VERSION ""

NS_ :

BS_:

BU_: HIB SaGE CBC DASM DIAGNOST EBCM ECM EPSB ESC ESL HALF HCP IC OCM ORC PTS RF_HUB SCCM

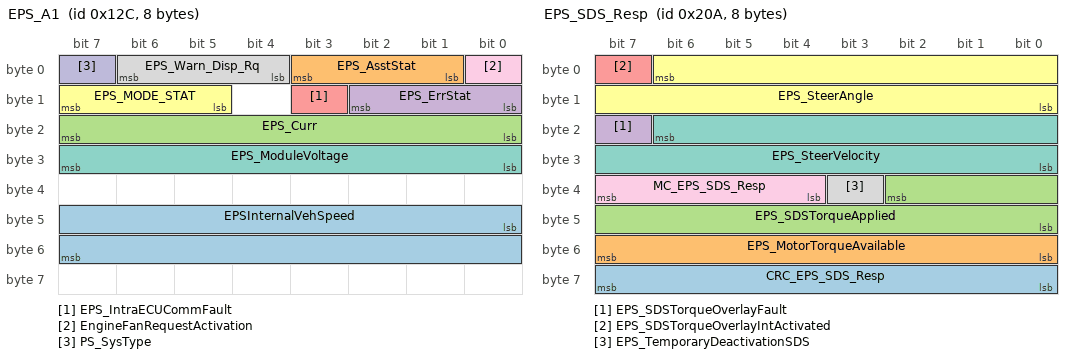
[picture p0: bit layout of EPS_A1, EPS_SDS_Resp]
BO_ 300 EPS_A1: 8 EPSB
 SG_ EPSInternalVehSpeed : 40|16@1+ (0.0078125,0) [0|511.984375] "km/h" Vector__XXX
 SG_ EPS_AsstStat : 1|3@1+ (1,0) [0|0] ""  ESC
 SG_ EPS_Curr : 16|8@1+ (1,-50) [-50|204] "Amp" Vector__XXX
 SG_ EPS_ErrStat : 8|3@1+ (1,0) [0|0] "" Vector__XXX
 SG_ EPS_IntraECUCommFault : 11|1@1+ (1,0) [0|0] "" Vector__XXX
 SG_ EPS_MODE_STAT : 13|3@1+ (1,0) [0|0] ""  CBC,HALF,ORC
 SG_ EPS_ModuleVoltage : 24|8@1+ (0.1,0) [0|25.4] "Volts" Vector__XXX
 SG_ EPS_Warn_Disp_Rq : 4|3@1+ (1,0) [0|0] ""  CBC,IC,ORC
 SG_ EngineFanRequestActivation : 0|1@1+ (1,0) [0|0] ""  ECM
 SG_ PS_SysType : 7|1@1+ (1,0) [0|0] ""  CBC,ESC

BO_ 522 EPS_SDS_Resp: 8 EPSB
 SG_ CRC_EPS_SDS_Resp : 56|8@1+ (1,0) [0|255] "" Vector__XXX
 SG_ EPS_MotorTorqueAvailable : 48|8@1+ (0.0196078,0) [0|4.9803812] "Nm" Vector__XXX
 SG_ EPS_SDSTorqueApplied : 34|11@0+ (0.00488281,-5) [-5|4.99022926] "Nm" Vector__XXX
 SG_ EPS_SDSTorqueOverlayFault : 23|1@1+ (1,0) [0|0] "" Vector__XXX
 SG_ EPS_SDSTorqueOverlayIntActivated : 7|1@1+ (1,0) [0|0] "" Vector__XXX
 SG_ EPS_SteerAngle : 6|15@0+ (0.1,-1638.3) [-1638.3|1638.3] "deg" Vector__XXX
 SG_ EPS_SteerVelocity : 22|15@0+ (0.1,-1638.3) [-1638.3|1638.3] "deg/s" Vector__XXX
 SG_ EPS_TemporaryDeactivationSDS : 35|1@1+ (1,0) [0|0] "" Vector__XXX
 SG_ MC_EPS_SDS_Resp : 36|4@1+ (1,0) [0|15] "" Vector__XXX

BO_ 320 ESP_A1: 8 ESC
 SG_ ABS_BrkEvt : 14|1@1+ (1,0) [0|0] ""  DASM,HALF,ORC,PTS
 SG_ BrkIntrvntn_Actv_AS : 6|1@1+ (1,0) [0|0] ""  DASM
 SG_ BrkIntrvntn_Actv_ESP : 5|1@1+ (1,0) [0|0] ""  HALF,ORC,PTS
 SG_ BrkIntrvntn_Enbl : 7|1@1+ (1,0) [0|0] ""  ECM,ORC
 SG_ BrkPdl_Flt : 4|1@1+ (1,0) [0|0] ""  DASM,ECM,HALF
 SG_ BrkPdl_Stat : 2|2@1+ (1,0) [0|0] ""  CBC,DASM,ECM,HALF,HCP,ORC,RF_HUB
 SG_ Brk_Stat : 0|2@1+ (1,0) [0|0] ""  CBC,DASM,ECM,HALF,PTS
 SG_ Brk_Thermdl : 25|1@1+ (1,0) [0|0] ""  DASM
 SG_ CRC_Brk_Stat : 56|8@1+ (1,0) [0|0] ""  DASM,ECM,HALF,HCP,IC,ORC,PTS
 SG_ DTR_CC_Enabled : 23|1@1+ (1,0) [0|0] ""  ECM
 SG_ DTR_CC_Engaged : 15|1@1+ (1,0) [0|0] ""  CBC,ECM,HCP
 SG_ ESP_Sys_Stat : 10|2@1+ (1,0) [0|0] ""  DASM,ECM,HALF,PTS
 SG_ EmgBrk_Actv : 8|1@1+ (1,0) [0|0] ""  ORC
 SG_ FullBrk_Actv : 9|1@1+ (1,0) [0|0] ""  ORC
 SG_ MC_Brk_Stat : 52|4@1+ (1,0) [0|15] ""  DASM,ECM,HALF,HCP,IC,ORC,PTS
 SG_ REF_VEH_SPEED : 33|10@0+ (0.5,0) [0|511] "km/h"  HCP,ORC
 SG_ RollTestMd_Actv : 30|2@1+ (1,0) [0|0] ""  DASM
 SG_ SPCR_AS_Off_Rq : 38|2@1+ (1,0) [0|0] ""  DASM,ECM

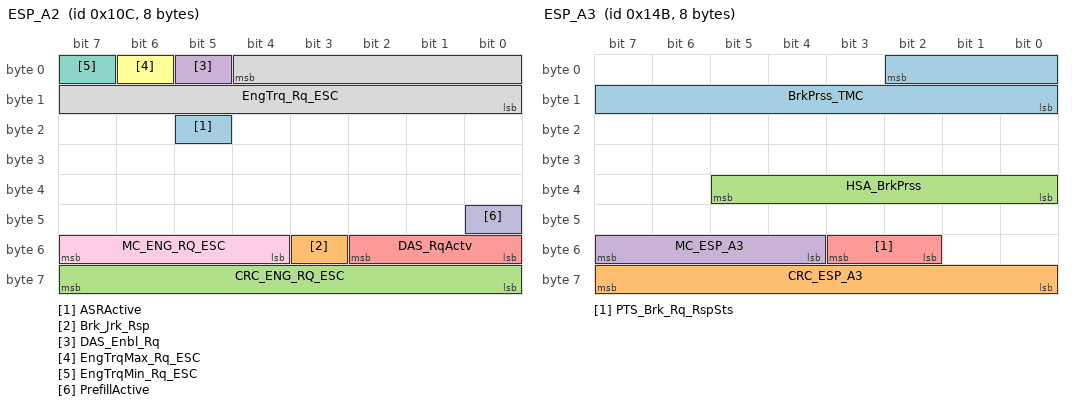
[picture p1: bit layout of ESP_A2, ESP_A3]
BO_ 268 ESP_A2: 8 HIB
 SG_ ASRActive : 21|1@1+ (1,0) [0|0] ""  DASM,ORC
 SG_ Brk_Jrk_Rsp : 51|1@1+ (1,0) [0|0] ""  DASM,ORC
 SG_ CRC_ENG_RQ_ESC : 56|8@1+ (1,0) [0|0] ""  DASM,ECM
 SG_ DAS_Enbl_Rq : 5|1@1+ (1,0) [0|0] ""  DASM,ECM
 SG_ DAS_RqActv : 48|3@1+ (1,0) [0|0] ""  DASM,HALF,ORC
 SG_ EngTrqMax_Rq_ESC : 6|1@1+ (1,0) [0|0] "" Vector__XXX
 SG_ EngTrqMin_Rq_ESC : 7|1@1+ (1,0) [0|0] "" Vector__XXX
 SG_ EngTrq_Rq_ESC : 4|13@0+ (0.25,-500) [-500|1547.5] "Nm" Vector__XXX
 SG_ MC_ENG_RQ_ESC : 52|4@1+ (1,0) [0|15] ""  DASM,ECM
 SG_ PrefillActive : 40|1@1+ (1,0) [0|0] ""  DASM

BO_ 331 ESP_A3: 8 ESC
 SG_ BrkPrss_TMC : 2|11@0+ (0.1,0) [0|200] "bar"  ECM,HALF,HCP,ORC
 SG_ CRC_ESP_A3 : 56|8@1+ (1,0) [0|0] ""  ECM,HCP,ORC,PTS
 SG_ HSA_BrkPrss : 32|6@1+ (1,0) [0|50] "bar"  ECM,ORC
 SG_ MC_ESP_A3 : 52|4@1+ (1,0) [0|15] ""  ECM,HCP,ORC,PTS
 SG_ PTS_Brk_Rq_RspSts : 50|2@1+ (1,0) [0|0] ""  IC,PTS

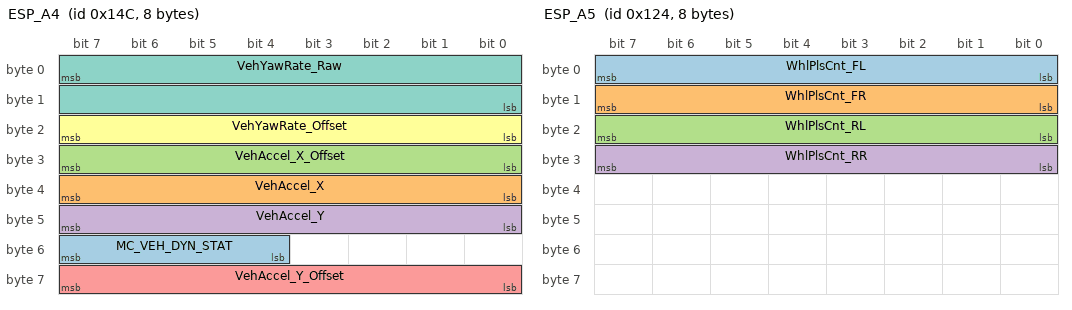
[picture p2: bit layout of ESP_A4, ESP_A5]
BO_ 332 ESP_A4: 8 ESC
 SG_ MC_VEH_DYN_STAT : 52|4@1+ (1,0) [0|15] ""  DASM,ECM,HALF,ORC,PTS
 SG_ VehAccel_X : 32|8@1+ (0.08,-10.24) [-10.24|10.08] "m/s²"  EBCM,CBC,DASM,ECM,HALF,HCP,PTS
 SG_ VehAccel_X_Offset : 24|8@1+ (0.02,-2.56) [-2.56|2.52] "m/s²"  EBCM,DASM,ECM,HALF,HCP,PTS
 SG_ VehAccel_Y : 40|8@1+ (0.08,-10.24) [-10.24|10.08] "m/s²"  DASM,ECM,EPSB,HALF,HCP
 SG_ VehAccel_Y_Offset : 56|8@1+ (0.02,-2.56) [-2.56|2.52] "m/s²"  DASM,ECM,HALF,HCP
 SG_ VehYawRate_Offset : 16|8@1+ (0.08,-10.24) [-6.96|6.96] ""  DASM,HALF,ORC
 SG_ VehYawRate_Raw : 7|16@0+ (0.01,-327.68) [-327.68|327.66] "°/s"  CBC,DASM,HALF,PTS

BO_ 292 ESP_A5: 8 ESC
 SG_ WhlPlsCnt_FL : 0|8@1+ (1,0) [0|254] "Impulse"  CBC,DASM,PTS,RF_HUB
 SG_ WhlPlsCnt_FR : 8|8@1+ (1,0) [0|254] "Impulse"  CBC,DASM,PTS,RF_HUB
 SG_ WhlPlsCnt_RL : 16|8@1+ (1,0) [0|254] "Impulse"  CBC,DASM,EPSB,PTS,RF_HUB
 SG_ WhlPlsCnt_RR : 24|8@1+ (1,0) [0|254] "Impulse"  CBC,DASM,EPSB,PTS,RF_HUB

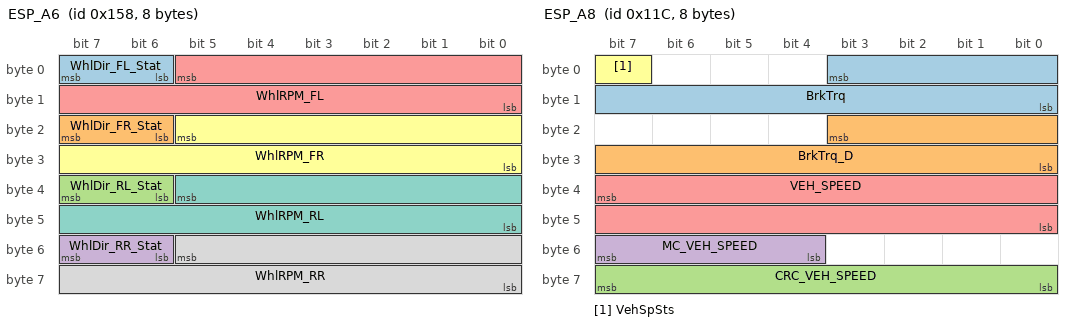
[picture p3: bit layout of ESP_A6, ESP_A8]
BO_ 344 ESP_A6: 8 ESC
 SG_ WhlDir_FL_Stat : 6|2@1+ (1,0) [0|0] ""  DASM,HCP
 SG_ WhlDir_FR_Stat : 22|2@1+ (1,0) [0|0] ""  DASM,HCP
 SG_ WhlDir_RL_Stat : 38|2@1+ (1,0) [0|0] ""  DASM,EPSB,HCP,ORC,PTS
 SG_ WhlDir_RR_Stat : 54|2@1+ (1,0) [0|0] ""  DASM,EPSB,HCP,ORC,PTS
 SG_ WhlRPM_FL : 5|14@0+ (0.5,0) [0|8191] "rpm"  DASM,HCP,ORC,PTS
 SG_ WhlRPM_FR : 21|14@0+ (0.5,0) [0|8191] "rpm"  DASM,HCP,ORC,PTS
 SG_ WhlRPM_RL : 37|14@0+ (0.5,0) [0|8191] "rpm"  DASM,HCP,ORC,PTS
 SG_ WhlRPM_RR : 53|14@0+ (0.5,0) [0|8191] "rpm"  DASM,HCP,ORC,PTS

BO_ 284 ESP_A8: 8 ESC
 SG_ BrkTrq : 3|12@0+ (3,0) [0|12282] "Nm"  DASM,ORC
 SG_ BrkTrq_D : 19|12@0+ (3,0) [0|12282] "Nm"  DASM
 SG_ CRC_VEH_SPEED : 56|8@1+ (1,0) [0|0] ""  DASM,EBCM,ECM,EPSB,ESL,HALF,HCP,IC,ORC,PTS
 SG_ MC_VEH_SPEED : 52|4@1+ (1,0) [0|15] ""  DASM,EBCM,ECM,EPSB,ESL,HALF,HCP,IC,ORC,PTS
 SG_ VEH_SPEED : 39|16@0+ (0.0078125,0) [0|511.984375] "km/h"  CBC,DASM,EBCM,ECM,EPSB,ESL,HALF,HCP,IC,ORC,PTS,RF_HUB
 SG_ VehSpSts : 7|1@1+ (1,0) [0|0] ""  DASM

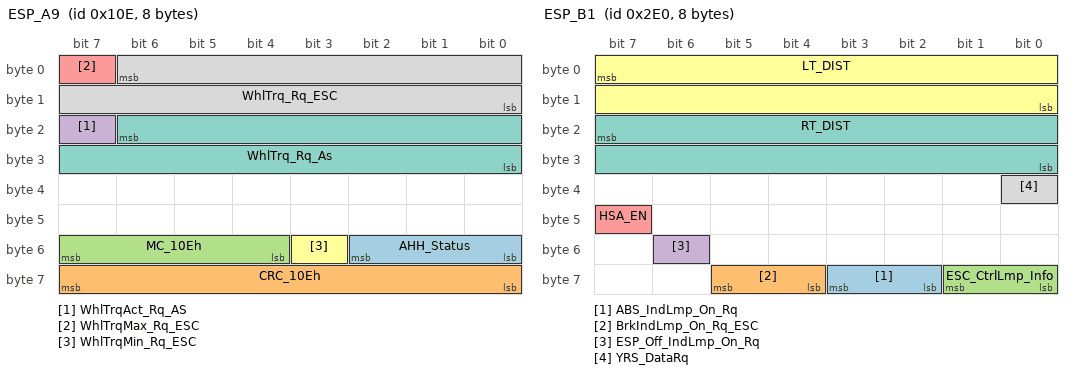
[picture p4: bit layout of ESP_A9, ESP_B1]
BO_ 270 ESP_A9: 8 ESC
 SG_ AHH_Status : 48|3@1+ (1,0) [0|0] ""  HCP
 SG_ CRC_10Eh : 56|8@1+ (1,0) [0|255] ""  DASM,ECM
 SG_ MC_10Eh : 52|4@1+ (1,0) [0|15] ""  DASM,ECM
 SG_ WhlTrqAct_Rq_AS : 23|1@1+ (1,0) [0|0] ""  ECM
 SG_ WhlTrqMax_Rq_ESC : 7|1@1+ (1,0) [0|0] ""  DASM,ECM
 SG_ WhlTrqMin_Rq_ESC : 51|1@1+ (1,0) [0|0] ""  ECM
 SG_ WhlTrq_Rq_As : 22|15@0+ (1,-7767) [-7767|24999] "Nm"  ECM,ORC
 SG_ WhlTrq_Rq_ESC : 6|15@0+ (1,-7767) [-7767|24999] "Nm"  DASM,ECM

BO_ 736 ESP_B1: 8 ESC
 SG_ ABS_IndLmp_On_Rq : 58|2@1+ (1,0) [0|0] ""  IC
 SG_ BrkIndLmp_On_Rq_ESC : 60|2@1+ (1,0) [0|0] ""  IC,ORC
 SG_ ESC_CtrlLmp_Info : 56|2@1+ (1,0) [0|0] ""  IC,ORC
 SG_ ESP_Off_IndLmp_On_Rq : 54|1@1+ (1,0) [0|0] ""  CBC,IC,ORC
 SG_ HSA_EN : 47|1@1+ (1,0) [0|0] ""  CBC
 SG_ LT_DIST : 7|16@0+ (4,0) [0|262136] "cm"  CBC,ECM,IC,PTS
 SG_ RT_DIST : 23|16@0+ (4,0) [0|262136] "cm"  CBC,ECM,IC,PTS
 SG_ YRS_DataRq : 32|1@1+ (1,0) [0|0] ""  ORC

BO_ 840 ESP_C1: 8 ESC
 SG_ FailSafeError : 7|16@0+ (1,0) [0|65534] ""  DASM

BO_ 710 EcuCfg17: 8 CBC
 SG_ EC_ECUCfg17_Stat : 0|2@1+ (1,0) [0|0] ""  PTS,RF_HUB
 SG_ EC_PTS : 56|8@1+ (1,0) [0|0] ""  PTS,RF_HUB

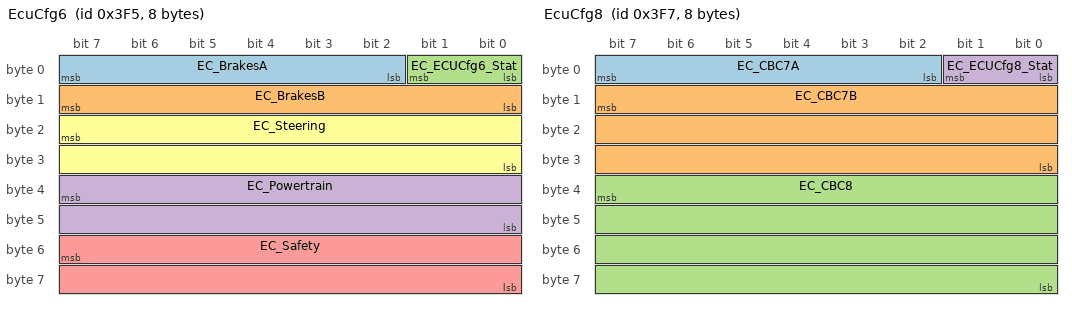
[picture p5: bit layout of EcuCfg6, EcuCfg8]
BO_ 1013 EcuCfg6: 8 CBC
 SG_ EC_BrakesA : 2|6@1+ (1,0) [0|0] ""  ESC,RF_HUB
 SG_ EC_BrakesB : 8|8@1+ (1,0) [0|0] ""  ESC,RF_HUB
 SG_ EC_ECUCfg6_Stat : 0|2@1+ (1,0) [0|0] ""  ECM,EPSB,ESC,ORC,RF_HUB
 SG_ EC_Powertrain : 39|16@0+ (1,0) [0|0] ""  RF_HUB
 SG_ EC_Safety : 55|16@0+ (1,0) [0|0] ""  ORC,RF_HUB
 SG_ EC_Steering : 23|16@0+ (1,0) [0|0] ""  EPSB,RF_HUB

BO_ 1015 EcuCfg8: 8 CBC
 SG_ EC_CBC7A : 2|6@1+ (1,0) [0|0] ""  RF_HUB
 SG_ EC_CBC7B : 15|24@0+ (1,0) [0|0] ""  RF_HUB
 SG_ EC_CBC8 : 39|32@0+ (1,0) [0|0] ""  RF_HUB
 SG_ EC_ECUCfg8_Stat : 0|2@1+ (1,0) [0|0] ""  RF_HUB

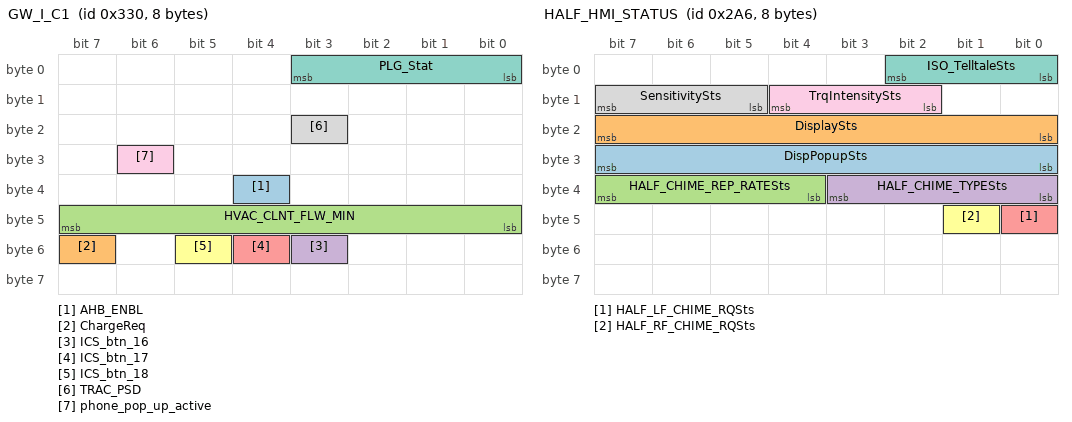
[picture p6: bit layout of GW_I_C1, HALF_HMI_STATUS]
BO_ 816 GW_I_C1: 8 CBC
 SG_ AHB_ENBL : 36|1@1+ (1,0) [0|0] "" Vector__XXX
 SG_ ChargeReq : 55|1@1+ (1,0) [0|0] ""  HCP,IC
 SG_ HVAC_CLNT_FLW_MIN : 40|8@1+ (0.521555,0) [0.521555|131.953415] "LpM" Vector__XXX
 SG_ ICS_btn_16 : 51|1@1+ (1,0) [0|0] ""  PTS
 SG_ ICS_btn_17 : 52|1@1+ (1,0) [0|0] ""  PTS
 SG_ ICS_btn_18 : 53|1@1+ (1,0) [0|0] ""  HALF
 SG_ PLG_Stat : 0|4@1+ (1,0) [0|0] ""  IC
 SG_ TRAC_PSD : 19|1@1+ (1,0) [0|0] ""  ESC,IC
 SG_ phone_pop_up_active : 30|1@1+ (1,0) [0|0] ""  IC

BO_ 678 HALF_HMI_STATUS: 8 HALF
 SG_ DispPopupSts : 24|8@1+ (1,0) [0|0] ""  IC,ORC
 SG_ DisplaySts : 16|8@1+ (1,0) [0|0] ""  IC,ORC
 SG_ HALF_CHIME_REP_RATESts : 36|4@1+ (1,0) [0|15] ""  CBC
 SG_ HALF_CHIME_TYPESts : 32|4@1+ (1,0) [0|0] ""  CBC
 SG_ HALF_LF_CHIME_RQSts : 40|1@1+ (1,0) [0|0] ""  CBC
 SG_ HALF_RF_CHIME_RQSts : 41|1@1+ (1,0) [0|0] ""  CBC
 SG_ ISO_TelltaleSts : 0|3@1+ (1,0) [0|0] ""  IC,ORC
 SG_ SensitivitySts : 13|3@1+ (1,0) [0|0] ""  IC
 SG_ TrqIntensitySts : 10|3@1+ (1,0) [0|0] ""  IC

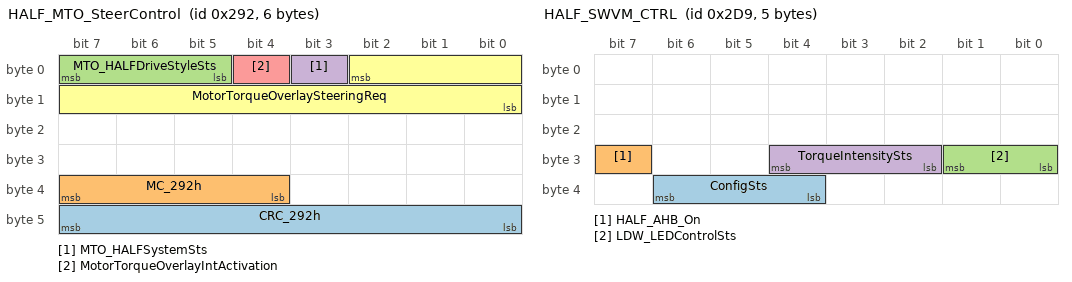
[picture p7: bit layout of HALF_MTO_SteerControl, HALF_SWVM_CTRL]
BO_ 658 HALF_MTO_SteerControl: 6 HALF
 SG_ CRC_292h : 40|8@1+ (1,0) [0|0] ""  EPSB
 SG_ MC_292h : 36|4@1+ (1,0) [0|15] ""  EPSB
 SG_ MTO_HALFDriveStyleSts : 5|3@1+ (1,0) [0|0] ""  EPSB
 SG_ MTO_HALFSystemSts : 3|1@1+ (1,0) [0|0] ""  EPSB
 SG_ MotorTorqueOverlayIntActivation : 4|1@1+ (1,0) [0|0] ""  EPSB
 SG_ MotorTorqueOverlaySteeringReq : 2|11@0+ (0.001953125,-2) [-2|1.998047] "Nm"  EPSB

BO_ 729 HALF_SWVM_CTRL: 5 HALF
 SG_ ConfigSts : 36|3@1+ (1,0) [0|0] ""  CBC
 SG_ HALF_AHB_On : 31|1@1+ (1,0) [0|0] ""  CBC
 SG_ LDW_LEDControlSts : 24|2@1+ (1,0) [0|0] ""  CBC
 SG_ TorqueIntensitySts : 26|3@1+ (1,0) [0|0] ""  CBC

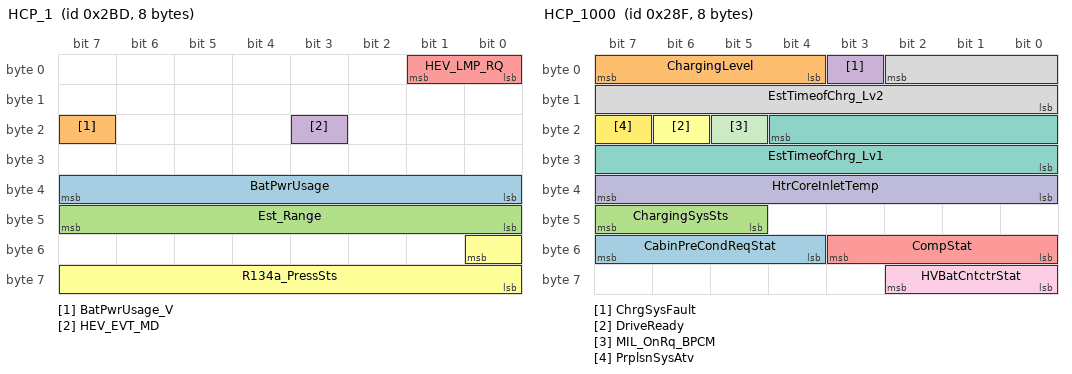
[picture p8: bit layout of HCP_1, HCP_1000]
BO_ 701 HCP_1: 8 HCP
 SG_ BatPwrUsage : 32|8@1+ (1,-125) [-125|130] "kW"  IC
 SG_ BatPwrUsage_V : 23|1@1+ (1,0) [0|0] ""  IC
 SG_ Est_Range : 40|8@1+ (1,0) [0|254] "km"  IC
 SG_ HEV_EVT_MD : 19|1@1+ (1,0) [0|0] ""  CBC,DASM,IC
 SG_ HEV_LMP_RQ : 0|2@1+ (1,0) [0|0] ""  IC,ORC
 SG_ R134a_PressSts : 48|9@0+ (0.1,0) [0|40] "bar"  CBC

BO_ 655 HCP_1000: 8 HCP
 SG_ CabinPreCondReqStat : 52|4@1+ (1,0) [0|0] "" Vector__XXX
 SG_ ChargingLevel : 4|4@1+ (1,0) [0|0] ""  CBC,IC
 SG_ ChargingSysSts : 45|3@1+ (1,0) [0|0] ""  IC
 SG_ ChrgSysFault : 3|1@1+ (1,0) [0|0] ""  IC
 SG_ CompStat : 48|4@1+ (1,0) [0|0] ""  CBC
 SG_ DriveReady : 22|1@1+ (1,0) [0|0] ""  CBC,DASM,IC
 SG_ EstTimeofChrg_Lv1 : 20|13@0+ (1,0) [0|8190] "min"  IC
 SG_ EstTimeofChrg_Lv2 : 2|11@0+ (1,0) [0|2046] "min"  IC
 SG_ HVBatCntctrStat : 56|3@1+ (1,0) [0|0] ""  IC
 SG_ HtrCoreInletTemp : 32|8@1+ (1,-40) [-40|214] "°C"  CBC,ECM
 SG_ MIL_OnRq_BPCM : 21|1@1+ (1,0) [0|0] ""  IC
 SG_ PrplsnSysAtv : 23|1@1+ (1,0) [0|0] ""  CBC,ECM,EPSB,ESC,HCP,IC,PTS,RF_HUB

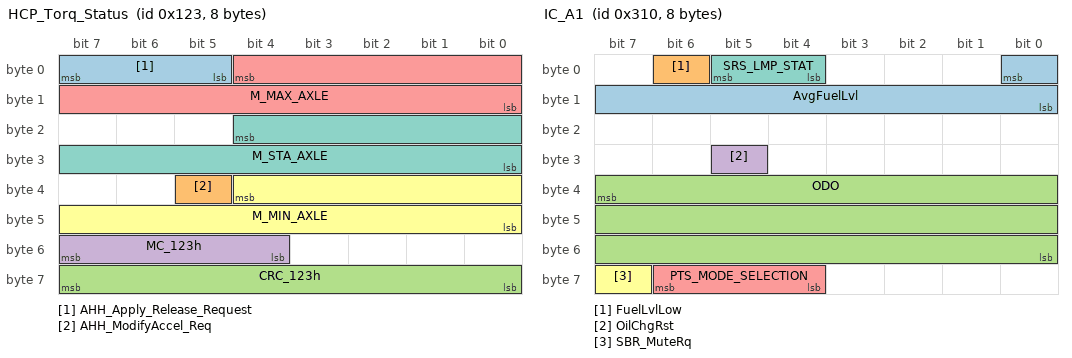
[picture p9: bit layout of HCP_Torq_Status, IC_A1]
BO_ 291 HCP_Torq_Status: 8 HCP
 SG_ AHH_Apply_Release_Request : 5|3@1+ (1,0) [0|0] ""  ESC
 SG_ AHH_ModifyAccel_Req : 37|1@1+ (1,0) [0|0] ""  ECM
 SG_ CRC_123h : 56|8@1+ (1,0) [0|255] ""  DASM,ESC
 SG_ MC_123h : 52|4@1+ (1,0) [0|15] ""  DASM,ESC
 SG_ M_MAX_AXLE : 4|13@0+ (4,-7767) [-7767|24993] ""  DASM,ESC
 SG_ M_MIN_AXLE : 36|13@0+ (4,-7767) [-7767|24993] ""  DASM,ESC
 SG_ M_STA_AXLE : 20|13@0+ (4,-7767) [-7767|24993] ""  DASM,ECM,ESC,ORC

BO_ 784 IC_A1: 8 IC
 SG_ AvgFuelLvl : 0|9@0+ (0.5,0) [0|255] "liters"  CBC
 SG_ FuelLvlLow : 6|1@1+ (1,0) [0|0] ""  CBC,ECM
 SG_ ODO : 39|24@0+ (0.1,0) [0|1677721.4] "km"  CBC,DASM,EBCM,ECM,EPSB,ESC,ESL,HALF,HCP,OCM,ORC,PTS,RF_HUB,SCCM
 SG_ OilChgRst : 29|1@1+ (1,0) [0|0] ""  ECM
 SG_ PTS_MODE_SELECTION : 60|3@1+ (1,0) [0|0] ""  PTS
 SG_ SBR_MuteRq : 63|1@1+ (1,0) [0|0] ""  CBC
 SG_ SRS_LMP_STAT : 4|2@1+ (1,0) [0|0] ""  ORC

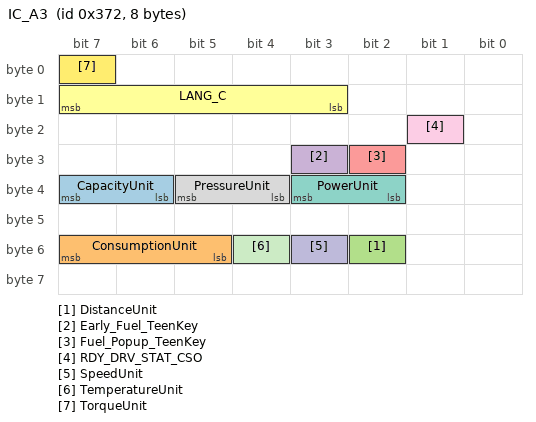
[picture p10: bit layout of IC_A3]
BO_ 882 IC_A3: 8 IC
 SG_ CapacityUnit : 38|2@1+ (1,0) [0|0] ""  CBC
 SG_ ConsumptionUnit : 53|3@1+ (1,0) [0|0] ""  CBC
 SG_ DistanceUnit : 50|1@1+ (1,0) [0|0] ""  CBC
 SG_ Early_Fuel_TeenKey : 27|1@1+ (1,0) [0|0] ""  CBC
 SG_ Fuel_Popup_TeenKey : 26|1@1+ (1,0) [0|0] ""  CBC
 SG_ LANG_C : 11|5@1+ (1,0) [0|0] ""  CBC
 SG_ PowerUnit : 34|2@1+ (1,0) [0|0] ""  CBC
 SG_ PressureUnit : 36|2@1+ (1,0) [0|0] ""  CBC
 SG_ RDY_DRV_STAT_CSO : 17|1@1+ (1,0) [0|0] ""  CBC
 SG_ SpeedUnit : 51|1@1+ (1,0) [0|0] ""  CBC,DASM,ECM
 SG_ TemperatureUnit : 52|1@1+ (1,0) [0|0] ""  CBC
 SG_ TorqueUnit : 7|1@1+ (1,0) [0|0] ""  CBC

BO_ 995 NET_CFG_INT: 8 CBC
 SG_ NET_CFG_STAT_INT : 0|2@1+ (1,0) [0|0] ""  IC,RF_HUB
 SG_ NetCfg_AMP_I : 24|1@1+ (1,0) [0|0] ""  RF_HUB
 SG_ NetCfg_ANC_I : 39|1@1+ (1,0) [0|0] ""  RF_HUB
 SG_ NetCfg_BSM : 3|1@1+ (1,0) [0|0] ""  DASM,IC,RF_HUB
 SG_ NetCfg_CBC_IN : 4|1@1+ (1,0) [0|0] ""  RF_HUB
 SG_ NetCfg_CLOCK : 21|1@1+ (1,0) [0|0] ""  RF_HUB
 SG_ NetCfg_CRSM : 30|1@1+ (1,0) [0|0] ""  RF_HUB
 SG_ NetCfg_CSWM : 5|1@1+ (1,0) [0|0] ""  RF_HUB
 SG_ NetCfg_CVPM : 32|1@1+ (1,0) [0|0] ""  RF_HUB
 SG_ NetCfg_DCM_DR : 6|1@1+ (1,0) [0|0] ""  RF_HUB
 SG_ NetCfg_DCM_PASS : 7|1@1+ (1,0) [0|0] ""  RF_HUB
 SG_ NetCfg_DCM_RL : 8|1@1+ (1,0) [0|0] ""  RF_HUB
 SG_ NetCfg_DCM_RR : 9|1@1+ (1,0) [0|0] ""  RF_HUB
 SG_ NetCfg_DCSD : 37|1@1+ (1,0) [0|0] ""  RF_HUB
 SG_ NetCfg_DTV : 19|1@1+ (1,0) [0|0] ""  RF_HUB
 SG_ NetCfg_DVD_CDM : 25|1@1+ (1,0) [0|0] ""  RF_HUB
 SG_ NetCfg_FSM : 16|1@1+ (1,0) [0|0] ""  RF_HUB
 SG_ NetCfg_HFM_CTM : 26|1@1+ (1,0) [0|0] ""  RF_HUB
 SG_ NetCfg_HVAC : 10|1@1+ (1,0) [0|0] ""  RF_HUB
 SG_ NetCfg_HVAC_R : 31|1@1+ (1,0) [0|0] ""  RF_HUB
 SG_ NetCfg_ICS_I : 27|1@1+ (1,0) [0|0] ""  RF_HUB
 SG_ NetCfg_ICS_R : 34|1@1+ (1,0) [0|0] ""  RF_HUB
 SG_ NetCfg_ITM : 23|1@1+ (1,0) [0|0] ""  RF_HUB
 SG_ NetCfg_MSM : 11|1@1+ (1,0) [0|0] ""  RF_HUB
 SG_ NetCfg_MSM_PASS : 35|1@1+ (1,0) [0|0] ""  RF_HUB
 SG_ NetCfg_PLG : 12|1@1+ (1,0) [0|0] ""  RF_HUB
 SG_ NetCfg_PSD_LT : 14|1@1+ (1,0) [0|0] ""  RF_HUB
 SG_ NetCfg_PSD_RT : 15|1@1+ (1,0) [0|0] ""  RF_HUB
 SG_ NetCfg_PTCM : 17|1@1+ (1,0) [0|0] ""  RF_HUB
 SG_ NetCfg_RBC : 18|1@1+ (1,0) [0|0] ""  RF_HUB
 SG_ NetCfg_RBSS : 2|1@1+ (1,0) [0|0] ""  RF_HUB
 SG_ NetCfg_TBM : 38|1@1+ (1,0) [0|0] ""  RF_HUB
 SG_ NetCfg_TGW : 20|1@1+ (1,0) [0|0] ""  HALF,RF_HUB
 SG_ NetCfg_TMM : 33|1@1+ (1,0) [0|0] ""  RF_HUB
 SG_ NetCfg_TTM : 47|1@1+ (1,0) [0|0] ""  RF_HUB
 SG_ NetCfg_VES2_I : 28|1@1+ (1,0) [0|0] ""  RF_HUB
 SG_ NetCfg_VES3_I : 29|1@1+ (1,0) [0|0] ""  RF_HUB
 SG_ NetCfg_VRM : 36|1@1+ (1,0) [0|0] ""  RF_HUB
 SG_ NetCfg_VSIM : 22|1@1+ (1,0) [0|0] ""  RF_HUB
 SG_ NetCfg_VTM : 13|1@1+ (1,0) [0|0] ""  RF_HUB

CM_ SG_ 300 EPSInternalVehSpeed "Vehicle Speed value EPS is using internally to calculate boost level and SDS torque limits";
CM_ SG_ 300 EPS_AsstStat "Electric Power Steering Assistance Status";
CM_ SG_ 300 EPS_Curr "Electric power steering current";
CM_ SG_ 300 EPS_ErrStat "Individual ECU Fault Status";
CM_ SG_ 300 EPS_IntraECUCommFault "EPS Internal ECU-ECU Fault Status, OK = [0], Fault = [1];";
CM_ SG_ 300 EPS_MODE_STAT "EPS mode personalization status";
CM_ SG_ 300 EPS_ModuleVoltage "Electric power steering voltage";
CM_ SG_ 300 EPS_Warn_Disp_Rq "Electric power steering warning display request";
CM_ SG_ 300 EngineFanRequestActivation "Engine fan activation request for cooling; True = [1]";
CM_ SG_ 300 PS_SysType "Power steering system type; EHPS = [0]: EPS = [1]";
CM_ SG_ 522 CRC_EPS_SDS_Resp "CRC-checksum byte 1 to 7 according to SAE J1850";
CM_ SG_ 522 EPS_MotorTorqueAvailable "EPS Motor Torque Available for SDS under current conditions";
CM_ SG_ 522 EPS_SDSTorqueApplied "EPS Motor Torque Applied for SDS";
CM_ SG_ 522 EPS_SDSTorqueOverlayFault "Fault of the SDS torque overlay interface, False = [0], True = [1];";
CM_ SG_ 522 EPS_SDSTorqueOverlayIntActivated "Activation Status of the SDS torque overlay interface, False = [0], True = [1];";
CM_ SG_ 522 EPS_SteerAngle "Steer Angle based on EPS Motor Position sensor - relative angle from key on";
CM_ SG_ 522 EPS_SteerVelocity "Steer Velocity based on EPS Motor Position sensor - relative angle from key on";
CM_ SG_ 522 EPS_TemporaryDeactivationSDS "Temporary deactivation of the EPS SDS torque overlay function, False = [0], True = [1];";
CM_ SG_ 522 MC_EPS_SDS_Resp "Message counter";
CM_ SG_ 320 ABS_BrkEvt "Any ABS brake event";
CM_ SG_ 320 BrkIntrvntn_Actv_AS "Brake intervention by assistance system active";
CM_ SG_ 320 BrkIntrvntn_Actv_ESP "Brake intervention by ESP active";
CM_ SG_ 320 BrkIntrvntn_Enbl "Brake intervention enabled";
CM_ SG_ 320 BrkPdl_Flt "Brake Pedal Fault is active, 1=Faulted";
CM_ SG_ 320 BrkPdl_Stat "Brake pedal state";
CM_ SG_ 320 Brk_Stat "Brake state";
CM_ SG_ 320 Brk_Thermdl "Brake thermal over target";
CM_ SG_ 320 CRC_Brk_Stat "CRC-checksum byte 1 to 7 according to SAE J1850";
CM_ SG_ 320 DTR_CC_Enabled "ACC is enabled; True = [1]";
CM_ SG_ 320 DTR_CC_Engaged "ACC is engaged; True = [1]";
CM_ SG_ 320 ESP_Sys_Stat "ESP system state";
CM_ SG_ 320 EmgBrk_Actv "Emergency braking";
CM_ SG_ 320 FullBrk_Actv "Maximum (hard) braking (ALS controls all wheels)";
CM_ SG_ 320 MC_Brk_Stat "Message counter";
CM_ SG_ 320 REF_VEH_SPEED "Reference vehicle actual speed";
CM_ SG_ 320 RollTestMd_Actv "Roller test bench mode active";
CM_ SG_ 320 SPCR_AS_Off_Rq "Assistance system off request";
CM_ SG_ 268 ASRActive "Traction control is active";
CM_ SG_ 268 Brk_Jrk_Rsp "Brake jerk response; True = [1]";
CM_ SG_ 268 CRC_ENG_RQ_ESC "CRC-checksum byte 1 to 7 according to SAE J1850";
CM_ SG_ 268 DAS_Enbl_Rq "Enable DAS request; True = [1]";
CM_ SG_ 268 DAS_RqActv "DAS request active";
CM_ SG_ 268 EngTrqMax_Rq_ESC "Engine torque request maximum";
CM_ SG_ 268 EngTrqMin_Rq_ESC "Engine torque request minimum";
CM_ SG_ 268 EngTrq_Rq_ESC "Engine torque request";
CM_ SG_ 268 MC_ENG_RQ_ESC "Message counter";
CM_ SG_ 268 PrefillActive "Brake prefill is active - True = [1]";
CM_ SG_ 331 BrkPrss_TMC "Master cylinder pressure";
CM_ SG_ 331 CRC_ESP_A3 "CRC-checksum byte 1 to 7 according to SAE J1850";
CM_ SG_ 331 HSA_BrkPrss "Hill start assist brake pressure";
CM_ SG_ 331 MC_ESP_A3 "Message counter";
CM_ SG_ 331 PTS_Brk_Rq_RspSts "Brake request response status by ESC for park stop & release";
CM_ SG_ 332 MC_VEH_DYN_STAT "Message counter";
CM_ SG_ 332 VehAccel_X "Vehicle longitudinal acceleration (+ means forward)";
CM_ SG_ 332 VehAccel_X_Offset "Offset of vehicle longitudinal acceleration (+ means forward)";
CM_ SG_ 332 VehAccel_Y "Vehicle lateral acceleration (+ means left, specific to center of gravity, offset-corrected )";
CM_ SG_ 332 VehAccel_Y_Offset "Offset of vehicle lateral acceleration (+ means left)";
CM_ SG_ 332 VehYawRate_Offset "Offset of vehicle yaw rate unfiltered/unadjusted (+ means left)";
CM_ SG_ 332 VehYawRate_Raw "Vehicle yaw rate unfiltered/unadjusted (+ means left)";
CM_ SG_ 292 WhlPlsCnt_FL "Wheel pulse counter front left (96 per rotation)";
CM_ SG_ 292 WhlPlsCnt_FR "Wheel pulse counter front right (96 per rotation)";
CM_ SG_ 292 WhlPlsCnt_RL "Wheel pulse counter rear left (96 per rotation)";
CM_ SG_ 292 WhlPlsCnt_RR "Wheel pulse counter rear right (96 per rotation)";
CM_ SG_ 344 WhlDir_FL_Stat "Direction of rotation of front left wheel";
CM_ SG_ 344 WhlDir_FR_Stat "Direction of rotation of front right wheel";
CM_ SG_ 344 WhlDir_RL_Stat "Direction of rotation of rear left wheel";
CM_ SG_ 344 WhlDir_RR_Stat "Direction of rotation of rear right wheel";
CM_ SG_ 344 WhlRPM_FL "Wheel rpm front left";
CM_ SG_ 344 WhlRPM_FR "Wheel rpm front right";
CM_ SG_ 344 WhlRPM_RL "Wheel rpm rear left";
CM_ SG_ 344 WhlRPM_RR "Wheel rpm rear right";
CM_ SG_ 284 BrkTrq "Actual brake torque";
CM_ SG_ 284 BrkTrq_D "Brake torque requested by driver";
CM_ SG_ 284 CRC_VEH_SPEED "CRC-checksum byte 1 to 7 according to SAE J1850";
CM_ SG_ 284 MC_VEH_SPEED "Message counter";
CM_ SG_ 284 VEH_SPEED "Vehicle speed";
CM_ SG_ 284 VehSpSts "Vehicle is stopped status signal";
CM_ SG_ 270 AHH_Status "AHH status";
CM_ SG_ 270 CRC_10Eh "CRC-checksum byte 1 to 7 according to SAE J1850";
CM_ SG_ 270 MC_10Eh "Message counter";
CM_ SG_ 270 WhlTrqAct_Rq_AS "Wheel torque request active; True = [1]";
CM_ SG_ 270 WhlTrqMax_Rq_ESC "Wheel torque request maximum";
CM_ SG_ 270 WhlTrqMin_Rq_ESC "Wheel torque request minimum";
CM_ SG_ 270 WhlTrq_Rq_As "Wheel torque request";
CM_ SG_ 270 WhlTrq_Rq_ESC "Wheel torque request";
CM_ SG_ 736 ABS_IndLmp_On_Rq "ABS indication lamp on request";
CM_ SG_ 736 BrkIndLmp_On_Rq_ESC "Brake indication lamp (red) on request";
CM_ SG_ 736 ESC_CtrlLmp_Info "ESC control lamp information";
CM_ SG_ 736 ESP_Off_IndLmp_On_Rq "ESP-OFF indication lamp on request";
CM_ SG_ 736 HSA_EN "Hill Start Assist enabled (1=enabled)";
CM_ SG_ 736 LT_DIST "Distance Traveled by Left Wheel";
CM_ SG_ 736 RT_DIST "Distance Traveled by Right Wheel";
CM_ SG_ 736 YRS_DataRq "Request from ESC for YRS information";
CM_ SG_ 840 FailSafeError "Fail safe error";
CM_ SG_ 710 EC_ECUCfg17_Stat "ECU Configuration messages status 17";
CM_ SG_ 710 EC_PTS "Park assist ecu configuration";
CM_ SG_ 1013 EC_BrakesA "Brake system ecu configurationA";
CM_ SG_ 1013 EC_BrakesB "Brake system ecu configurationB";
CM_ SG_ 1013 EC_ECUCfg6_Stat "ECU Configuration messages status 6";
CM_ SG_ 1013 EC_Powertrain "Powertrain ecu configuration";
CM_ SG_ 1013 EC_Safety "Safety ecu configuration";
CM_ SG_ 1013 EC_Steering "Steering ecu configuration";
CM_ SG_ 1015 EC_CBC7A "CBC ecu configuration 7A";
CM_ SG_ 1015 EC_CBC7B "CBC ecu configuration 7B";
CM_ SG_ 1015 EC_CBC8 "CBC ecu configuration 8";
CM_ SG_ 1015 EC_ECUCfg8_Stat "ECU Configuration messages status 8";
CM_ SG_ 816 AHB_ENBL "Auto highbeam enable";
CM_ SG_ 816 ChargeReq "Request for scheduled charge; Charge now = [1]";
CM_ SG_ 816 HVAC_CLNT_FLW_MIN "HVAC coolant flow minimum request";
CM_ SG_ 816 ICS_btn_16 "PPA pressed";
CM_ SG_ 816 ICS_btn_17 "PTS Off pressed";
CM_ SG_ 816 ICS_btn_18 "LDW Off pressed";
CM_ SG_ 816 PLG_Stat "Power liftgate status";
CM_ SG_ 816 TRAC_PSD "Traction on/off button pressed; [0] = Not Pressed, [1] = Pressed";
CM_ SG_ 816 phone_pop_up_active "Phone pop up is active; True = [1]";
CM_ SG_ 678 DispPopupSts "LDW message status in cluster";
CM_ SG_ 678 DisplaySts "LDW display status in cluster";
CM_ SG_ 678 HALF_CHIME_REP_RATESts "LDW chime repetition rate; Continuous = [0]";
CM_ SG_ 678 HALF_CHIME_TYPESts "LDW chime type";
CM_ SG_ 678 HALF_LF_CHIME_RQSts "LDW chime request for left side; true = [1]";
CM_ SG_ 678 HALF_RF_CHIME_RQSts "LDW chime request for right side; true = [1]";
CM_ SG_ 678 ISO_TelltaleSts "LDW telltale status in cluster";
CM_ SG_ 678 SensitivitySts "LDW sensitivity level for display in cluster";
CM_ SG_ 678 TrqIntensitySts "LDW torque intesity level for display in cluster";
CM_ SG_ 658 CRC_292h "CRC-checksum byte 1 to 5 according to SAE J1850";
CM_ SG_ 658 MC_292h "Message counter";
CM_ SG_ 658 MTO_HALFDriveStyleSts "HaLF drive style status acknowledgement";
CM_ SG_ 658 MTO_HALFSystemSts "HaLF system status; Faulted = [1]";
CM_ SG_ 658 MotorTorqueOverlayIntActivation "Torques overlay interface activation; Active = [1]";
CM_ SG_ 658 MotorTorqueOverlaySteeringReq "HaLF torque overlay steering request";
CM_ SG_ 729 ConfigSts "LDW sensitivity level";
CM_ SG_ 729 HALF_AHB_On "Auto high beam on request from the HALF ECU";
CM_ SG_ 729 LDW_LEDControlSts "LDW switch LED status";
CM_ SG_ 729 TorqueIntensitySts "LDW Torque Intesity Level";
CM_ SG_ 701 BatPwrUsage ".";
CM_ SG_ 701 BatPwrUsage_V ".";
CM_ SG_ 701 Est_Range "Estimated electric range sent to HMI";
CM_ SG_ 701 HEV_EVT_MD "The system is in EVT mode; Hybrid mode = [0], EV Mode = [1]";
CM_ SG_ 701 HEV_LMP_RQ "HEV service lamp request";
CM_ SG_ 701 R134a_PressSts "Refrigerant pressure (R134a or R1234YF)";
CM_ SG_ 655 CabinPreCondReqStat "Cabin Preconditioning Request Status";
CM_ SG_ 655 ChargingLevel "Charging level and type.";
CM_ SG_ 655 ChargingSysSts "Charging System status";
CM_ SG_ 655 ChrgSysFault "Charging System Fault status";
CM_ SG_ 655 CompStat "comppressor state";
CM_ SG_ 655 DriveReady "Ready to Drive, [1] = Vehicle is allowed to shift out of park or neutral";
CM_ SG_ 655 EstTimeofChrg_Lv1 "Estimated Time to charge on Level 1";
CM_ SG_ 655 EstTimeofChrg_Lv2 "Estimated Time to charge on Level 2";
CM_ SG_ 655 HVBatCntctrStat "HV Battery pack contactor state";
CM_ SG_ 655 HtrCoreInletTemp "Heater Core Inlet Temp";
CM_ SG_ 655 MIL_OnRq_BPCM "MIL Lamp request from BPCM.";
CM_ SG_ 655 PrplsnSysAtv "Propulsion system active, [1] = active";
CM_ SG_ 291 AHH_Apply_Release_Request "AHH apply/release request";
CM_ SG_ 291 AHH_ModifyAccel_Req "AHH modify accel request; True = [1]";
CM_ SG_ 291 CRC_123h "CRC-checksum byte 1 to 7 according to SAE J1850";
CM_ SG_ 291 MC_123h "Message counter";
CM_ SG_ 291 M_MAX_AXLE "Maximum axle torque";
CM_ SG_ 291 M_MIN_AXLE "Minimum axle torque";
CM_ SG_ 291 M_STA_AXLE "Static axle torque";
CM_ SG_ 784 AvgFuelLvl "Average filtered fuel level in liters";
CM_ SG_ 784 FuelLvlLow "Fuel level low";
CM_ SG_ 784 ODO "Odometer";
CM_ SG_ 784 OilChgRst "Oil change reminder reset request";
CM_ SG_ 784 PTS_MODE_SELECTION "Park assist maneuver selection for PTS";
CM_ SG_ 784 SBR_MuteRq "Seatbelt reminder audio mute request; Mute = [1]";
CM_ SG_ 784 SRS_LMP_STAT "Airbag indicator lamp status";
CM_ SG_ 882 CapacityUnit "Fuel capacity units";
CM_ SG_ 882 ConsumptionUnit "Fuel consumption units";
CM_ SG_ 882 DistanceUnit "Distance (odometer) units; Miles = [1]";
CM_ SG_ 882 Early_Fuel_TeenKey "Teen Key Early fuel warning response, Active = [1]";
CM_ SG_ 882 Fuel_Popup_TeenKey "Teen Key Fuel Popup setting response, Active = [1]";
CM_ SG_ 882 LANG_C "Language preference (5 bit)";
CM_ SG_ 882 PowerUnit "Power units";
CM_ SG_ 882 PressureUnit "Pressure units";
CM_ SG_ 882 RDY_DRV_STAT_CSO "Ready to drive popup status enable/disable; Disabled = [1]";
CM_ SG_ 882 SpeedUnit "Speed (speedometer) units; Miles = [1]";
CM_ SG_ 882 TemperatureUnit "Temperature units; Farenheit = [1]";
CM_ SG_ 882 TorqueUnit "Torque units; Foot Pounds (ft-lb) = [1]";
CM_ SG_ 995 NET_CFG_STAT_INT "Network configuration status";
CM_ SG_ 995 NetCfg_AMP_I "CAN I Amplifier Module (1=present)";
CM_ SG_ 995 NetCfg_ANC_I "Active Noise Cancellation interior (1=present)";
CM_ SG_ 995 NetCfg_BSM "Blind-Spot Module (1=present)";
CM_ SG_ 995 NetCfg_CBC_IN "Common Body Controller Int Bus (1=present)";
CM_ SG_ 995 NetCfg_CLOCK "CAN I Clock Module (1=present)";
CM_ SG_ 995 NetCfg_CRSM "CAN I Comfort Rear Seat Module (1=present)";
CM_ SG_ 995 NetCfg_CSWM "Comfot Seats and Wheel Module (1=present)";
CM_ SG_ 995 NetCfg_CVPM "CAN I Central Vision Processing Module (1=present)";
CM_ SG_ 995 NetCfg_DCM_DR "Door Control Module Driver (1=present)";
CM_ SG_ 995 NetCfg_DCM_PASS "Door Control Module Passenger (1=present)";
CM_ SG_ 995 NetCfg_DCM_RL "Door Control Module Rear Left (1=present)";
CM_ SG_ 995 NetCfg_DCM_RR "Door Control Module Rear Right (1=present)";
CM_ SG_ 995 NetCfg_DCSD "Disassociated Center Stack Display Module (1=present)";
CM_ SG_ 995 NetCfg_DTV "Digital TV Module (1=present)";
CM_ SG_ 995 NetCfg_DVD_CDM "CAN I in-dash disc player module (1=present)";
CM_ SG_ 995 NetCfg_FSM "Folding Seat Module (1=present)";
CM_ SG_ 995 NetCfg_HFM_CTM "Convergence Telematics Module (1=present)";
CM_ SG_ 995 NetCfg_HVAC "Heating Ventilation Air Conditioning (1=present)";
CM_ SG_ 995 NetCfg_HVAC_R "CAN I Rear Heating Ventilation Air Conditioning (1=present)";
CM_ SG_ 995 NetCfg_ICS_I "CAN I Integrated Center Stack Module (1=present)";
CM_ SG_ 995 NetCfg_ICS_R "CAN I Integrated rear Center Stack Module (1=present)";
CM_ SG_ 995 NetCfg_ITM "Intrusion module (1=present)";
CM_ SG_ 995 NetCfg_MSM "Memory Seat Module (1=present)";
CM_ SG_ 995 NetCfg_MSM_PASS "CAN I Memory Seat Module Passenger (1=present)";
CM_ SG_ 995 NetCfg_PLG "Power Liftgate Module (1=present)";
CM_ SG_ 995 NetCfg_PSD_LT "Power Sliding Door Left Module (1=present)";
CM_ SG_ 995 NetCfg_PSD_RT "Power Sliding Door Right Module (1=present)";
CM_ SG_ 995 NetCfg_PTCM "Power Top Control Module (1=present)";
CM_ SG_ 995 NetCfg_RBC "Rear Body Controller Module (1=present)";
CM_ SG_ 995 NetCfg_RBSS "Right Blind-Spot Module (1=present)";
CM_ SG_ 995 NetCfg_TBM "Telematics Box Module (1=present)";
CM_ SG_ 995 NetCfg_TGW "Telematics gateway (1=present)";
CM_ SG_ 995 NetCfg_TMM "CAN I Track Mapping Module (1=present)";
CM_ SG_ 995 NetCfg_TTM "0= Not Present;  1= Present";
CM_ SG_ 995 NetCfg_VES2_I "CAN I Video Ent. System screen 2 Module (1=present)";
CM_ SG_ 995 NetCfg_VES3_I "CAN I Video Ent. System screen 1 Module (1=present)";
CM_ SG_ 995 NetCfg_VRM "Video Routing Module (1=present)";
CM_ SG_ 995 NetCfg_VSIM "Vehicle System Interface Module (1=present)";
CM_ SG_ 995 NetCfg_VTM "Vehicle theft / tax module (1=present)";
BA_DEF_ BO_  "App-Botschaft" ENUM  "nein","ja";
BA_DEF_ BO_  "CanMsgMinLen" INT 0 8;
BA_DEF_ BO_  "DiagRequest" ENUM  "nein","ja";
BA_DEF_ BO_  "DiagResponse" ENUM  "nein","ja";
BA_DEF_ BO_  "DiagState" ENUM  "nein","ja";
BA_DEF_ BO_  "GenMsgCycleTime" INT 0 65535;
BA_DEF_ BO_  "GenMsgCycleTimeActive" INT 0 65535;
BA_DEF_ BO_  "GenMsgDelayTime" INT 0 65535;
BA_DEF_ BO_  "GenMsgNrOfRepetitions" INT 0 65535;
BA_DEF_ BO_  "GenMsgSendType" ENUM  "cyclicX","spontanX","cyclicIfActiveX","spontanWithDelay","cyclicAndSpontanX","cyclicAndSpontanWithDelay","spontanWithRepitition","cyclicIfActiveAndSpontanWD","cyclicIfActiveFast","cyclicWithRepeatOnDemand","none";
BA_DEF_ BO_  "GenMsgStartDelayTime" INT 0 65535;
BA_DEF_ BO_  "GenMsgStartValue" STRING ;
BA_DEF_ BO_  "NWM-Botschaft" ENUM  "nein","ja";
BA_DEF_ BO_  "TpTxIndex" INT 0 99;
BA_DEF_ SG_  "FlexKomComment" STRING ;
BA_DEF_ SG_  "FlexKomIsMotorola" ENUM  "nein","ja";
BA_DEF_ SG_  "FlexKomSID" INT 0 2147483647;
BA_DEF_ SG_  "FlexKomSigLaenge" INT 0 64;
BA_DEF_ SG_  "FlexKomSigName" STRING ;
BA_DEF_ SG_  "FlexKomSigStartPos" INT 0 63;
BA_DEF_ SG_  "FlexKomSigStartValue" STRING ;
BA_DEF_ SG_  "GenSigCycleTime" INT 0 65535;
BA_DEF_ SG_  "GenSigCycleTimeActive" INT 0 65535;
BA_DEF_ SG_  "GenSigSendType" ENUM  "cyclicX","spontanX","cyclicIfActiveX","spontanWithDelay","cyclicAndSpontanX","cyclicAndSpontanWithDelay","spontanWithRepitition","cyclicIfActiveAndSpontanWD","cyclicIfActiveFast","cyclicWithRepeatOnDemand","none";
BA_DEF_ SG_  "GenSigSNA" STRING ;
BA_DEF_ SG_  "GenSigStartValue" HEX 0 2147483648;
BA_DEF_ SG_  "GenSigTimeout_CBC" INT 0 65535;
BA_DEF_ SG_  "GenSigTimeout_EPS" INT 0 65535;
BA_DEF_ SG_  "GenSigTimeout_ESC" INT 0 65535;
BA_DEF_ SG_  "GenSigTimeout_ESL" INT 0 65535;
BA_DEF_ SG_  "GenSigTimeout_RHSC2" INT 0 65535;
BA_DEF_ SG_  "GenSigTimeout_ETM" INT 0 65535;
BA_DEF_ SG_  "GenSigTimeout_HaLF" INT 0 65535;
BA_DEF_ SG_  "GenSigTimeout_IC" INT 0 65535;
BA_DEF_ SG_  "GenSigTimeout_OCM" INT 0 65535;
BA_DEF_ SG_  "GenSigTimeout_ORC" INT 0 65535;
BA_DEF_ SG_  "GenSigTimeout_PTS" INT 0 65535;
BA_DEF_ SG_  "GenSigTimeout_RF_HUB" INT 0 65535;
BA_DEF_ SG_  "GenSigTimeout_SCCM" INT 0 65535;
BA_DEF_ SG_  "RID" STRING ;
BA_DEF_DEF_  "App-Botschaft" "nein";
BA_DEF_DEF_  "CanMsgMinLen" 0;
BA_DEF_DEF_  "DiagRequest" "nein";
BA_DEF_DEF_  "DiagResponse" "nein";
BA_DEF_DEF_  "DiagState" "nein";
BA_DEF_DEF_  "GenMsgCycleTime" 0;
BA_DEF_DEF_  "GenMsgCycleTimeActive" 0;
BA_DEF_DEF_  "GenMsgDelayTime" 0;
BA_DEF_DEF_  "GenMsgNrOfRepetitions" 0;
BA_DEF_DEF_  "GenMsgSendType" "cyclicX";
BA_DEF_DEF_  "GenMsgStartDelayTime" 0;
BA_DEF_DEF_  "GenMsgStartValue" "";
BA_DEF_DEF_  "NWM-Botschaft" "nein";
BA_DEF_DEF_  "TpTxIndex" 0;
BA_DEF_DEF_  "FlexKomComment" "";
BA_DEF_DEF_  "FlexKomIsMotorola" "nein";
BA_DEF_DEF_  "FlexKomSID" 0;
BA_DEF_DEF_  "FlexKomSigLaenge" 0;
BA_DEF_DEF_  "FlexKomSigName" "";
BA_DEF_DEF_  "FlexKomSigStartPos" 0;
BA_DEF_DEF_  "FlexKomSigStartValue" "";
BA_DEF_DEF_  "GenSigCycleTime" 0;
BA_DEF_DEF_  "GenSigCycleTimeActive" 0;
BA_DEF_DEF_  "GenSigSendType" "cyclicX";
BA_DEF_DEF_  "GenSigSNA" "";
BA_DEF_DEF_  "GenSigStartValue" 0;
BA_DEF_DEF_  "GenSigTimeout_CBC" 0;
BA_DEF_DEF_  "GenSigTimeout_EPS" 0;
BA_DEF_DEF_  "GenSigTimeout_ESC" 0;
BA_DEF_DEF_  "GenSigTimeout_ESL" 0;
BA_DEF_DEF_  "GenSigTimeout_RHSC2" 0;
BA_DEF_DEF_  "GenSigTimeout_ETM" 0;
BA_DEF_DEF_  "GenSigTimeout_HaLF" 0;
BA_DEF_DEF_  "GenSigTimeout_IC" 0;
BA_DEF_DEF_  "GenSigTimeout_OCM" 0;
BA_DEF_DEF_  "GenSigTimeout_ORC" 0;
BA_DEF_DEF_  "GenSigTimeout_PTS" 0;
BA_DEF_DEF_  "GenSigTimeout_RF_HUB" 0;
BA_DEF_DEF_  "GenSigTimeout_SCCM" 0;
BA_DEF_DEF_  "RID" "";
BA_ "GenMsgCycleTime" BO_ 300 100;
BA_ "GenMsgDelayTime" BO_ 300 20;
BA_ "GenMsgNrOfRepetitions" BO_ 300 2;
BA_ "GenMsgStartValue" BO_ 300 "0200FFFF00000000h";
BA_ "GenMsgCycleTime" BO_ 522 10;
BA_ "GenMsgDelayTime" BO_ 522 20;
BA_ "GenMsgNrOfRepetitions" BO_ 522 2;
BA_ "GenMsgStartValue" BO_ 522 "7FFF7FFF07FFFFFFh";
BA_ "GenMsgCycleTime" BO_ 320 20;
BA_ "GenMsgDelayTime" BO_ 320 20;
BA_ "GenMsgNrOfRepetitions" BO_ 320 2;
BA_ "GenMsgStartValue" BO_ 320 "0F3400C003FF00FFh";
BA_ "GenMsgCycleTime" BO_ 268 20;
BA_ "GenMsgDelayTime" BO_ 268 20;
BA_ "GenMsgNrOfRepetitions" BO_ 268 2;
BA_ "GenMsgStartValue" BO_ 268 "00000000FF0000FFh";
BA_ "GenMsgCycleTime" BO_ 331 20;
BA_ "GenMsgDelayTime" BO_ 331 20;
BA_ "GenMsgNrOfRepetitions" BO_ 331 2;
BA_ "GenMsgStartValue" BO_ 331 "0000FFFF00FF00FFh";
BA_ "GenMsgCycleTime" BO_ 332 20;
BA_ "GenMsgDelayTime" BO_ 332 20;
BA_ "GenMsgNrOfRepetitions" BO_ 332 2;
BA_ "GenMsgStartValue" BO_ 332 "FFFFFFFFFFFF00FFh";
BA_ "GenMsgCycleTime" BO_ 292 20;
BA_ "GenMsgDelayTime" BO_ 292 20;
BA_ "GenMsgNrOfRepetitions" BO_ 292 2;
BA_ "GenMsgStartValue" BO_ 292 "0000000000FFFFFFh";
BA_ "GenMsgCycleTime" BO_ 344 20;
BA_ "GenMsgDelayTime" BO_ 344 20;
BA_ "GenMsgNrOfRepetitions" BO_ 344 2;
BA_ "GenMsgStartValue" BO_ 344 "FFFFFFFFFFFFFFFFh";
BA_ "GenMsgCycleTime" BO_ 284 20;
BA_ "GenMsgDelayTime" BO_ 284 20;
BA_ "GenMsgNrOfRepetitions" BO_ 284 2;
BA_ "GenMsgStartValue" BO_ 284 "0FFF0FFFFFFF00FFh";
BA_ "GenMsgCycleTime" BO_ 270 20;
BA_ "GenMsgDelayTime" BO_ 270 20;
BA_ "GenMsgNrOfRepetitions" BO_ 270 2;
BA_ "GenMsgStartValue" BO_ 270 "00000000000000FFh";
BA_ "GenMsgCycleTime" BO_ 736 50;
BA_ "GenMsgDelayTime" BO_ 736 20;
BA_ "GenMsgNrOfRepetitions" BO_ 736 2;
BA_ "GenMsgStartValue" BO_ 736 "FFFFFFFF0000003Fh";
BA_ "GenMsgDelayTime" BO_ 840 20;
BA_ "GenMsgNrOfRepetitions" BO_ 840 2;
BA_ "GenMsgSendType" BO_ 840 1;
BA_ "GenMsgStartValue" BO_ 840 "0000000000000000h";
BA_ "GenMsgCycleTime" BO_ 710 2000;
BA_ "GenMsgDelayTime" BO_ 710 20;
BA_ "GenMsgNrOfRepetitions" BO_ 710 2;
BA_ "GenMsgSendType" BO_ 710 5;
BA_ "GenMsgStartValue" BO_ 710 "0300000000000000h";
BA_ "GenMsgCycleTime" BO_ 1013 2000;
BA_ "GenMsgDelayTime" BO_ 1013 20;
BA_ "GenMsgNrOfRepetitions" BO_ 1013 2;
BA_ "GenMsgSendType" BO_ 1013 5;
BA_ "GenMsgStartDelayTime" BO_ 1013 60;
BA_ "GenMsgStartValue" BO_ 1013 "0300000000000000h";
BA_ "GenMsgCycleTime" BO_ 1015 2000;
BA_ "GenMsgDelayTime" BO_ 1015 20;
BA_ "GenMsgNrOfRepetitions" BO_ 1015 2;
BA_ "GenMsgStartDelayTime" BO_ 1015 80;
BA_ "GenMsgStartValue" BO_ 1015 "0300000000000000h";
BA_ "GenMsgCycleTime" BO_ 816 1000;
BA_ "GenMsgDelayTime" BO_ 816 20;
BA_ "GenMsgNrOfRepetitions" BO_ 816 2;
BA_ "GenMsgSendType" BO_ 816 5;
BA_ "GenMsgStartDelayTime" BO_ 816 80;
BA_ "GenMsgStartValue" BO_ 816 "3000071EC0FF8000h";
BA_ "GenMsgCycleTime" BO_ 678 250;
BA_ "GenMsgDelayTime" BO_ 678 20;
BA_ "GenMsgNrOfRepetitions" BO_ 678 2;
BA_ "GenMsgStartValue" BO_ 678 "0000000000000000h";
BA_ "GenMsgCycleTime" BO_ 658 10;
BA_ "GenMsgDelayTime" BO_ 658 20;
BA_ "GenMsgNrOfRepetitions" BO_ 658 2;
BA_ "GenMsgStartValue" BO_ 658 "0000000000FFh";
BA_ "GenMsgCycleTime" BO_ 729 100;
BA_ "GenMsgDelayTime" BO_ 729 20;
BA_ "GenMsgNrOfRepetitions" BO_ 729 2;
BA_ "GenMsgSendType" BO_ 729 5;
BA_ "GenMsgStartValue" BO_ 729 "0000000020h";
BA_ "GenMsgCycleTime" BO_ 701 100;
BA_ "GenMsgDelayTime" BO_ 701 20;
BA_ "GenMsgNrOfRepetitions" BO_ 701 2;
BA_ "GenMsgStartValue" BO_ 701 "7BFF0B0000FF01FFh";
BA_ "GenMsgCycleTime" BO_ 655 1000;
BA_ "GenMsgDelayTime" BO_ 655 20;
BA_ "GenMsgNrOfRepetitions" BO_ 655 2;
BA_ "GenMsgSendType" BO_ 655 5;
BA_ "GenMsgStartValue" BO_ 655 "0000000000000000h";
BA_ "GenMsgCycleTime" BO_ 291 10;
BA_ "GenMsgDelayTime" BO_ 291 20;
BA_ "GenMsgNrOfRepetitions" BO_ 291 2;
BA_ "GenMsgStartValue" BO_ 291 "00000000000000FFh";
BA_ "GenMsgCycleTime" BO_ 784 1000;
BA_ "GenMsgDelayTime" BO_ 784 20;
BA_ "GenMsgNrOfRepetitions" BO_ 784 2;
BA_ "GenMsgSendType" BO_ 784 5;
BA_ "GenMsgStartValue" BO_ 784 "01FF0000FFFFFF07h";
BA_ "GenMsgCycleTime" BO_ 882 1000;
BA_ "GenMsgDelayTime" BO_ 882 20;
BA_ "GenMsgNrOfRepetitions" BO_ 882 2;
BA_ "GenMsgSendType" BO_ 882 5;
BA_ "GenMsgStartValue" BO_ 882 "00F8FCF001FE01FEh";
BA_ "GenMsgCycleTime" BO_ 995 2000;
BA_ "GenMsgDelayTime" BO_ 995 20;
BA_ "GenMsgNrOfRepetitions" BO_ 995 2;
BA_ "GenMsgSendType" BO_ 995 5;
BA_ "GenMsgStartDelayTime" BO_ 995 20;
BA_ "GenMsgStartValue" BO_ 995 "0300000000000000h";
BA_ "FlexKomComment" SG_ 300 EPSInternalVehSpeed "EPS_A1_PKT";
BA_ "FlexKomIsMotorola" SG_ 300 EPSInternalVehSpeed 1;
BA_ "FlexKomSID" SG_ 300 EPSInternalVehSpeed 846;
BA_ "FlexKomSigLaenge" SG_ 300 EPSInternalVehSpeed 64;
BA_ "FlexKomSigName" SG_ 300 EPSInternalVehSpeed "EPS_A1_PKT";
BA_ "FlexKomSigStartPos" SG_ 300 EPSInternalVehSpeed 7;
BA_ "FlexKomSigStartValue" SG_ 300 EPSInternalVehSpeed "0200FFFF00000000h";
BA_ "GenSigCycleTime" SG_ 300 EPSInternalVehSpeed 100;
BA_ "GenSigSNA" SG_ 300 EPSInternalVehSpeed "FFFFh";
BA_ "GenSigStartValue" SG_ 300 EPSInternalVehSpeed 65535;
BA_ "FlexKomComment" SG_ 300 EPS_AsstStat "EPS_A1_PKT";
BA_ "FlexKomIsMotorola" SG_ 300 EPS_AsstStat 1;
BA_ "FlexKomSID" SG_ 300 EPS_AsstStat 846;
BA_ "FlexKomSigLaenge" SG_ 300 EPS_AsstStat 64;
BA_ "FlexKomSigName" SG_ 300 EPS_AsstStat "EPS_A1_PKT";
BA_ "FlexKomSigStartPos" SG_ 300 EPS_AsstStat 7;
BA_ "FlexKomSigStartValue" SG_ 300 EPS_AsstStat "0200FFFF00000000h";
BA_ "GenSigCycleTime" SG_ 300 EPS_AsstStat 100;
BA_ "GenSigSNA" SG_ 300 EPS_AsstStat "7h";
BA_ "GenSigStartValue" SG_ 300 EPS_AsstStat 1;
BA_ "GenSigTimeout_IC" SG_ 300 EPS_AsstStat 1050;
BA_ "GenSigTimeout_ORC" SG_ 300 EPS_AsstStat 350;
BA_ "FlexKomComment" SG_ 300 EPS_Curr "EPS_A1_PKT";
BA_ "FlexKomIsMotorola" SG_ 300 EPS_Curr 1;
BA_ "FlexKomSID" SG_ 300 EPS_Curr 846;
BA_ "FlexKomSigLaenge" SG_ 300 EPS_Curr 64;
BA_ "FlexKomSigName" SG_ 300 EPS_Curr "EPS_A1_PKT";
BA_ "FlexKomSigStartPos" SG_ 300 EPS_Curr 7;
BA_ "FlexKomSigStartValue" SG_ 300 EPS_Curr "0200FFFF00000000h";
BA_ "GenSigCycleTime" SG_ 300 EPS_Curr 100;
BA_ "GenSigSNA" SG_ 300 EPS_Curr "FFh";
BA_ "GenSigStartValue" SG_ 300 EPS_Curr 255;
BA_ "FlexKomComment" SG_ 300 EPS_ErrStat "EPS_A1_PKT";
BA_ "FlexKomIsMotorola" SG_ 300 EPS_ErrStat 1;
BA_ "FlexKomSID" SG_ 300 EPS_ErrStat 846;
BA_ "FlexKomSigLaenge" SG_ 300 EPS_ErrStat 64;
BA_ "FlexKomSigName" SG_ 300 EPS_ErrStat "EPS_A1_PKT";
BA_ "FlexKomSigStartPos" SG_ 300 EPS_ErrStat 7;
BA_ "FlexKomSigStartValue" SG_ 300 EPS_ErrStat "0200FFFF00000000h";
BA_ "GenSigCycleTime" SG_ 300 EPS_ErrStat 100;
BA_ "GenSigSNA" SG_ 300 EPS_ErrStat "7h";
BA_ "FlexKomComment" SG_ 300 EPS_IntraECUCommFault "EPS_A1_PKT";
BA_ "FlexKomIsMotorola" SG_ 300 EPS_IntraECUCommFault 1;
BA_ "FlexKomSID" SG_ 300 EPS_IntraECUCommFault 846;
BA_ "FlexKomSigLaenge" SG_ 300 EPS_IntraECUCommFault 64;
BA_ "FlexKomSigName" SG_ 300 EPS_IntraECUCommFault "EPS_A1_PKT";
BA_ "FlexKomSigStartPos" SG_ 300 EPS_IntraECUCommFault 7;
BA_ "FlexKomSigStartValue" SG_ 300 EPS_IntraECUCommFault "0200FFFF00000000h";
BA_ "GenSigCycleTime" SG_ 300 EPS_IntraECUCommFault 100;
BA_ "GenSigSNA" SG_ 300 EPS_IntraECUCommFault "0h";
BA_ "FlexKomComment" SG_ 300 EPS_MODE_STAT "EPS_A1_PKT";
BA_ "FlexKomIsMotorola" SG_ 300 EPS_MODE_STAT 1;
BA_ "FlexKomSID" SG_ 300 EPS_MODE_STAT 846;
BA_ "FlexKomSigLaenge" SG_ 300 EPS_MODE_STAT 64;
BA_ "FlexKomSigName" SG_ 300 EPS_MODE_STAT "EPS_A1_PKT";
BA_ "FlexKomSigStartPos" SG_ 300 EPS_MODE_STAT 7;
BA_ "FlexKomSigStartValue" SG_ 300 EPS_MODE_STAT "0200FFFF00000000h";
BA_ "GenSigCycleTime" SG_ 300 EPS_MODE_STAT 100;
BA_ "GenSigSNA" SG_ 300 EPS_MODE_STAT "7h";
BA_ "GenSigTimeout_CBC" SG_ 300 EPS_MODE_STAT 1050;
BA_ "RID" SG_ 300 EPS_MODE_STAT "2005";
BA_ "FlexKomComment" SG_ 300 EPS_ModuleVoltage "EPS_A1_PKT";
BA_ "FlexKomIsMotorola" SG_ 300 EPS_ModuleVoltage 1;
BA_ "FlexKomSID" SG_ 300 EPS_ModuleVoltage 846;
BA_ "FlexKomSigLaenge" SG_ 300 EPS_ModuleVoltage 64;
BA_ "FlexKomSigName" SG_ 300 EPS_ModuleVoltage "EPS_A1_PKT";
BA_ "FlexKomSigStartPos" SG_ 300 EPS_ModuleVoltage 7;
BA_ "FlexKomSigStartValue" SG_ 300 EPS_ModuleVoltage "0200FFFF00000000h";
BA_ "GenSigCycleTime" SG_ 300 EPS_ModuleVoltage 100;
BA_ "GenSigSNA" SG_ 300 EPS_ModuleVoltage "FFh";
BA_ "GenSigStartValue" SG_ 300 EPS_ModuleVoltage 255;
BA_ "FlexKomComment" SG_ 300 EPS_Warn_Disp_Rq "EPS_A1_PKT";
BA_ "FlexKomIsMotorola" SG_ 300 EPS_Warn_Disp_Rq 1;
BA_ "FlexKomSID" SG_ 300 EPS_Warn_Disp_Rq 846;
BA_ "FlexKomSigLaenge" SG_ 300 EPS_Warn_Disp_Rq 64;
BA_ "FlexKomSigName" SG_ 300 EPS_Warn_Disp_Rq "EPS_A1_PKT";
BA_ "FlexKomSigStartPos" SG_ 300 EPS_Warn_Disp_Rq 7;
BA_ "FlexKomSigStartValue" SG_ 300 EPS_Warn_Disp_Rq "0200FFFF00000000h";
BA_ "GenSigCycleTime" SG_ 300 EPS_Warn_Disp_Rq 100;
BA_ "GenSigSNA" SG_ 300 EPS_Warn_Disp_Rq "7h";
BA_ "GenSigTimeout_CBC" SG_ 300 EPS_Warn_Disp_Rq 1050;
BA_ "GenSigTimeout_IC" SG_ 300 EPS_Warn_Disp_Rq 1050;
BA_ "GenSigTimeout_ORC" SG_ 300 EPS_Warn_Disp_Rq 350;
BA_ "RID" SG_ 300 EPS_Warn_Disp_Rq "1995";
BA_ "FlexKomComment" SG_ 300 EngineFanRequestActivation "EPS_A1_PKT";
BA_ "FlexKomIsMotorola" SG_ 300 EngineFanRequestActivation 1;
BA_ "FlexKomSID" SG_ 300 EngineFanRequestActivation 846;
BA_ "FlexKomSigLaenge" SG_ 300 EngineFanRequestActivation 64;
BA_ "FlexKomSigName" SG_ 300 EngineFanRequestActivation "EPS_A1_PKT";
BA_ "FlexKomSigStartPos" SG_ 300 EngineFanRequestActivation 7;
BA_ "FlexKomSigStartValue" SG_ 300 EngineFanRequestActivation "0200FFFF00000000h";
BA_ "GenSigCycleTime" SG_ 300 EngineFanRequestActivation 100;
BA_ "GenSigSNA" SG_ 300 EngineFanRequestActivation "0h";
BA_ "FlexKomComment" SG_ 300 PS_SysType "EPS_A1_PKT";
BA_ "FlexKomIsMotorola" SG_ 300 PS_SysType 1;
BA_ "FlexKomSID" SG_ 300 PS_SysType 846;
BA_ "FlexKomSigLaenge" SG_ 300 PS_SysType 64;
BA_ "FlexKomSigName" SG_ 300 PS_SysType "EPS_A1_PKT";
BA_ "FlexKomSigStartPos" SG_ 300 PS_SysType 7;
BA_ "FlexKomSigStartValue" SG_ 300 PS_SysType "0200FFFF00000000h";
BA_ "GenSigCycleTime" SG_ 300 PS_SysType 100;
BA_ "GenSigSNA" SG_ 300 PS_SysType "0h";
BA_ "GenSigTimeout_IC" SG_ 300 PS_SysType 1050;
BA_ "RID" SG_ 300 PS_SysType "1993";
BA_ "FlexKomComment" SG_ 522 CRC_EPS_SDS_Resp "EPS_SDS_Resp_Pkt";
BA_ "FlexKomIsMotorola" SG_ 522 CRC_EPS_SDS_Resp 1;
BA_ "FlexKomSID" SG_ 522 CRC_EPS_SDS_Resp 9202;
BA_ "FlexKomSigLaenge" SG_ 522 CRC_EPS_SDS_Resp 64;
BA_ "FlexKomSigName" SG_ 522 CRC_EPS_SDS_Resp "EPS_SDS_Resp_Pkt";
BA_ "FlexKomSigStartPos" SG_ 522 CRC_EPS_SDS_Resp 7;
BA_ "FlexKomSigStartValue" SG_ 522 CRC_EPS_SDS_Resp "7FFF7FFF07FFFFFFh";
BA_ "GenSigCycleTime" SG_ 522 CRC_EPS_SDS_Resp 10;
BA_ "GenSigSNA" SG_ 522 CRC_EPS_SDS_Resp "FFh";
BA_ "GenSigStartValue" SG_ 522 CRC_EPS_SDS_Resp 255;
BA_ "FlexKomComment" SG_ 522 EPS_MotorTorqueAvailable "EPS_SDS_Resp_Pkt";
BA_ "FlexKomIsMotorola" SG_ 522 EPS_MotorTorqueAvailable 1;
BA_ "FlexKomSID" SG_ 522 EPS_MotorTorqueAvailable 9202;
BA_ "FlexKomSigLaenge" SG_ 522 EPS_MotorTorqueAvailable 64;
BA_ "FlexKomSigName" SG_ 522 EPS_MotorTorqueAvailable "EPS_SDS_Resp_Pkt";
BA_ "FlexKomSigStartPos" SG_ 522 EPS_MotorTorqueAvailable 7;
BA_ "FlexKomSigStartValue" SG_ 522 EPS_MotorTorqueAvailable "7FFF7FFF07FFFFFFh";
BA_ "GenSigCycleTime" SG_ 522 EPS_MotorTorqueAvailable 10;
BA_ "GenSigSNA" SG_ 522 EPS_MotorTorqueAvailable "FFh";
BA_ "GenSigStartValue" SG_ 522 EPS_MotorTorqueAvailable 255;
BA_ "FlexKomComment" SG_ 522 EPS_SDSTorqueApplied "EPS_SDS_Resp_Pkt";
BA_ "FlexKomIsMotorola" SG_ 522 EPS_SDSTorqueApplied 1;
BA_ "FlexKomSID" SG_ 522 EPS_SDSTorqueApplied 9202;
BA_ "FlexKomSigLaenge" SG_ 522 EPS_SDSTorqueApplied 64;
BA_ "FlexKomSigName" SG_ 522 EPS_SDSTorqueApplied "EPS_SDS_Resp_Pkt";
BA_ "FlexKomSigStartPos" SG_ 522 EPS_SDSTorqueApplied 7;
BA_ "FlexKomSigStartValue" SG_ 522 EPS_SDSTorqueApplied "7FFF7FFF07FFFFFFh";
BA_ "GenSigCycleTime" SG_ 522 EPS_SDSTorqueApplied 10;
BA_ "GenSigSNA" SG_ 522 EPS_SDSTorqueApplied "7FFh";
BA_ "GenSigStartValue" SG_ 522 EPS_SDSTorqueApplied 2047;
BA_ "FlexKomComment" SG_ 522 EPS_SDSTorqueOverlayFault "EPS_SDS_Resp_Pkt";
BA_ "FlexKomIsMotorola" SG_ 522 EPS_SDSTorqueOverlayFault 1;
BA_ "FlexKomSID" SG_ 522 EPS_SDSTorqueOverlayFault 9202;
BA_ "FlexKomSigLaenge" SG_ 522 EPS_SDSTorqueOverlayFault 64;
BA_ "FlexKomSigName" SG_ 522 EPS_SDSTorqueOverlayFault "EPS_SDS_Resp_Pkt";
BA_ "FlexKomSigStartPos" SG_ 522 EPS_SDSTorqueOverlayFault 7;
BA_ "FlexKomSigStartValue" SG_ 522 EPS_SDSTorqueOverlayFault "7FFF7FFF07FFFFFFh";
BA_ "GenSigCycleTime" SG_ 522 EPS_SDSTorqueOverlayFault 10;
BA_ "GenSigSNA" SG_ 522 EPS_SDSTorqueOverlayFault "0h";
BA_ "FlexKomComment" SG_ 522 EPS_SDSTorqueOverlayIntActivated "EPS_SDS_Resp_Pkt";
BA_ "FlexKomIsMotorola" SG_ 522 EPS_SDSTorqueOverlayIntActivated 1;
BA_ "FlexKomSID" SG_ 522 EPS_SDSTorqueOverlayIntActivated 9202;
BA_ "FlexKomSigLaenge" SG_ 522 EPS_SDSTorqueOverlayIntActivated 64;
BA_ "FlexKomSigName" SG_ 522 EPS_SDSTorqueOverlayIntActivated "EPS_SDS_Resp_Pkt";
BA_ "FlexKomSigStartPos" SG_ 522 EPS_SDSTorqueOverlayIntActivated 7;
BA_ "FlexKomSigStartValue" SG_ 522 EPS_SDSTorqueOverlayIntActivated "7FFF7FFF07FFFFFFh";
BA_ "GenSigCycleTime" SG_ 522 EPS_SDSTorqueOverlayIntActivated 10;
BA_ "GenSigSNA" SG_ 522 EPS_SDSTorqueOverlayIntActivated "0h";
BA_ "FlexKomComment" SG_ 522 EPS_SteerAngle "EPS_SDS_Resp_Pkt";
BA_ "FlexKomIsMotorola" SG_ 522 EPS_SteerAngle 1;
BA_ "FlexKomSID" SG_ 522 EPS_SteerAngle 9202;
BA_ "FlexKomSigLaenge" SG_ 522 EPS_SteerAngle 64;
BA_ "FlexKomSigName" SG_ 522 EPS_SteerAngle "EPS_SDS_Resp_Pkt";
BA_ "FlexKomSigStartPos" SG_ 522 EPS_SteerAngle 7;
BA_ "FlexKomSigStartValue" SG_ 522 EPS_SteerAngle "7FFF7FFF07FFFFFFh";
BA_ "GenSigCycleTime" SG_ 522 EPS_SteerAngle 10;
BA_ "GenSigSNA" SG_ 522 EPS_SteerAngle "7FFFh";
BA_ "GenSigStartValue" SG_ 522 EPS_SteerAngle 32767;
BA_ "FlexKomComment" SG_ 522 EPS_SteerVelocity "EPS_SDS_Resp_Pkt";
BA_ "FlexKomIsMotorola" SG_ 522 EPS_SteerVelocity 1;
BA_ "FlexKomSID" SG_ 522 EPS_SteerVelocity 9202;
BA_ "FlexKomSigLaenge" SG_ 522 EPS_SteerVelocity 64;
BA_ "FlexKomSigName" SG_ 522 EPS_SteerVelocity "EPS_SDS_Resp_Pkt";
BA_ "FlexKomSigStartPos" SG_ 522 EPS_SteerVelocity 7;
BA_ "FlexKomSigStartValue" SG_ 522 EPS_SteerVelocity "7FFF7FFF07FFFFFFh";
BA_ "GenSigCycleTime" SG_ 522 EPS_SteerVelocity 10;
BA_ "GenSigSNA" SG_ 522 EPS_SteerVelocity "7FFFh";
BA_ "GenSigStartValue" SG_ 522 EPS_SteerVelocity 32767;
BA_ "FlexKomComment" SG_ 522 EPS_TemporaryDeactivationSDS "EPS_SDS_Resp_Pkt";
BA_ "FlexKomIsMotorola" SG_ 522 EPS_TemporaryDeactivationSDS 1;
BA_ "FlexKomSID" SG_ 522 EPS_TemporaryDeactivationSDS 9202;
BA_ "FlexKomSigLaenge" SG_ 522 EPS_TemporaryDeactivationSDS 64;
BA_ "FlexKomSigName" SG_ 522 EPS_TemporaryDeactivationSDS "EPS_SDS_Resp_Pkt";
BA_ "FlexKomSigStartPos" SG_ 522 EPS_TemporaryDeactivationSDS 7;
BA_ "FlexKomSigStartValue" SG_ 522 EPS_TemporaryDeactivationSDS "7FFF7FFF07FFFFFFh";
BA_ "GenSigCycleTime" SG_ 522 EPS_TemporaryDeactivationSDS 10;
BA_ "GenSigSNA" SG_ 522 EPS_TemporaryDeactivationSDS "0h";
BA_ "FlexKomComment" SG_ 522 MC_EPS_SDS_Resp "EPS_SDS_Resp_Pkt";
BA_ "FlexKomIsMotorola" SG_ 522 MC_EPS_SDS_Resp 1;
BA_ "FlexKomSID" SG_ 522 MC_EPS_SDS_Resp 9202;
BA_ "FlexKomSigLaenge" SG_ 522 MC_EPS_SDS_Resp 64;
BA_ "FlexKomSigName" SG_ 522 MC_EPS_SDS_Resp "EPS_SDS_Resp_Pkt";
BA_ "FlexKomSigStartPos" SG_ 522 MC_EPS_SDS_Resp 7;
BA_ "FlexKomSigStartValue" SG_ 522 MC_EPS_SDS_Resp "7FFF7FFF07FFFFFFh";
BA_ "GenSigCycleTime" SG_ 522 MC_EPS_SDS_Resp 10;
BA_ "GenSigSNA" SG_ 522 MC_EPS_SDS_Resp "0h";
BA_ "FlexKomComment" SG_ 320 ABS_BrkEvt "ESP Brake Status Information";
BA_ "FlexKomIsMotorola" SG_ 320 ABS_BrkEvt 1;
BA_ "FlexKomSigLaenge" SG_ 320 ABS_BrkEvt 64;
BA_ "FlexKomSigName" SG_ 320 ABS_BrkEvt "ESP_BRK_STAT";
BA_ "FlexKomSigStartPos" SG_ 320 ABS_BrkEvt 7;
BA_ "FlexKomSigStartValue" SG_ 320 ABS_BrkEvt "0F3400C003FF00FFh";
BA_ "GenSigCycleTime" SG_ 320 ABS_BrkEvt 20;
BA_ "GenSigSNA" SG_ 320 ABS_BrkEvt "0h";
BA_ "GenSigTimeout_ETM" SG_ 320 ABS_BrkEvt 210;
BA_ "GenSigTimeout_ORC" SG_ 320 ABS_BrkEvt 70;
BA_ "RID" SG_ 320 ABS_BrkEvt "5034";
BA_ "FlexKomComment" SG_ 320 BrkIntrvntn_Actv_AS "ESP Brake Status Information";
BA_ "FlexKomIsMotorola" SG_ 320 BrkIntrvntn_Actv_AS 1;
BA_ "FlexKomSigLaenge" SG_ 320 BrkIntrvntn_Actv_AS 64;
BA_ "FlexKomSigName" SG_ 320 BrkIntrvntn_Actv_AS "ESP_BRK_STAT";
BA_ "FlexKomSigStartPos" SG_ 320 BrkIntrvntn_Actv_AS 7;
BA_ "FlexKomSigStartValue" SG_ 320 BrkIntrvntn_Actv_AS "0F3400C003FF00FFh";
BA_ "GenSigCycleTime" SG_ 320 BrkIntrvntn_Actv_AS 20;
BA_ "GenSigSNA" SG_ 320 BrkIntrvntn_Actv_AS "0h";
BA_ "GenSigTimeout_ORC" SG_ 320 BrkIntrvntn_Actv_AS 70;
BA_ "FlexKomComment" SG_ 320 BrkIntrvntn_Actv_ESP "ESP Brake Status Information";
BA_ "FlexKomIsMotorola" SG_ 320 BrkIntrvntn_Actv_ESP 1;
BA_ "FlexKomSigLaenge" SG_ 320 BrkIntrvntn_Actv_ESP 64;
BA_ "FlexKomSigName" SG_ 320 BrkIntrvntn_Actv_ESP "ESP_BRK_STAT";
BA_ "FlexKomSigStartPos" SG_ 320 BrkIntrvntn_Actv_ESP 7;
BA_ "FlexKomSigStartValue" SG_ 320 BrkIntrvntn_Actv_ESP "0F3400C003FF00FFh";
BA_ "GenSigCycleTime" SG_ 320 BrkIntrvntn_Actv_ESP 20;
BA_ "GenSigSNA" SG_ 320 BrkIntrvntn_Actv_ESP "0h";
BA_ "GenSigTimeout_RHSC2" SG_ 320 BrkIntrvntn_Actv_ESP 210;
BA_ "GenSigTimeout_ORC" SG_ 320 BrkIntrvntn_Actv_ESP 70;
BA_ "FlexKomComment" SG_ 320 BrkIntrvntn_Enbl "ESP Brake Status Information";
BA_ "FlexKomIsMotorola" SG_ 320 BrkIntrvntn_Enbl 1;
BA_ "FlexKomSigLaenge" SG_ 320 BrkIntrvntn_Enbl 64;
BA_ "FlexKomSigName" SG_ 320 BrkIntrvntn_Enbl "ESP_BRK_STAT";
BA_ "FlexKomSigStartPos" SG_ 320 BrkIntrvntn_Enbl 7;
BA_ "FlexKomSigStartValue" SG_ 320 BrkIntrvntn_Enbl "0F3400C003FF00FFh";
BA_ "GenSigCycleTime" SG_ 320 BrkIntrvntn_Enbl 20;
BA_ "GenSigSNA" SG_ 320 BrkIntrvntn_Enbl "0h";
BA_ "GenSigTimeout_ORC" SG_ 320 BrkIntrvntn_Enbl 70;
BA_ "FlexKomComment" SG_ 320 BrkPdl_Flt "ESP Brake Status Information";
BA_ "FlexKomIsMotorola" SG_ 320 BrkPdl_Flt 1;
BA_ "FlexKomSigLaenge" SG_ 320 BrkPdl_Flt 64;
BA_ "FlexKomSigName" SG_ 320 BrkPdl_Flt "ESP_BRK_STAT";
BA_ "FlexKomSigStartPos" SG_ 320 BrkPdl_Flt 7;
BA_ "FlexKomSigStartValue" SG_ 320 BrkPdl_Flt "0F3400C003FF00FFh";
BA_ "GenSigCycleTime" SG_ 320 BrkPdl_Flt 20;
BA_ "GenSigSNA" SG_ 320 BrkPdl_Flt "0h";
BA_ "RID" SG_ 320 BrkPdl_Flt "5033";
BA_ "FlexKomComment" SG_ 320 BrkPdl_Stat "ESP Brake Status Information";
BA_ "FlexKomIsMotorola" SG_ 320 BrkPdl_Stat 1;
BA_ "FlexKomSigLaenge" SG_ 320 BrkPdl_Stat 64;
BA_ "FlexKomSigName" SG_ 320 BrkPdl_Stat "ESP_BRK_STAT";
BA_ "FlexKomSigStartPos" SG_ 320 BrkPdl_Stat 7;
BA_ "FlexKomSigStartValue" SG_ 320 BrkPdl_Stat "0F3400C003FF00FFh";
BA_ "GenSigCycleTime" SG_ 320 BrkPdl_Stat 20;
BA_ "GenSigSNA" SG_ 320 BrkPdl_Stat "3h";
BA_ "GenSigStartValue" SG_ 320 BrkPdl_Stat 3;
BA_ "GenSigTimeout_CBC" SG_ 320 BrkPdl_Stat 510;
BA_ "GenSigTimeout_RHSC2" SG_ 320 BrkPdl_Stat 210;
BA_ "GenSigTimeout_ETM" SG_ 320 BrkPdl_Stat 210;
BA_ "GenSigTimeout_IC" SG_ 320 BrkPdl_Stat 210;
BA_ "GenSigTimeout_ORC" SG_ 320 BrkPdl_Stat 70;
BA_ "RID" SG_ 320 BrkPdl_Stat "1135";
BA_ "FlexKomComment" SG_ 320 Brk_Stat "ESP Brake Status Information";
BA_ "FlexKomIsMotorola" SG_ 320 Brk_Stat 1;
BA_ "FlexKomSigLaenge" SG_ 320 Brk_Stat 64;
BA_ "FlexKomSigName" SG_ 320 Brk_Stat "ESP_BRK_STAT";
BA_ "FlexKomSigStartPos" SG_ 320 Brk_Stat 7;
BA_ "FlexKomSigStartValue" SG_ 320 Brk_Stat "0F3400C003FF00FFh";
BA_ "GenSigCycleTime" SG_ 320 Brk_Stat 20;
BA_ "GenSigSNA" SG_ 320 Brk_Stat "3h";
BA_ "GenSigStartValue" SG_ 320 Brk_Stat 3;
BA_ "GenSigTimeout_CBC" SG_ 320 Brk_Stat 210;
BA_ "GenSigTimeout_ORC" SG_ 320 Brk_Stat 70;
BA_ "RID" SG_ 320 Brk_Stat "1226";
BA_ "FlexKomComment" SG_ 320 Brk_Thermdl "ESP Brake Status Information";
BA_ "FlexKomIsMotorola" SG_ 320 Brk_Thermdl 1;
BA_ "FlexKomSigLaenge" SG_ 320 Brk_Thermdl 64;
BA_ "FlexKomSigName" SG_ 320 Brk_Thermdl "ESP_BRK_STAT";
BA_ "FlexKomSigStartPos" SG_ 320 Brk_Thermdl 7;
BA_ "FlexKomSigStartValue" SG_ 320 Brk_Thermdl "0F3400C003FF00FFh";
BA_ "GenSigCycleTime" SG_ 320 Brk_Thermdl 20;
BA_ "GenSigSNA" SG_ 320 Brk_Thermdl "0h";
BA_ "FlexKomComment" SG_ 320 CRC_Brk_Stat "ESP Brake Status Information";
BA_ "FlexKomIsMotorola" SG_ 320 CRC_Brk_Stat 1;
BA_ "FlexKomSigLaenge" SG_ 320 CRC_Brk_Stat 64;
BA_ "FlexKomSigName" SG_ 320 CRC_Brk_Stat "ESP_BRK_STAT";
BA_ "FlexKomSigStartPos" SG_ 320 CRC_Brk_Stat 7;
BA_ "FlexKomSigStartValue" SG_ 320 CRC_Brk_Stat "0F3400C003FF00FFh";
BA_ "GenSigCycleTime" SG_ 320 CRC_Brk_Stat 20;
BA_ "GenSigSNA" SG_ 320 CRC_Brk_Stat "FFh";
BA_ "GenSigStartValue" SG_ 320 CRC_Brk_Stat 255;
BA_ "GenSigTimeout_IC" SG_ 320 CRC_Brk_Stat 210;
BA_ "GenSigTimeout_ORC" SG_ 320 CRC_Brk_Stat 70;
BA_ "FlexKomComment" SG_ 320 DTR_CC_Enabled "ESP Brake Status Information";
BA_ "FlexKomIsMotorola" SG_ 320 DTR_CC_Enabled 1;
BA_ "FlexKomSigLaenge" SG_ 320 DTR_CC_Enabled 64;
BA_ "FlexKomSigName" SG_ 320 DTR_CC_Enabled "ESP_BRK_STAT";
BA_ "FlexKomSigStartPos" SG_ 320 DTR_CC_Enabled 7;
BA_ "FlexKomSigStartValue" SG_ 320 DTR_CC_Enabled "0F3400C003FF00FFh";
BA_ "GenSigCycleTime" SG_ 320 DTR_CC_Enabled 20;
BA_ "GenSigSNA" SG_ 320 DTR_CC_Enabled "0h";
BA_ "FlexKomComment" SG_ 320 DTR_CC_Engaged "ESP Brake Status Information";
BA_ "FlexKomIsMotorola" SG_ 320 DTR_CC_Engaged 1;
BA_ "FlexKomSigLaenge" SG_ 320 DTR_CC_Engaged 64;
BA_ "FlexKomSigName" SG_ 320 DTR_CC_Engaged "ESP_BRK_STAT";
BA_ "FlexKomSigStartPos" SG_ 320 DTR_CC_Engaged 7;
BA_ "FlexKomSigStartValue" SG_ 320 DTR_CC_Engaged "0F3400C003FF00FFh";
BA_ "GenSigCycleTime" SG_ 320 DTR_CC_Engaged 20;
BA_ "GenSigSNA" SG_ 320 DTR_CC_Engaged "0h";
BA_ "GenSigTimeout_ORC" SG_ 320 DTR_CC_Engaged 70;
BA_ "FlexKomComment" SG_ 320 ESP_Sys_Stat "ESP Brake Status Information";
BA_ "FlexKomIsMotorola" SG_ 320 ESP_Sys_Stat 1;
BA_ "FlexKomSigLaenge" SG_ 320 ESP_Sys_Stat 64;
BA_ "FlexKomSigName" SG_ 320 ESP_Sys_Stat "ESP_BRK_STAT";
BA_ "FlexKomSigStartPos" SG_ 320 ESP_Sys_Stat 7;
BA_ "FlexKomSigStartValue" SG_ 320 ESP_Sys_Stat "0F3400C003FF00FFh";
BA_ "GenSigCycleTime" SG_ 320 ESP_Sys_Stat 20;
BA_ "GenSigSNA" SG_ 320 ESP_Sys_Stat "1h";
BA_ "GenSigStartValue" SG_ 320 ESP_Sys_Stat 1;
BA_ "GenSigTimeout_IC" SG_ 320 ESP_Sys_Stat 210;
BA_ "GenSigTimeout_ORC" SG_ 320 ESP_Sys_Stat 70;
BA_ "FlexKomComment" SG_ 320 EmgBrk_Actv "ESP Brake Status Information";
BA_ "FlexKomIsMotorola" SG_ 320 EmgBrk_Actv 1;
BA_ "FlexKomSigLaenge" SG_ 320 EmgBrk_Actv 64;
BA_ "FlexKomSigName" SG_ 320 EmgBrk_Actv "ESP_BRK_STAT";
BA_ "FlexKomSigStartPos" SG_ 320 EmgBrk_Actv 7;
BA_ "FlexKomSigStartValue" SG_ 320 EmgBrk_Actv "0F3400C003FF00FFh";
BA_ "GenSigCycleTime" SG_ 320 EmgBrk_Actv 20;
BA_ "GenSigSNA" SG_ 320 EmgBrk_Actv "0h";
BA_ "GenSigTimeout_ORC" SG_ 320 EmgBrk_Actv 70;
BA_ "FlexKomComment" SG_ 320 FullBrk_Actv "ESP Brake Status Information";
BA_ "FlexKomIsMotorola" SG_ 320 FullBrk_Actv 1;
BA_ "FlexKomSigLaenge" SG_ 320 FullBrk_Actv 64;
BA_ "FlexKomSigName" SG_ 320 FullBrk_Actv "ESP_BRK_STAT";
BA_ "FlexKomSigStartPos" SG_ 320 FullBrk_Actv 7;
BA_ "FlexKomSigStartValue" SG_ 320 FullBrk_Actv "0F3400C003FF00FFh";
BA_ "GenSigCycleTime" SG_ 320 FullBrk_Actv 20;
BA_ "GenSigSNA" SG_ 320 FullBrk_Actv "0h";
BA_ "GenSigTimeout_CBC" SG_ 320 FullBrk_Actv 210;
BA_ "GenSigTimeout_IC" SG_ 320 FullBrk_Actv 210;
BA_ "GenSigTimeout_ORC" SG_ 320 FullBrk_Actv 70;
BA_ "FlexKomComment" SG_ 320 MC_Brk_Stat "ESP Brake Status Information";
BA_ "FlexKomIsMotorola" SG_ 320 MC_Brk_Stat 1;
BA_ "FlexKomSigLaenge" SG_ 320 MC_Brk_Stat 64;
BA_ "FlexKomSigName" SG_ 320 MC_Brk_Stat "ESP_BRK_STAT";
BA_ "FlexKomSigStartPos" SG_ 320 MC_Brk_Stat 7;
BA_ "FlexKomSigStartValue" SG_ 320 MC_Brk_Stat "0F3400C003FF00FFh";
BA_ "GenSigCycleTime" SG_ 320 MC_Brk_Stat 20;
BA_ "GenSigSNA" SG_ 320 MC_Brk_Stat "0h";
BA_ "GenSigTimeout_IC" SG_ 320 MC_Brk_Stat 210;
BA_ "GenSigTimeout_ORC" SG_ 320 MC_Brk_Stat 70;
BA_ "FlexKomComment" SG_ 320 REF_VEH_SPEED "ESP Brake Status Information";
BA_ "FlexKomIsMotorola" SG_ 320 REF_VEH_SPEED 1;
BA_ "FlexKomSigLaenge" SG_ 320 REF_VEH_SPEED 64;
BA_ "FlexKomSigName" SG_ 320 REF_VEH_SPEED "ESP_BRK_STAT";
BA_ "FlexKomSigStartPos" SG_ 320 REF_VEH_SPEED 7;
BA_ "FlexKomSigStartValue" SG_ 320 REF_VEH_SPEED "0F3400C003FF00FFh";
BA_ "GenSigCycleTime" SG_ 320 REF_VEH_SPEED 20;
BA_ "GenSigSNA" SG_ 320 REF_VEH_SPEED "3FFh";
BA_ "GenSigStartValue" SG_ 320 REF_VEH_SPEED 1023;
BA_ "GenSigTimeout_IC" SG_ 320 REF_VEH_SPEED 210;
BA_ "GenSigTimeout_ORC" SG_ 320 REF_VEH_SPEED 70;
BA_ "FlexKomComment" SG_ 320 RollTestMd_Actv "ESP Brake Status Information";
BA_ "FlexKomIsMotorola" SG_ 320 RollTestMd_Actv 1;
BA_ "FlexKomSigLaenge" SG_ 320 RollTestMd_Actv 64;
BA_ "FlexKomSigName" SG_ 320 RollTestMd_Actv "ESP_BRK_STAT";
BA_ "FlexKomSigStartPos" SG_ 320 RollTestMd_Actv 7;
BA_ "FlexKomSigStartValue" SG_ 320 RollTestMd_Actv "0F3400C003FF00FFh";
BA_ "GenSigCycleTime" SG_ 320 RollTestMd_Actv 20;
BA_ "GenSigSNA" SG_ 320 RollTestMd_Actv "3h";
BA_ "GenSigStartValue" SG_ 320 RollTestMd_Actv 3;
BA_ "FlexKomComment" SG_ 320 SPCR_AS_Off_Rq "ESP Brake Status Information";
BA_ "FlexKomIsMotorola" SG_ 320 SPCR_AS_Off_Rq 1;
BA_ "FlexKomSigLaenge" SG_ 320 SPCR_AS_Off_Rq 64;
BA_ "FlexKomSigName" SG_ 320 SPCR_AS_Off_Rq "ESP_BRK_STAT";
BA_ "FlexKomSigStartPos" SG_ 320 SPCR_AS_Off_Rq 7;
BA_ "FlexKomSigStartValue" SG_ 320 SPCR_AS_Off_Rq "0F3400C003FF00FFh";
BA_ "GenSigCycleTime" SG_ 320 SPCR_AS_Off_Rq 20;
BA_ "GenSigSNA" SG_ 320 SPCR_AS_Off_Rq "0h";
BA_ "FlexKomComment" SG_ 268 ASRActive "Engine torque request from ESC";
BA_ "FlexKomIsMotorola" SG_ 268 ASRActive 1;
BA_ "FlexKomSID" SG_ 268 ASRActive 1;
BA_ "FlexKomSigLaenge" SG_ 268 ASRActive 64;
BA_ "FlexKomSigName" SG_ 268 ASRActive "Eng_Trq_Rq";
BA_ "FlexKomSigStartPos" SG_ 268 ASRActive 7;
BA_ "FlexKomSigStartValue" SG_ 268 ASRActive "00000000FF0000FFh";
BA_ "GenSigCycleTime" SG_ 268 ASRActive 20;
BA_ "GenSigSNA" SG_ 268 ASRActive "0h";
BA_ "RID" SG_ 268 ASRActive "5029";
BA_ "FlexKomComment" SG_ 268 Brk_Jrk_Rsp "Engine torque request from ESC";
BA_ "FlexKomIsMotorola" SG_ 268 Brk_Jrk_Rsp 1;
BA_ "FlexKomSID" SG_ 268 Brk_Jrk_Rsp 1;
BA_ "FlexKomSigLaenge" SG_ 268 Brk_Jrk_Rsp 64;
BA_ "FlexKomSigName" SG_ 268 Brk_Jrk_Rsp "Eng_Trq_Rq";
BA_ "FlexKomSigStartPos" SG_ 268 Brk_Jrk_Rsp 7;
BA_ "FlexKomSigStartValue" SG_ 268 Brk_Jrk_Rsp "00000000FF0000FFh";
BA_ "GenSigCycleTime" SG_ 268 Brk_Jrk_Rsp 20;
BA_ "GenSigSNA" SG_ 268 Brk_Jrk_Rsp "0h";
BA_ "GenSigTimeout_ORC" SG_ 268 Brk_Jrk_Rsp 70;
BA_ "FlexKomComment" SG_ 268 CRC_ENG_RQ_ESC "Engine torque request from ESC";
BA_ "FlexKomIsMotorola" SG_ 268 CRC_ENG_RQ_ESC 1;
BA_ "FlexKomSID" SG_ 268 CRC_ENG_RQ_ESC 1;
BA_ "FlexKomSigLaenge" SG_ 268 CRC_ENG_RQ_ESC 64;
BA_ "FlexKomSigName" SG_ 268 CRC_ENG_RQ_ESC "Eng_Trq_Rq";
BA_ "FlexKomSigStartPos" SG_ 268 CRC_ENG_RQ_ESC 7;
BA_ "FlexKomSigStartValue" SG_ 268 CRC_ENG_RQ_ESC "00000000FF0000FFh";
BA_ "GenSigCycleTime" SG_ 268 CRC_ENG_RQ_ESC 20;
BA_ "GenSigSNA" SG_ 268 CRC_ENG_RQ_ESC "FFh";
BA_ "GenSigStartValue" SG_ 268 CRC_ENG_RQ_ESC 255;
BA_ "FlexKomComment" SG_ 268 DAS_Enbl_Rq "Engine torque request from ESC";
BA_ "FlexKomIsMotorola" SG_ 268 DAS_Enbl_Rq 1;
BA_ "FlexKomSID" SG_ 268 DAS_Enbl_Rq 1;
BA_ "FlexKomSigLaenge" SG_ 268 DAS_Enbl_Rq 64;
BA_ "FlexKomSigName" SG_ 268 DAS_Enbl_Rq "Eng_Trq_Rq";
BA_ "FlexKomSigStartPos" SG_ 268 DAS_Enbl_Rq 7;
BA_ "FlexKomSigStartValue" SG_ 268 DAS_Enbl_Rq "00000000FF0000FFh";
BA_ "GenSigCycleTime" SG_ 268 DAS_Enbl_Rq 20;
BA_ "GenSigSNA" SG_ 268 DAS_Enbl_Rq "0h";
BA_ "GenSigTimeout_ORC" SG_ 268 DAS_Enbl_Rq 70;
BA_ "FlexKomComment" SG_ 268 DAS_RqActv "Engine torque request from ESC";
BA_ "FlexKomIsMotorola" SG_ 268 DAS_RqActv 1;
BA_ "FlexKomSID" SG_ 268 DAS_RqActv 1;
BA_ "FlexKomSigLaenge" SG_ 268 DAS_RqActv 64;
BA_ "FlexKomSigName" SG_ 268 DAS_RqActv "Eng_Trq_Rq";
BA_ "FlexKomSigStartPos" SG_ 268 DAS_RqActv 7;
BA_ "FlexKomSigStartValue" SG_ 268 DAS_RqActv "00000000FF0000FFh";
BA_ "GenSigCycleTime" SG_ 268 DAS_RqActv 20;
BA_ "GenSigSNA" SG_ 268 DAS_RqActv "7h";
BA_ "GenSigTimeout_ORC" SG_ 268 DAS_RqActv 70;
BA_ "FlexKomComment" SG_ 268 EngTrqMax_Rq_ESC "Engine torque request from ESC";
BA_ "FlexKomIsMotorola" SG_ 268 EngTrqMax_Rq_ESC 1;
BA_ "FlexKomSID" SG_ 268 EngTrqMax_Rq_ESC 1;
BA_ "FlexKomSigLaenge" SG_ 268 EngTrqMax_Rq_ESC 64;
BA_ "FlexKomSigName" SG_ 268 EngTrqMax_Rq_ESC "Eng_Trq_Rq";
BA_ "FlexKomSigStartPos" SG_ 268 EngTrqMax_Rq_ESC 7;
BA_ "FlexKomSigStartValue" SG_ 268 EngTrqMax_Rq_ESC "00000000FF0000FFh";
BA_ "GenSigCycleTime" SG_ 268 EngTrqMax_Rq_ESC 20;
BA_ "GenSigSNA" SG_ 268 EngTrqMax_Rq_ESC "0h";
BA_ "FlexKomComment" SG_ 268 EngTrqMin_Rq_ESC "Engine torque request from ESC";
BA_ "FlexKomIsMotorola" SG_ 268 EngTrqMin_Rq_ESC 1;
BA_ "FlexKomSID" SG_ 268 EngTrqMin_Rq_ESC 1;
BA_ "FlexKomSigLaenge" SG_ 268 EngTrqMin_Rq_ESC 64;
BA_ "FlexKomSigName" SG_ 268 EngTrqMin_Rq_ESC "Eng_Trq_Rq";
BA_ "FlexKomSigStartPos" SG_ 268 EngTrqMin_Rq_ESC 7;
BA_ "FlexKomSigStartValue" SG_ 268 EngTrqMin_Rq_ESC "00000000FF0000FFh";
BA_ "GenSigCycleTime" SG_ 268 EngTrqMin_Rq_ESC 20;
BA_ "GenSigSNA" SG_ 268 EngTrqMin_Rq_ESC "0h";
BA_ "FlexKomComment" SG_ 268 EngTrq_Rq_ESC "Engine torque request from ESC";
BA_ "FlexKomIsMotorola" SG_ 268 EngTrq_Rq_ESC 1;
BA_ "FlexKomSID" SG_ 268 EngTrq_Rq_ESC 1;
BA_ "FlexKomSigLaenge" SG_ 268 EngTrq_Rq_ESC 64;
BA_ "FlexKomSigName" SG_ 268 EngTrq_Rq_ESC "Eng_Trq_Rq";
BA_ "FlexKomSigStartPos" SG_ 268 EngTrq_Rq_ESC 7;
BA_ "FlexKomSigStartValue" SG_ 268 EngTrq_Rq_ESC "00000000FF0000FFh";
BA_ "GenSigCycleTime" SG_ 268 EngTrq_Rq_ESC 20;
BA_ "GenSigSNA" SG_ 268 EngTrq_Rq_ESC "1FFFh";
BA_ "GenSigTimeout_ETM" SG_ 268 EngTrq_Rq_ESC 210;
BA_ "FlexKomComment" SG_ 268 MC_ENG_RQ_ESC "Engine torque request from ESC";
BA_ "FlexKomIsMotorola" SG_ 268 MC_ENG_RQ_ESC 1;
BA_ "FlexKomSID" SG_ 268 MC_ENG_RQ_ESC 1;
BA_ "FlexKomSigLaenge" SG_ 268 MC_ENG_RQ_ESC 64;
BA_ "FlexKomSigName" SG_ 268 MC_ENG_RQ_ESC "Eng_Trq_Rq";
BA_ "FlexKomSigStartPos" SG_ 268 MC_ENG_RQ_ESC 7;
BA_ "FlexKomSigStartValue" SG_ 268 MC_ENG_RQ_ESC "00000000FF0000FFh";
BA_ "GenSigCycleTime" SG_ 268 MC_ENG_RQ_ESC 20;
BA_ "GenSigSNA" SG_ 268 MC_ENG_RQ_ESC "0h";
BA_ "FlexKomComment" SG_ 268 PrefillActive "Engine torque request from ESC";
BA_ "FlexKomIsMotorola" SG_ 268 PrefillActive 1;
BA_ "FlexKomSID" SG_ 268 PrefillActive 1;
BA_ "FlexKomSigLaenge" SG_ 268 PrefillActive 64;
BA_ "FlexKomSigName" SG_ 268 PrefillActive "Eng_Trq_Rq";
BA_ "FlexKomSigStartPos" SG_ 268 PrefillActive 7;
BA_ "FlexKomSigStartValue" SG_ 268 PrefillActive "00000000FF0000FFh";
BA_ "GenSigCycleTime" SG_ 268 PrefillActive 20;
BA_ "GenSigSNA" SG_ 268 PrefillActive "0h";
BA_ "FlexKomComment" SG_ 331 BrkPrss_TMC "ESC data";
BA_ "FlexKomIsMotorola" SG_ 331 BrkPrss_TMC 1;
BA_ "FlexKomSID" SG_ 331 BrkPrss_TMC 1416;
BA_ "FlexKomSigLaenge" SG_ 331 BrkPrss_TMC 64;
BA_ "FlexKomSigName" SG_ 331 BrkPrss_TMC "ESC_data";
BA_ "FlexKomSigStartPos" SG_ 331 BrkPrss_TMC 7;
BA_ "FlexKomSigStartValue" SG_ 331 BrkPrss_TMC "0000FFFF00FF00FFh";
BA_ "GenSigCycleTime" SG_ 331 BrkPrss_TMC 20;
BA_ "GenSigSNA" SG_ 331 BrkPrss_TMC "7FFh";
BA_ "GenSigTimeout_ETM" SG_ 331 BrkPrss_TMC 210;
BA_ "GenSigTimeout_IC" SG_ 331 BrkPrss_TMC 210;
BA_ "GenSigTimeout_ORC" SG_ 331 BrkPrss_TMC 70;
BA_ "FlexKomComment" SG_ 331 CRC_ESP_A3 "ESC data";
BA_ "FlexKomIsMotorola" SG_ 331 CRC_ESP_A3 1;
BA_ "FlexKomSID" SG_ 331 CRC_ESP_A3 1416;
BA_ "FlexKomSigLaenge" SG_ 331 CRC_ESP_A3 64;
BA_ "FlexKomSigName" SG_ 331 CRC_ESP_A3 "ESC_data";
BA_ "FlexKomSigStartPos" SG_ 331 CRC_ESP_A3 7;
BA_ "FlexKomSigStartValue" SG_ 331 CRC_ESP_A3 "0000FFFF00FF00FFh";
BA_ "GenSigCycleTime" SG_ 331 CRC_ESP_A3 20;
BA_ "GenSigSNA" SG_ 331 CRC_ESP_A3 "FFh";
BA_ "GenSigStartValue" SG_ 331 CRC_ESP_A3 255;
BA_ "GenSigTimeout_ORC" SG_ 331 CRC_ESP_A3 70;
BA_ "FlexKomComment" SG_ 331 HSA_BrkPrss "ESC data";
BA_ "FlexKomIsMotorola" SG_ 331 HSA_BrkPrss 1;
BA_ "FlexKomSID" SG_ 331 HSA_BrkPrss 1416;
BA_ "FlexKomSigLaenge" SG_ 331 HSA_BrkPrss 64;
BA_ "FlexKomSigName" SG_ 331 HSA_BrkPrss "ESC_data";
BA_ "FlexKomSigStartPos" SG_ 331 HSA_BrkPrss 7;
BA_ "FlexKomSigStartValue" SG_ 331 HSA_BrkPrss "0000FFFF00FF00FFh";
BA_ "GenSigCycleTime" SG_ 331 HSA_BrkPrss 20;
BA_ "GenSigSNA" SG_ 331 HSA_BrkPrss "3Fh";
BA_ "GenSigTimeout_ETM" SG_ 331 HSA_BrkPrss 210;
BA_ "GenSigTimeout_ORC" SG_ 331 HSA_BrkPrss 70;
BA_ "FlexKomComment" SG_ 331 MC_ESP_A3 "ESC data";
BA_ "FlexKomIsMotorola" SG_ 331 MC_ESP_A3 1;
BA_ "FlexKomSID" SG_ 331 MC_ESP_A3 1416;
BA_ "FlexKomSigLaenge" SG_ 331 MC_ESP_A3 64;
BA_ "FlexKomSigName" SG_ 331 MC_ESP_A3 "ESC_data";
BA_ "FlexKomSigStartPos" SG_ 331 MC_ESP_A3 7;
BA_ "FlexKomSigStartValue" SG_ 331 MC_ESP_A3 "0000FFFF00FF00FFh";
BA_ "GenSigCycleTime" SG_ 331 MC_ESP_A3 20;
BA_ "GenSigSNA" SG_ 331 MC_ESP_A3 "0h";
BA_ "GenSigTimeout_ORC" SG_ 331 MC_ESP_A3 70;
BA_ "FlexKomComment" SG_ 331 PTS_Brk_Rq_RspSts "ESC data";
BA_ "FlexKomIsMotorola" SG_ 331 PTS_Brk_Rq_RspSts 1;
BA_ "FlexKomSID" SG_ 331 PTS_Brk_Rq_RspSts 1416;
BA_ "FlexKomSigLaenge" SG_ 331 PTS_Brk_Rq_RspSts 64;
BA_ "FlexKomSigName" SG_ 331 PTS_Brk_Rq_RspSts "ESC_data";
BA_ "FlexKomSigStartPos" SG_ 331 PTS_Brk_Rq_RspSts 7;
BA_ "FlexKomSigStartValue" SG_ 331 PTS_Brk_Rq_RspSts "0000FFFF00FF00FFh";
BA_ "GenSigCycleTime" SG_ 331 PTS_Brk_Rq_RspSts 20;
BA_ "GenSigSNA" SG_ 331 PTS_Brk_Rq_RspSts "3h";
BA_ "GenSigTimeout_IC" SG_ 331 PTS_Brk_Rq_RspSts 210;
BA_ "GenSigTimeout_PTS" SG_ 331 PTS_Brk_Rq_RspSts 210;
BA_ "FlexKomComment" SG_ 332 MC_VEH_DYN_STAT "Message counter";
BA_ "FlexKomIsMotorola" SG_ 332 MC_VEH_DYN_STAT 1;
BA_ "FlexKomSID" SG_ 332 MC_VEH_DYN_STAT 1267;
BA_ "FlexKomSigLaenge" SG_ 332 MC_VEH_DYN_STAT 4;
BA_ "FlexKomSigName" SG_ 332 MC_VEH_DYN_STAT "MC_VEH_DYN_STAT";
BA_ "FlexKomSigStartPos" SG_ 332 MC_VEH_DYN_STAT 55;
BA_ "FlexKomSigStartValue" SG_ 332 MC_VEH_DYN_STAT "00h";
BA_ "GenSigCycleTime" SG_ 332 MC_VEH_DYN_STAT 20;
BA_ "GenSigSNA" SG_ 332 MC_VEH_DYN_STAT "0h";
BA_ "GenSigTimeout_ETM" SG_ 332 MC_VEH_DYN_STAT 210;
BA_ "GenSigTimeout_ORC" SG_ 332 MC_VEH_DYN_STAT 70;
BA_ "FlexKomComment" SG_ 332 VehAccel_X "Vehicle longitudinal acceleration (+ means forward";
BA_ "FlexKomIsMotorola" SG_ 332 VehAccel_X 1;
BA_ "FlexKomSID" SG_ 332 VehAccel_X 1265;
BA_ "FlexKomSigLaenge" SG_ 332 VehAccel_X 8;
BA_ "FlexKomSigName" SG_ 332 VehAccel_X "VehAccel_X";
BA_ "FlexKomSigStartPos" SG_ 332 VehAccel_X 39;
BA_ "FlexKomSigStartValue" SG_ 332 VehAccel_X "FFh";
BA_ "GenSigCycleTime" SG_ 332 VehAccel_X 20;
BA_ "GenSigSNA" SG_ 332 VehAccel_X "FFh";
BA_ "GenSigStartValue" SG_ 332 VehAccel_X 255;
BA_ "GenSigTimeout_CBC" SG_ 332 VehAccel_X 210;
BA_ "GenSigTimeout_IC" SG_ 332 VehAccel_X 210;
BA_ "GenSigTimeout_ORC" SG_ 332 VehAccel_X 70;
BA_ "RID" SG_ 332 VehAccel_X "1277";
BA_ "FlexKomComment" SG_ 332 VehAccel_X_Offset "Offset of vehicle longitudinal acceleration (+ mea";
BA_ "FlexKomIsMotorola" SG_ 332 VehAccel_X_Offset 1;
BA_ "FlexKomSID" SG_ 332 VehAccel_X_Offset 1264;
BA_ "FlexKomSigLaenge" SG_ 332 VehAccel_X_Offset 8;
BA_ "FlexKomSigName" SG_ 332 VehAccel_X_Offset "VehAccel_X_Offset";
BA_ "FlexKomSigStartPos" SG_ 332 VehAccel_X_Offset 31;
BA_ "FlexKomSigStartValue" SG_ 332 VehAccel_X_Offset "FFh";
BA_ "GenSigCycleTime" SG_ 332 VehAccel_X_Offset 20;
BA_ "GenSigSNA" SG_ 332 VehAccel_X_Offset "FFh";
BA_ "GenSigStartValue" SG_ 332 VehAccel_X_Offset 255;
BA_ "GenSigTimeout_ETM" SG_ 332 VehAccel_X_Offset 210;
BA_ "GenSigTimeout_IC" SG_ 332 VehAccel_X_Offset 210;
BA_ "GenSigTimeout_ORC" SG_ 332 VehAccel_X_Offset 70;
BA_ "FlexKomComment" SG_ 332 VehAccel_Y "Vehicle lateral acceleration (+ means left, specif";
BA_ "FlexKomIsMotorola" SG_ 332 VehAccel_Y 1;
BA_ "FlexKomSID" SG_ 332 VehAccel_Y 1266;
BA_ "FlexKomSigLaenge" SG_ 332 VehAccel_Y 8;
BA_ "FlexKomSigName" SG_ 332 VehAccel_Y "VehAccel_Y";
BA_ "FlexKomSigStartPos" SG_ 332 VehAccel_Y 47;
BA_ "FlexKomSigStartValue" SG_ 332 VehAccel_Y "FFh";
BA_ "GenSigCycleTime" SG_ 332 VehAccel_Y 20;
BA_ "GenSigSNA" SG_ 332 VehAccel_Y "FFh";
BA_ "GenSigStartValue" SG_ 332 VehAccel_Y 255;
BA_ "GenSigTimeout_CBC" SG_ 332 VehAccel_Y 210;
BA_ "GenSigTimeout_IC" SG_ 332 VehAccel_Y 210;
BA_ "GenSigTimeout_ORC" SG_ 332 VehAccel_Y 70;
BA_ "RID" SG_ 332 VehAccel_Y "1137";
BA_ "FlexKomComment" SG_ 332 VehAccel_Y_Offset "Offset of vehicle lateral acceleration (+ means le";
BA_ "FlexKomIsMotorola" SG_ 332 VehAccel_Y_Offset 1;
BA_ "FlexKomSID" SG_ 332 VehAccel_Y_Offset 1268;
BA_ "FlexKomSigLaenge" SG_ 332 VehAccel_Y_Offset 8;
BA_ "FlexKomSigName" SG_ 332 VehAccel_Y_Offset "VehAccel_Y_Offset";
BA_ "FlexKomSigStartPos" SG_ 332 VehAccel_Y_Offset 63;
BA_ "FlexKomSigStartValue" SG_ 332 VehAccel_Y_Offset "FFh";
BA_ "GenSigCycleTime" SG_ 332 VehAccel_Y_Offset 20;
BA_ "GenSigSNA" SG_ 332 VehAccel_Y_Offset "FFh";
BA_ "GenSigStartValue" SG_ 332 VehAccel_Y_Offset 255;
BA_ "GenSigTimeout_ETM" SG_ 332 VehAccel_Y_Offset 210;
BA_ "GenSigTimeout_IC" SG_ 332 VehAccel_Y_Offset 210;
BA_ "GenSigTimeout_ORC" SG_ 332 VehAccel_Y_Offset 70;
BA_ "FlexKomComment" SG_ 332 VehYawRate_Offset "Offset of vehicle yaw rate unfiltered/unadjusted (";
BA_ "FlexKomIsMotorola" SG_ 332 VehYawRate_Offset 1;
BA_ "FlexKomSID" SG_ 332 VehYawRate_Offset 1263;
BA_ "FlexKomSigLaenge" SG_ 332 VehYawRate_Offset 8;
BA_ "FlexKomSigName" SG_ 332 VehYawRate_Offset "VehYawRate_Offset";
BA_ "FlexKomSigStartPos" SG_ 332 VehYawRate_Offset 23;
BA_ "FlexKomSigStartValue" SG_ 332 VehYawRate_Offset "FFh";
BA_ "GenSigCycleTime" SG_ 332 VehYawRate_Offset 20;
BA_ "GenSigSNA" SG_ 332 VehYawRate_Offset "FFh";
BA_ "GenSigStartValue" SG_ 332 VehYawRate_Offset 255;
BA_ "GenSigTimeout_CBC" SG_ 332 VehYawRate_Offset 210;
BA_ "GenSigTimeout_ETM" SG_ 332 VehYawRate_Offset 210;
BA_ "GenSigTimeout_IC" SG_ 332 VehYawRate_Offset 210;
BA_ "GenSigTimeout_ORC" SG_ 332 VehYawRate_Offset 70;
BA_ "RID" SG_ 332 VehYawRate_Offset "1299 1710 5037";
BA_ "FlexKomComment" SG_ 332 VehYawRate_Raw "Vehicle yaw rate unfiltered/unadjusted (+ means le";
BA_ "FlexKomIsMotorola" SG_ 332 VehYawRate_Raw 1;
BA_ "FlexKomSID" SG_ 332 VehYawRate_Raw 1262;
BA_ "FlexKomSigLaenge" SG_ 332 VehYawRate_Raw 16;
BA_ "FlexKomSigName" SG_ 332 VehYawRate_Raw "VehYawRate_Raw";
BA_ "FlexKomSigStartPos" SG_ 332 VehYawRate_Raw 7;
BA_ "FlexKomSigStartValue" SG_ 332 VehYawRate_Raw "FFFFh";
BA_ "GenSigCycleTime" SG_ 332 VehYawRate_Raw 20;
BA_ "GenSigSNA" SG_ 332 VehYawRate_Raw "FFFFh";
BA_ "GenSigStartValue" SG_ 332 VehYawRate_Raw 65535;
BA_ "GenSigTimeout_CBC" SG_ 332 VehYawRate_Raw 210;
BA_ "GenSigTimeout_IC" SG_ 332 VehYawRate_Raw 210;
BA_ "GenSigTimeout_ORC" SG_ 332 VehYawRate_Raw 70;
BA_ "RID" SG_ 332 VehYawRate_Raw "1058 1289 1711";
BA_ "FlexKomComment" SG_ 292 WhlPlsCnt_FL "ESP Wheel pulse counts";
BA_ "FlexKomIsMotorola" SG_ 292 WhlPlsCnt_FL 1;
BA_ "FlexKomSID" SG_ 292 WhlPlsCnt_FL 65;
BA_ "FlexKomSigLaenge" SG_ 292 WhlPlsCnt_FL 32;
BA_ "FlexKomSigName" SG_ 292 WhlPlsCnt_FL "ESP_WHL_PULS";
BA_ "FlexKomSigStartPos" SG_ 292 WhlPlsCnt_FL 7;
BA_ "FlexKomSigStartValue" SG_ 292 WhlPlsCnt_FL "00000000h";
BA_ "GenSigCycleTime" SG_ 292 WhlPlsCnt_FL 20;
BA_ "GenSigSNA" SG_ 292 WhlPlsCnt_FL "FFh";
BA_ "GenSigTimeout_CBC" SG_ 292 WhlPlsCnt_FL 210;
BA_ "GenSigTimeout_IC" SG_ 292 WhlPlsCnt_FL 210;
BA_ "RID" SG_ 292 WhlPlsCnt_FL "1251";
BA_ "FlexKomComment" SG_ 292 WhlPlsCnt_FR "ESP Wheel pulse counts";
BA_ "FlexKomIsMotorola" SG_ 292 WhlPlsCnt_FR 1;
BA_ "FlexKomSID" SG_ 292 WhlPlsCnt_FR 65;
BA_ "FlexKomSigLaenge" SG_ 292 WhlPlsCnt_FR 32;
BA_ "FlexKomSigName" SG_ 292 WhlPlsCnt_FR "ESP_WHL_PULS";
BA_ "FlexKomSigStartPos" SG_ 292 WhlPlsCnt_FR 7;
BA_ "FlexKomSigStartValue" SG_ 292 WhlPlsCnt_FR "00000000h";
BA_ "GenSigCycleTime" SG_ 292 WhlPlsCnt_FR 20;
BA_ "GenSigSNA" SG_ 292 WhlPlsCnt_FR "FFh";
BA_ "GenSigTimeout_CBC" SG_ 292 WhlPlsCnt_FR 210;
BA_ "GenSigTimeout_IC" SG_ 292 WhlPlsCnt_FR 210;
BA_ "RID" SG_ 292 WhlPlsCnt_FR "1086";
BA_ "FlexKomComment" SG_ 292 WhlPlsCnt_RL "ESP Wheel pulse counts";
BA_ "FlexKomIsMotorola" SG_ 292 WhlPlsCnt_RL 1;
BA_ "FlexKomSID" SG_ 292 WhlPlsCnt_RL 65;
BA_ "FlexKomSigLaenge" SG_ 292 WhlPlsCnt_RL 32;
BA_ "FlexKomSigName" SG_ 292 WhlPlsCnt_RL "ESP_WHL_PULS";
BA_ "FlexKomSigStartPos" SG_ 292 WhlPlsCnt_RL 7;
BA_ "FlexKomSigStartValue" SG_ 292 WhlPlsCnt_RL "00000000h";
BA_ "GenSigCycleTime" SG_ 292 WhlPlsCnt_RL 20;
BA_ "GenSigSNA" SG_ 292 WhlPlsCnt_RL "FFh";
BA_ "GenSigTimeout_CBC" SG_ 292 WhlPlsCnt_RL 210;
BA_ "GenSigTimeout_IC" SG_ 292 WhlPlsCnt_RL 210;
BA_ "RID" SG_ 292 WhlPlsCnt_RL "1049";
BA_ "FlexKomComment" SG_ 292 WhlPlsCnt_RR "ESP Wheel pulse counts";
BA_ "FlexKomIsMotorola" SG_ 292 WhlPlsCnt_RR 1;
BA_ "FlexKomSID" SG_ 292 WhlPlsCnt_RR 65;
BA_ "FlexKomSigLaenge" SG_ 292 WhlPlsCnt_RR 32;
BA_ "FlexKomSigName" SG_ 292 WhlPlsCnt_RR "ESP_WHL_PULS";
BA_ "FlexKomSigStartPos" SG_ 292 WhlPlsCnt_RR 7;
BA_ "FlexKomSigStartValue" SG_ 292 WhlPlsCnt_RR "00000000h";
BA_ "GenSigCycleTime" SG_ 292 WhlPlsCnt_RR 20;
BA_ "GenSigSNA" SG_ 292 WhlPlsCnt_RR "FFh";
BA_ "GenSigTimeout_CBC" SG_ 292 WhlPlsCnt_RR 210;
BA_ "GenSigTimeout_IC" SG_ 292 WhlPlsCnt_RR 210;
BA_ "RID" SG_ 292 WhlPlsCnt_RR "1047";
BA_ "FlexKomComment" SG_ 344 WhlDir_FL_Stat "ESP Wheel Speed";
BA_ "FlexKomIsMotorola" SG_ 344 WhlDir_FL_Stat 1;
BA_ "FlexKomSID" SG_ 344 WhlDir_FL_Stat 64;
BA_ "FlexKomSigLaenge" SG_ 344 WhlDir_FL_Stat 64;
BA_ "FlexKomSigName" SG_ 344 WhlDir_FL_Stat "WHEEL_SPEED";
BA_ "FlexKomSigStartPos" SG_ 344 WhlDir_FL_Stat 7;
BA_ "FlexKomSigStartValue" SG_ 344 WhlDir_FL_Stat "FFFFFFFFFFFFFFFFh";
BA_ "GenSigCycleTime" SG_ 344 WhlDir_FL_Stat 20;
BA_ "GenSigSNA" SG_ 344 WhlDir_FL_Stat "3h";
BA_ "GenSigStartValue" SG_ 344 WhlDir_FL_Stat 3;
BA_ "GenSigTimeout_ORC" SG_ 344 WhlDir_FL_Stat 70;
BA_ "FlexKomComment" SG_ 344 WhlDir_FR_Stat "ESP Wheel Speed";
BA_ "FlexKomIsMotorola" SG_ 344 WhlDir_FR_Stat 1;
BA_ "FlexKomSID" SG_ 344 WhlDir_FR_Stat 64;
BA_ "FlexKomSigLaenge" SG_ 344 WhlDir_FR_Stat 64;
BA_ "FlexKomSigName" SG_ 344 WhlDir_FR_Stat "WHEEL_SPEED";
BA_ "FlexKomSigStartPos" SG_ 344 WhlDir_FR_Stat 7;
BA_ "FlexKomSigStartValue" SG_ 344 WhlDir_FR_Stat "FFFFFFFFFFFFFFFFh";
BA_ "GenSigCycleTime" SG_ 344 WhlDir_FR_Stat 20;
BA_ "GenSigSNA" SG_ 344 WhlDir_FR_Stat "3h";
BA_ "GenSigStartValue" SG_ 344 WhlDir_FR_Stat 3;
BA_ "GenSigTimeout_ORC" SG_ 344 WhlDir_FR_Stat 70;
BA_ "FlexKomComment" SG_ 344 WhlDir_RL_Stat "ESP Wheel Speed";
BA_ "FlexKomIsMotorola" SG_ 344 WhlDir_RL_Stat 1;
BA_ "FlexKomSID" SG_ 344 WhlDir_RL_Stat 64;
BA_ "FlexKomSigLaenge" SG_ 344 WhlDir_RL_Stat 64;
BA_ "FlexKomSigName" SG_ 344 WhlDir_RL_Stat "WHEEL_SPEED";
BA_ "FlexKomSigStartPos" SG_ 344 WhlDir_RL_Stat 7;
BA_ "FlexKomSigStartValue" SG_ 344 WhlDir_RL_Stat "FFFFFFFFFFFFFFFFh";
BA_ "GenSigCycleTime" SG_ 344 WhlDir_RL_Stat 20;
BA_ "GenSigSNA" SG_ 344 WhlDir_RL_Stat "3h";
BA_ "GenSigStartValue" SG_ 344 WhlDir_RL_Stat 3;
BA_ "GenSigTimeout_ORC" SG_ 344 WhlDir_RL_Stat 70;
BA_ "RID" SG_ 344 WhlDir_RL_Stat "9775";
BA_ "FlexKomComment" SG_ 344 WhlDir_RR_Stat "ESP Wheel Speed";
BA_ "FlexKomIsMotorola" SG_ 344 WhlDir_RR_Stat 1;
BA_ "FlexKomSID" SG_ 344 WhlDir_RR_Stat 64;
BA_ "FlexKomSigLaenge" SG_ 344 WhlDir_RR_Stat 64;
BA_ "FlexKomSigName" SG_ 344 WhlDir_RR_Stat "WHEEL_SPEED";
BA_ "FlexKomSigStartPos" SG_ 344 WhlDir_RR_Stat 7;
BA_ "FlexKomSigStartValue" SG_ 344 WhlDir_RR_Stat "FFFFFFFFFFFFFFFFh";
BA_ "GenSigCycleTime" SG_ 344 WhlDir_RR_Stat 20;
BA_ "GenSigSNA" SG_ 344 WhlDir_RR_Stat "3h";
BA_ "GenSigStartValue" SG_ 344 WhlDir_RR_Stat 3;
BA_ "GenSigTimeout_ORC" SG_ 344 WhlDir_RR_Stat 70;
BA_ "RID" SG_ 344 WhlDir_RR_Stat "9776";
BA_ "FlexKomComment" SG_ 344 WhlRPM_FL "ESP Wheel Speed";
BA_ "FlexKomIsMotorola" SG_ 344 WhlRPM_FL 1;
BA_ "FlexKomSID" SG_ 344 WhlRPM_FL 64;
BA_ "FlexKomSigLaenge" SG_ 344 WhlRPM_FL 64;
BA_ "FlexKomSigName" SG_ 344 WhlRPM_FL "WHEEL_SPEED";
BA_ "FlexKomSigStartPos" SG_ 344 WhlRPM_FL 7;
BA_ "FlexKomSigStartValue" SG_ 344 WhlRPM_FL "FFFFFFFFFFFFFFFFh";
BA_ "GenSigCycleTime" SG_ 344 WhlRPM_FL 20;
BA_ "GenSigSNA" SG_ 344 WhlRPM_FL "3FFFh";
BA_ "GenSigStartValue" SG_ 344 WhlRPM_FL 16383;
BA_ "GenSigTimeout_ESL" SG_ 344 WhlRPM_FL 210;
BA_ "GenSigTimeout_ORC" SG_ 344 WhlRPM_FL 70;
BA_ "FlexKomComment" SG_ 344 WhlRPM_FR "ESP Wheel Speed";
BA_ "FlexKomIsMotorola" SG_ 344 WhlRPM_FR 1;
BA_ "FlexKomSID" SG_ 344 WhlRPM_FR 64;
BA_ "FlexKomSigLaenge" SG_ 344 WhlRPM_FR 64;
BA_ "FlexKomSigName" SG_ 344 WhlRPM_FR "WHEEL_SPEED";
BA_ "FlexKomSigStartPos" SG_ 344 WhlRPM_FR 7;
BA_ "FlexKomSigStartValue" SG_ 344 WhlRPM_FR "FFFFFFFFFFFFFFFFh";
BA_ "GenSigCycleTime" SG_ 344 WhlRPM_FR 20;
BA_ "GenSigSNA" SG_ 344 WhlRPM_FR "3FFFh";
BA_ "GenSigStartValue" SG_ 344 WhlRPM_FR 16383;
BA_ "GenSigTimeout_ESL" SG_ 344 WhlRPM_FR 210;
BA_ "GenSigTimeout_ORC" SG_ 344 WhlRPM_FR 70;
BA_ "FlexKomComment" SG_ 344 WhlRPM_RL "ESP Wheel Speed";
BA_ "FlexKomIsMotorola" SG_ 344 WhlRPM_RL 1;
BA_ "FlexKomSID" SG_ 344 WhlRPM_RL 64;
BA_ "FlexKomSigLaenge" SG_ 344 WhlRPM_RL 64;
BA_ "FlexKomSigName" SG_ 344 WhlRPM_RL "WHEEL_SPEED";
BA_ "FlexKomSigStartPos" SG_ 344 WhlRPM_RL 7;
BA_ "FlexKomSigStartValue" SG_ 344 WhlRPM_RL "FFFFFFFFFFFFFFFFh";
BA_ "GenSigCycleTime" SG_ 344 WhlRPM_RL 20;
BA_ "GenSigSNA" SG_ 344 WhlRPM_RL "3FFFh";
BA_ "GenSigStartValue" SG_ 344 WhlRPM_RL 16383;
BA_ "GenSigTimeout_CBC" SG_ 344 WhlRPM_RL 110;
BA_ "GenSigTimeout_ESL" SG_ 344 WhlRPM_RL 210;
BA_ "GenSigTimeout_ORC" SG_ 344 WhlRPM_RL 70;
BA_ "FlexKomComment" SG_ 344 WhlRPM_RR "ESP Wheel Speed";
BA_ "FlexKomIsMotorola" SG_ 344 WhlRPM_RR 1;
BA_ "FlexKomSID" SG_ 344 WhlRPM_RR 64;
BA_ "FlexKomSigLaenge" SG_ 344 WhlRPM_RR 64;
BA_ "FlexKomSigName" SG_ 344 WhlRPM_RR "WHEEL_SPEED";
BA_ "FlexKomSigStartPos" SG_ 344 WhlRPM_RR 7;
BA_ "FlexKomSigStartValue" SG_ 344 WhlRPM_RR "FFFFFFFFFFFFFFFFh";
BA_ "GenSigCycleTime" SG_ 344 WhlRPM_RR 20;
BA_ "GenSigSNA" SG_ 344 WhlRPM_RR "3FFFh";
BA_ "GenSigStartValue" SG_ 344 WhlRPM_RR 16383;
BA_ "GenSigTimeout_CBC" SG_ 344 WhlRPM_RR 110;
BA_ "GenSigTimeout_ESL" SG_ 344 WhlRPM_RR 210;
BA_ "GenSigTimeout_ORC" SG_ 344 WhlRPM_RR 70;
BA_ "FlexKomComment" SG_ 284 BrkTrq "Vehicle Speed Packet";
BA_ "FlexKomIsMotorola" SG_ 284 BrkTrq 1;
BA_ "FlexKomSID" SG_ 284 BrkTrq 9006;
BA_ "FlexKomSigLaenge" SG_ 284 BrkTrq 64;
BA_ "FlexKomSigName" SG_ 284 BrkTrq "VEH_SPEED_PKT";
BA_ "FlexKomSigStartPos" SG_ 284 BrkTrq 7;
BA_ "FlexKomSigStartValue" SG_ 284 BrkTrq "0FFF0FFFFFFF00FFh";
BA_ "GenSigCycleTime" SG_ 284 BrkTrq 20;
BA_ "GenSigSNA" SG_ 284 BrkTrq "FFFh";
BA_ "GenSigStartValue" SG_ 284 BrkTrq 4095;
BA_ "GenSigTimeout_CBC" SG_ 284 BrkTrq 210;
BA_ "FlexKomComment" SG_ 284 BrkTrq_D "Vehicle Speed Packet";
BA_ "FlexKomIsMotorola" SG_ 284 BrkTrq_D 1;
BA_ "FlexKomSID" SG_ 284 BrkTrq_D 9006;
BA_ "FlexKomSigLaenge" SG_ 284 BrkTrq_D 64;
BA_ "FlexKomSigName" SG_ 284 BrkTrq_D "VEH_SPEED_PKT";
BA_ "FlexKomSigStartPos" SG_ 284 BrkTrq_D 7;
BA_ "FlexKomSigStartValue" SG_ 284 BrkTrq_D "0FFF0FFFFFFF00FFh";
BA_ "GenSigCycleTime" SG_ 284 BrkTrq_D 20;
BA_ "GenSigSNA" SG_ 284 BrkTrq_D "FFFh";
BA_ "GenSigStartValue" SG_ 284 BrkTrq_D 4095;
BA_ "FlexKomComment" SG_ 284 CRC_VEH_SPEED "Vehicle Speed Packet";
BA_ "FlexKomIsMotorola" SG_ 284 CRC_VEH_SPEED 1;
BA_ "FlexKomSID" SG_ 284 CRC_VEH_SPEED 9006;
BA_ "FlexKomSigLaenge" SG_ 284 CRC_VEH_SPEED 64;
BA_ "FlexKomSigName" SG_ 284 CRC_VEH_SPEED "VEH_SPEED_PKT";
BA_ "FlexKomSigStartPos" SG_ 284 CRC_VEH_SPEED 7;
BA_ "FlexKomSigStartValue" SG_ 284 CRC_VEH_SPEED "0FFF0FFFFFFF00FFh";
BA_ "GenSigCycleTime" SG_ 284 CRC_VEH_SPEED 20;
BA_ "GenSigSNA" SG_ 284 CRC_VEH_SPEED "FFh";
BA_ "GenSigStartValue" SG_ 284 CRC_VEH_SPEED 255;
BA_ "GenSigTimeout_CBC" SG_ 284 CRC_VEH_SPEED 110;
BA_ "GenSigTimeout_EPS" SG_ 284 CRC_VEH_SPEED 210;
BA_ "GenSigTimeout_ESL" SG_ 284 CRC_VEH_SPEED 110;
BA_ "GenSigTimeout_IC" SG_ 284 CRC_VEH_SPEED 210;
BA_ "GenSigTimeout_ORC" SG_ 284 CRC_VEH_SPEED 70;
BA_ "FlexKomComment" SG_ 284 MC_VEH_SPEED "Vehicle Speed Packet";
BA_ "FlexKomIsMotorola" SG_ 284 MC_VEH_SPEED 1;
BA_ "FlexKomSID" SG_ 284 MC_VEH_SPEED 9006;
BA_ "FlexKomSigLaenge" SG_ 284 MC_VEH_SPEED 64;
BA_ "FlexKomSigName" SG_ 284 MC_VEH_SPEED "VEH_SPEED_PKT";
BA_ "FlexKomSigStartPos" SG_ 284 MC_VEH_SPEED 7;
BA_ "FlexKomSigStartValue" SG_ 284 MC_VEH_SPEED "0FFF0FFFFFFF00FFh";
BA_ "GenSigCycleTime" SG_ 284 MC_VEH_SPEED 20;
BA_ "GenSigSNA" SG_ 284 MC_VEH_SPEED "0h";
BA_ "GenSigTimeout_CBC" SG_ 284 MC_VEH_SPEED 110;
BA_ "GenSigTimeout_EPS" SG_ 284 MC_VEH_SPEED 210;
BA_ "GenSigTimeout_ESL" SG_ 284 MC_VEH_SPEED 110;
BA_ "GenSigTimeout_IC" SG_ 284 MC_VEH_SPEED 210;
BA_ "GenSigTimeout_ORC" SG_ 284 MC_VEH_SPEED 70;
BA_ "RID" SG_ 284 MC_VEH_SPEED "9748";
BA_ "FlexKomComment" SG_ 284 VEH_SPEED "Vehicle Speed Packet";
BA_ "FlexKomIsMotorola" SG_ 284 VEH_SPEED 1;
BA_ "FlexKomSID" SG_ 284 VEH_SPEED 9006;
BA_ "FlexKomSigLaenge" SG_ 284 VEH_SPEED 64;
BA_ "FlexKomSigName" SG_ 284 VEH_SPEED "VEH_SPEED_PKT";
BA_ "FlexKomSigStartPos" SG_ 284 VEH_SPEED 7;
BA_ "FlexKomSigStartValue" SG_ 284 VEH_SPEED "0FFF0FFFFFFF00FFh";
BA_ "GenSigCycleTime" SG_ 284 VEH_SPEED 20;
BA_ "GenSigSNA" SG_ 284 VEH_SPEED "FFFFh";
BA_ "GenSigStartValue" SG_ 284 VEH_SPEED 65535;
BA_ "GenSigTimeout_CBC" SG_ 284 VEH_SPEED 110;
BA_ "GenSigTimeout_EPS" SG_ 284 VEH_SPEED 210;
BA_ "GenSigTimeout_ESL" SG_ 284 VEH_SPEED 110;
BA_ "GenSigTimeout_IC" SG_ 284 VEH_SPEED 210;
BA_ "GenSigTimeout_ORC" SG_ 284 VEH_SPEED 70;
BA_ "GenSigTimeout_RF_HUB" SG_ 284 VEH_SPEED 210;
BA_ "RID" SG_ 284 VEH_SPEED "2861 2862 2863";
BA_ "FlexKomComment" SG_ 284 VehSpSts "Vehicle Speed Packet";
BA_ "FlexKomIsMotorola" SG_ 284 VehSpSts 1;
BA_ "FlexKomSID" SG_ 284 VehSpSts 9006;
BA_ "FlexKomSigLaenge" SG_ 284 VehSpSts 64;
BA_ "FlexKomSigName" SG_ 284 VehSpSts "VEH_SPEED_PKT";
BA_ "FlexKomSigStartPos" SG_ 284 VehSpSts 7;
BA_ "FlexKomSigStartValue" SG_ 284 VehSpSts "0FFF0FFFFFFF00FFh";
BA_ "GenSigCycleTime" SG_ 284 VehSpSts 20;
BA_ "GenSigSNA" SG_ 284 VehSpSts "0h";
BA_ "FlexKomComment" SG_ 270 AHH_Status "ESP_A9_Pkt";
BA_ "FlexKomIsMotorola" SG_ 270 AHH_Status 1;
BA_ "FlexKomSID" SG_ 270 AHH_Status 2519;
BA_ "FlexKomSigLaenge" SG_ 270 AHH_Status 64;
BA_ "FlexKomSigName" SG_ 270 AHH_Status "ESP_A9_Pkt";
BA_ "FlexKomSigStartPos" SG_ 270 AHH_Status 7;
BA_ "FlexKomSigStartValue" SG_ 270 AHH_Status "00000000000000FFh";
BA_ "GenSigCycleTime" SG_ 270 AHH_Status 20;
BA_ "GenSigSNA" SG_ 270 AHH_Status "7h";
BA_ "FlexKomComment" SG_ 270 CRC_10Eh "ESP_A9_Pkt";
BA_ "FlexKomIsMotorola" SG_ 270 CRC_10Eh 1;
BA_ "FlexKomSID" SG_ 270 CRC_10Eh 2519;
BA_ "FlexKomSigLaenge" SG_ 270 CRC_10Eh 64;
BA_ "FlexKomSigName" SG_ 270 CRC_10Eh "ESP_A9_Pkt";
BA_ "FlexKomSigStartPos" SG_ 270 CRC_10Eh 7;
BA_ "FlexKomSigStartValue" SG_ 270 CRC_10Eh "00000000000000FFh";
BA_ "GenSigCycleTime" SG_ 270 CRC_10Eh 20;
BA_ "GenSigSNA" SG_ 270 CRC_10Eh "FFh";
BA_ "GenSigStartValue" SG_ 270 CRC_10Eh 255;
BA_ "FlexKomComment" SG_ 270 MC_10Eh "ESP_A9_Pkt";
BA_ "FlexKomIsMotorola" SG_ 270 MC_10Eh 1;
BA_ "FlexKomSID" SG_ 270 MC_10Eh 2519;
BA_ "FlexKomSigLaenge" SG_ 270 MC_10Eh 64;
BA_ "FlexKomSigName" SG_ 270 MC_10Eh "ESP_A9_Pkt";
BA_ "FlexKomSigStartPos" SG_ 270 MC_10Eh 7;
BA_ "FlexKomSigStartValue" SG_ 270 MC_10Eh "00000000000000FFh";
BA_ "GenSigCycleTime" SG_ 270 MC_10Eh 20;
BA_ "GenSigSNA" SG_ 270 MC_10Eh "0h";
BA_ "FlexKomComment" SG_ 270 WhlTrqAct_Rq_AS "ESP_A9_Pkt";
BA_ "FlexKomIsMotorola" SG_ 270 WhlTrqAct_Rq_AS 1;
BA_ "FlexKomSID" SG_ 270 WhlTrqAct_Rq_AS 2519;
BA_ "FlexKomSigLaenge" SG_ 270 WhlTrqAct_Rq_AS 64;
BA_ "FlexKomSigName" SG_ 270 WhlTrqAct_Rq_AS "ESP_A9_Pkt";
BA_ "FlexKomSigStartPos" SG_ 270 WhlTrqAct_Rq_AS 7;
BA_ "FlexKomSigStartValue" SG_ 270 WhlTrqAct_Rq_AS "00000000000000FFh";
BA_ "GenSigCycleTime" SG_ 270 WhlTrqAct_Rq_AS 20;
BA_ "GenSigSNA" SG_ 270 WhlTrqAct_Rq_AS "0h";
BA_ "FlexKomComment" SG_ 270 WhlTrqMax_Rq_ESC "ESP_A9_Pkt";
BA_ "FlexKomIsMotorola" SG_ 270 WhlTrqMax_Rq_ESC 1;
BA_ "FlexKomSID" SG_ 270 WhlTrqMax_Rq_ESC 2519;
BA_ "FlexKomSigLaenge" SG_ 270 WhlTrqMax_Rq_ESC 64;
BA_ "FlexKomSigName" SG_ 270 WhlTrqMax_Rq_ESC "ESP_A9_Pkt";
BA_ "FlexKomSigStartPos" SG_ 270 WhlTrqMax_Rq_ESC 7;
BA_ "FlexKomSigStartValue" SG_ 270 WhlTrqMax_Rq_ESC "00000000000000FFh";
BA_ "GenSigCycleTime" SG_ 270 WhlTrqMax_Rq_ESC 20;
BA_ "GenSigSNA" SG_ 270 WhlTrqMax_Rq_ESC "0h";
BA_ "GenSigTimeout_ORC" SG_ 270 WhlTrqMax_Rq_ESC 70;
BA_ "FlexKomComment" SG_ 270 WhlTrqMin_Rq_ESC "ESP_A9_Pkt";
BA_ "FlexKomIsMotorola" SG_ 270 WhlTrqMin_Rq_ESC 1;
BA_ "FlexKomSID" SG_ 270 WhlTrqMin_Rq_ESC 2519;
BA_ "FlexKomSigLaenge" SG_ 270 WhlTrqMin_Rq_ESC 64;
BA_ "FlexKomSigName" SG_ 270 WhlTrqMin_Rq_ESC "ESP_A9_Pkt";
BA_ "FlexKomSigStartPos" SG_ 270 WhlTrqMin_Rq_ESC 7;
BA_ "FlexKomSigStartValue" SG_ 270 WhlTrqMin_Rq_ESC "00000000000000FFh";
BA_ "GenSigCycleTime" SG_ 270 WhlTrqMin_Rq_ESC 20;
BA_ "GenSigSNA" SG_ 270 WhlTrqMin_Rq_ESC "0h";
BA_ "FlexKomComment" SG_ 270 WhlTrq_Rq_As "ESP_A9_Pkt";
BA_ "FlexKomIsMotorola" SG_ 270 WhlTrq_Rq_As 1;
BA_ "FlexKomSID" SG_ 270 WhlTrq_Rq_As 2519;
BA_ "FlexKomSigLaenge" SG_ 270 WhlTrq_Rq_As 64;
BA_ "FlexKomSigName" SG_ 270 WhlTrq_Rq_As "ESP_A9_Pkt";
BA_ "FlexKomSigStartPos" SG_ 270 WhlTrq_Rq_As 7;
BA_ "FlexKomSigStartValue" SG_ 270 WhlTrq_Rq_As "00000000000000FFh";
BA_ "GenSigCycleTime" SG_ 270 WhlTrq_Rq_As 20;
BA_ "GenSigSNA" SG_ 270 WhlTrq_Rq_As "7FFFh";
BA_ "GenSigTimeout_ORC" SG_ 270 WhlTrq_Rq_As 70;
BA_ "FlexKomComment" SG_ 270 WhlTrq_Rq_ESC "ESP_A9_Pkt";
BA_ "FlexKomIsMotorola" SG_ 270 WhlTrq_Rq_ESC 1;
BA_ "FlexKomSID" SG_ 270 WhlTrq_Rq_ESC 2519;
BA_ "FlexKomSigLaenge" SG_ 270 WhlTrq_Rq_ESC 64;
BA_ "FlexKomSigName" SG_ 270 WhlTrq_Rq_ESC "ESP_A9_Pkt";
BA_ "FlexKomSigStartPos" SG_ 270 WhlTrq_Rq_ESC 7;
BA_ "FlexKomSigStartValue" SG_ 270 WhlTrq_Rq_ESC "00000000000000FFh";
BA_ "GenSigCycleTime" SG_ 270 WhlTrq_Rq_ESC 20;
BA_ "GenSigSNA" SG_ 270 WhlTrq_Rq_ESC "7FFFh";
BA_ "FlexKomComment" SG_ 736 ABS_IndLmp_On_Rq "ESP Customer Indicators";
BA_ "FlexKomIsMotorola" SG_ 736 ABS_IndLmp_On_Rq 1;
BA_ "FlexKomSID" SG_ 736 ABS_IndLmp_On_Rq 397;
BA_ "FlexKomSigLaenge" SG_ 736 ABS_IndLmp_On_Rq 16;
BA_ "FlexKomSigName" SG_ 736 ABS_IndLmp_On_Rq "ESP_HMI";
BA_ "FlexKomSigStartPos" SG_ 736 ABS_IndLmp_On_Rq 55;
BA_ "FlexKomSigStartValue" SG_ 736 ABS_IndLmp_On_Rq "003Fh";
BA_ "GenSigCycleTime" SG_ 736 ABS_IndLmp_On_Rq 50;
BA_ "GenSigSNA" SG_ 736 ABS_IndLmp_On_Rq "3h";
BA_ "GenSigStartValue" SG_ 736 ABS_IndLmp_On_Rq 3;
BA_ "GenSigTimeout_ETM" SG_ 736 ABS_IndLmp_On_Rq 525;
BA_ "GenSigTimeout_IC" SG_ 736 ABS_IndLmp_On_Rq 275;
BA_ "FlexKomComment" SG_ 736 BrkIndLmp_On_Rq_ESC "ESP Customer Indicators";
BA_ "FlexKomIsMotorola" SG_ 736 BrkIndLmp_On_Rq_ESC 1;
BA_ "FlexKomSID" SG_ 736 BrkIndLmp_On_Rq_ESC 397;
BA_ "FlexKomSigLaenge" SG_ 736 BrkIndLmp_On_Rq_ESC 16;
BA_ "FlexKomSigName" SG_ 736 BrkIndLmp_On_Rq_ESC "ESP_HMI";
BA_ "FlexKomSigStartPos" SG_ 736 BrkIndLmp_On_Rq_ESC 55;
BA_ "FlexKomSigStartValue" SG_ 736 BrkIndLmp_On_Rq_ESC "003Fh";
BA_ "GenSigCycleTime" SG_ 736 BrkIndLmp_On_Rq_ESC 50;
BA_ "GenSigSNA" SG_ 736 BrkIndLmp_On_Rq_ESC "3h";
BA_ "GenSigStartValue" SG_ 736 BrkIndLmp_On_Rq_ESC 3;
BA_ "GenSigTimeout_ETM" SG_ 736 BrkIndLmp_On_Rq_ESC 525;
BA_ "GenSigTimeout_IC" SG_ 736 BrkIndLmp_On_Rq_ESC 275;
BA_ "FlexKomComment" SG_ 736 ESC_CtrlLmp_Info "ESP Customer Indicators";
BA_ "FlexKomIsMotorola" SG_ 736 ESC_CtrlLmp_Info 1;
BA_ "FlexKomSID" SG_ 736 ESC_CtrlLmp_Info 397;
BA_ "FlexKomSigLaenge" SG_ 736 ESC_CtrlLmp_Info 16;
BA_ "FlexKomSigName" SG_ 736 ESC_CtrlLmp_Info "ESP_HMI";
BA_ "FlexKomSigStartPos" SG_ 736 ESC_CtrlLmp_Info 55;
BA_ "FlexKomSigStartValue" SG_ 736 ESC_CtrlLmp_Info "003Fh";
BA_ "GenSigCycleTime" SG_ 736 ESC_CtrlLmp_Info 50;
BA_ "GenSigSNA" SG_ 736 ESC_CtrlLmp_Info "3h";
BA_ "GenSigStartValue" SG_ 736 ESC_CtrlLmp_Info 3;
BA_ "GenSigTimeout_ETM" SG_ 736 ESC_CtrlLmp_Info 525;
BA_ "GenSigTimeout_IC" SG_ 736 ESC_CtrlLmp_Info 275;
BA_ "GenSigTimeout_ORC" SG_ 736 ESC_CtrlLmp_Info 175;
BA_ "FlexKomComment" SG_ 736 ESP_Off_IndLmp_On_Rq "ESP Customer Indicators";
BA_ "FlexKomIsMotorola" SG_ 736 ESP_Off_IndLmp_On_Rq 1;
BA_ "FlexKomSID" SG_ 736 ESP_Off_IndLmp_On_Rq 397;
BA_ "FlexKomSigLaenge" SG_ 736 ESP_Off_IndLmp_On_Rq 16;
BA_ "FlexKomSigName" SG_ 736 ESP_Off_IndLmp_On_Rq "ESP_HMI";
BA_ "FlexKomSigStartPos" SG_ 736 ESP_Off_IndLmp_On_Rq 55;
BA_ "FlexKomSigStartValue" SG_ 736 ESP_Off_IndLmp_On_Rq "003Fh";
BA_ "GenSigCycleTime" SG_ 736 ESP_Off_IndLmp_On_Rq 50;
BA_ "GenSigSNA" SG_ 736 ESP_Off_IndLmp_On_Rq "0h";
BA_ "GenSigTimeout_ETM" SG_ 736 ESP_Off_IndLmp_On_Rq 525;
BA_ "GenSigTimeout_IC" SG_ 736 ESP_Off_IndLmp_On_Rq 275;
BA_ "GenSigTimeout_ORC" SG_ 736 ESP_Off_IndLmp_On_Rq 175;
BA_ "RID" SG_ 736 ESP_Off_IndLmp_On_Rq "1988";
BA_ "FlexKomComment" SG_ 736 HSA_EN "ESP feature present and enabled";
BA_ "FlexKomIsMotorola" SG_ 736 HSA_EN 1;
BA_ "FlexKomSID" SG_ 736 HSA_EN 396;
BA_ "FlexKomSigLaenge" SG_ 736 HSA_EN 8;
BA_ "FlexKomSigName" SG_ 736 HSA_EN "EBC_Feature_Status";
BA_ "FlexKomSigStartPos" SG_ 736 HSA_EN 47;
BA_ "FlexKomSigStartValue" SG_ 736 HSA_EN "00h";
BA_ "GenSigCycleTime" SG_ 736 HSA_EN 50;
BA_ "GenSigSNA" SG_ 736 HSA_EN "0h";
BA_ "GenSigTimeout_IC" SG_ 736 HSA_EN 525;
BA_ "RID" SG_ 736 HSA_EN "1063";
BA_ "FlexKomComment" SG_ 736 LT_DIST "Distance traveled by wheels";
BA_ "FlexKomIsMotorola" SG_ 736 LT_DIST 1;
BA_ "FlexKomSID" SG_ 736 LT_DIST 395;
BA_ "FlexKomSigLaenge" SG_ 736 LT_DIST 32;
BA_ "FlexKomSigName" SG_ 736 LT_DIST "ESP_DIST";
BA_ "FlexKomSigStartPos" SG_ 736 LT_DIST 7;
BA_ "FlexKomSigStartValue" SG_ 736 LT_DIST "FFFFFFFFh";
BA_ "GenSigCycleTime" SG_ 736 LT_DIST 50;
BA_ "GenSigSNA" SG_ 736 LT_DIST "FFFFh";
BA_ "GenSigStartValue" SG_ 736 LT_DIST 65535;
BA_ "GenSigTimeout_CBC" SG_ 736 LT_DIST 525;
BA_ "GenSigTimeout_IC" SG_ 736 LT_DIST 525;
BA_ "GenSigTimeout_PTS" SG_ 736 LT_DIST 525;
BA_ "RID" SG_ 736 LT_DIST "1233";
BA_ "FlexKomComment" SG_ 736 RT_DIST "Distance traveled by wheels";
BA_ "FlexKomIsMotorola" SG_ 736 RT_DIST 1;
BA_ "FlexKomSID" SG_ 736 RT_DIST 395;
BA_ "FlexKomSigLaenge" SG_ 736 RT_DIST 32;
BA_ "FlexKomSigName" SG_ 736 RT_DIST "ESP_DIST";
BA_ "FlexKomSigStartPos" SG_ 736 RT_DIST 7;
BA_ "FlexKomSigStartValue" SG_ 736 RT_DIST "FFFFFFFFh";
BA_ "GenSigCycleTime" SG_ 736 RT_DIST 50;
BA_ "GenSigSNA" SG_ 736 RT_DIST "FFFFh";
BA_ "GenSigStartValue" SG_ 736 RT_DIST 65535;
BA_ "GenSigTimeout_CBC" SG_ 736 RT_DIST 525;
BA_ "GenSigTimeout_IC" SG_ 736 RT_DIST 525;
BA_ "GenSigTimeout_PTS" SG_ 736 RT_DIST 525;
BA_ "RID" SG_ 736 RT_DIST "1113";
BA_ "FlexKomComment" SG_ 736 YRS_DataRq "Request from ESC for YRS information";
BA_ "FlexKomIsMotorola" SG_ 736 YRS_DataRq 1;
BA_ "FlexKomSID" SG_ 736 YRS_DataRq 1589;
BA_ "FlexKomSigLaenge" SG_ 736 YRS_DataRq 1;
BA_ "FlexKomSigName" SG_ 736 YRS_DataRq "YRS_DataRq";
BA_ "FlexKomSigStartPos" SG_ 736 YRS_DataRq 32;
BA_ "FlexKomSigStartValue" SG_ 736 YRS_DataRq "00h";
BA_ "GenSigCycleTime" SG_ 736 YRS_DataRq 50;
BA_ "GenSigSNA" SG_ 736 YRS_DataRq "0h";
BA_ "GenSigTimeout_ORC" SG_ 736 YRS_DataRq 175;
BA_ "FlexKomComment" SG_ 840 FailSafeError "Fail safe error";
BA_ "FlexKomIsMotorola" SG_ 840 FailSafeError 1;
BA_ "FlexKomSID" SG_ 840 FailSafeError 13;
BA_ "FlexKomSigLaenge" SG_ 840 FailSafeError 16;
BA_ "FlexKomSigName" SG_ 840 FailSafeError "FailSafeError";
BA_ "FlexKomSigStartPos" SG_ 840 FailSafeError 7;
BA_ "FlexKomSigStartValue" SG_ 840 FailSafeError "0000h";
BA_ "GenSigSendType" SG_ 840 FailSafeError 1;
BA_ "GenSigSNA" SG_ 840 FailSafeError "FFFFh";
BA_ "FlexKomComment" SG_ 710 EC_ECUCfg17_Stat "ECU Configuration 17 packet";
BA_ "FlexKomIsMotorola" SG_ 710 EC_ECUCfg17_Stat 1;
BA_ "FlexKomSID" SG_ 710 EC_ECUCfg17_Stat 2478;
BA_ "FlexKomSigLaenge" SG_ 710 EC_ECUCfg17_Stat 64;
BA_ "FlexKomSigName" SG_ 710 EC_ECUCfg17_Stat "EcuCfg17Pkt";
BA_ "FlexKomSigStartPos" SG_ 710 EC_ECUCfg17_Stat 7;
BA_ "FlexKomSigStartValue" SG_ 710 EC_ECUCfg17_Stat "0300000000000000h";
BA_ "GenSigCycleTime" SG_ 710 EC_ECUCfg17_Stat 2000;
BA_ "GenSigSendType" SG_ 710 EC_ECUCfg17_Stat 5;
BA_ "GenSigSNA" SG_ 710 EC_ECUCfg17_Stat "3h";
BA_ "GenSigStartValue" SG_ 710 EC_ECUCfg17_Stat 3;
BA_ "GenSigTimeout_PTS" SG_ 710 EC_ECUCfg17_Stat 21000;
BA_ "FlexKomComment" SG_ 710 EC_PTS "ECU Configuration 17 packet";
BA_ "FlexKomIsMotorola" SG_ 710 EC_PTS 1;
BA_ "FlexKomSID" SG_ 710 EC_PTS 2478;
BA_ "FlexKomSigLaenge" SG_ 710 EC_PTS 64;
BA_ "FlexKomSigName" SG_ 710 EC_PTS "EcuCfg17Pkt";
BA_ "FlexKomSigStartPos" SG_ 710 EC_PTS 7;
BA_ "FlexKomSigStartValue" SG_ 710 EC_PTS "0300000000000000h";
BA_ "GenSigCycleTime" SG_ 710 EC_PTS 2000;
BA_ "GenSigSendType" SG_ 710 EC_PTS 5;
BA_ "GenSigSNA" SG_ 710 EC_PTS "0h";
BA_ "GenSigTimeout_PTS" SG_ 710 EC_PTS 21000;
BA_ "FlexKomComment" SG_ 1013 EC_BrakesA "Brake system ecu configuration";
BA_ "FlexKomIsMotorola" SG_ 1013 EC_BrakesA 1;
BA_ "FlexKomSID" SG_ 1013 EC_BrakesA 889;
BA_ "FlexKomSigLaenge" SG_ 1013 EC_BrakesA 16;
BA_ "FlexKomSigName" SG_ 1013 EC_BrakesA "EC_Brakes";
BA_ "FlexKomSigStartPos" SG_ 1013 EC_BrakesA 7;
BA_ "FlexKomSigStartValue" SG_ 1013 EC_BrakesA "0000h";
BA_ "GenSigCycleTime" SG_ 1013 EC_BrakesA 2000;
BA_ "GenSigSendType" SG_ 1013 EC_BrakesA 5;
BA_ "GenSigSNA" SG_ 1013 EC_BrakesA "0h";
BA_ "FlexKomComment" SG_ 1013 EC_BrakesB "Brake system ecu configuration";
BA_ "FlexKomIsMotorola" SG_ 1013 EC_BrakesB 1;
BA_ "FlexKomSID" SG_ 1013 EC_BrakesB 889;
BA_ "FlexKomSigLaenge" SG_ 1013 EC_BrakesB 16;
BA_ "FlexKomSigName" SG_ 1013 EC_BrakesB "EC_Brakes";
BA_ "FlexKomSigStartPos" SG_ 1013 EC_BrakesB 7;
BA_ "FlexKomSigStartValue" SG_ 1013 EC_BrakesB "0000h";
BA_ "GenSigCycleTime" SG_ 1013 EC_BrakesB 2000;
BA_ "GenSigSendType" SG_ 1013 EC_BrakesB 5;
BA_ "GenSigSNA" SG_ 1013 EC_BrakesB "0h";
BA_ "FlexKomComment" SG_ 1013 EC_ECUCfg6_Stat "ECU Configuration messages status 6";
BA_ "FlexKomIsMotorola" SG_ 1013 EC_ECUCfg6_Stat 1;
BA_ "FlexKomSID" SG_ 1013 EC_ECUCfg6_Stat 1063;
BA_ "FlexKomSigLaenge" SG_ 1013 EC_ECUCfg6_Stat 2;
BA_ "FlexKomSigName" SG_ 1013 EC_ECUCfg6_Stat "EC_ECUCfg6_Stat";
BA_ "FlexKomSigStartPos" SG_ 1013 EC_ECUCfg6_Stat 1;
BA_ "FlexKomSigStartValue" SG_ 1013 EC_ECUCfg6_Stat "03h";
BA_ "GenSigCycleTime" SG_ 1013 EC_ECUCfg6_Stat 2000;
BA_ "GenSigSendType" SG_ 1013 EC_ECUCfg6_Stat 5;
BA_ "GenSigSNA" SG_ 1013 EC_ECUCfg6_Stat "3h";
BA_ "GenSigStartValue" SG_ 1013 EC_ECUCfg6_Stat 3;
BA_ "GenSigTimeout_EPS" SG_ 1013 EC_ECUCfg6_Stat 21000;
BA_ "GenSigTimeout_ORC" SG_ 1013 EC_ECUCfg6_Stat 7000;
BA_ "RID" SG_ 1013 EC_ECUCfg6_Stat "9994";
BA_ "FlexKomComment" SG_ 1013 EC_Powertrain "Powertrain ecu configuration";
BA_ "FlexKomIsMotorola" SG_ 1013 EC_Powertrain 1;
BA_ "FlexKomSID" SG_ 1013 EC_Powertrain 890;
BA_ "FlexKomSigLaenge" SG_ 1013 EC_Powertrain 16;
BA_ "FlexKomSigName" SG_ 1013 EC_Powertrain "EC_Powertrain";
BA_ "FlexKomSigStartPos" SG_ 1013 EC_Powertrain 39;
BA_ "FlexKomSigStartValue" SG_ 1013 EC_Powertrain "0000h";
BA_ "GenSigCycleTime" SG_ 1013 EC_Powertrain 2000;
BA_ "GenSigSendType" SG_ 1013 EC_Powertrain 5;
BA_ "GenSigSNA" SG_ 1013 EC_Powertrain "0h";
BA_ "FlexKomComment" SG_ 1013 EC_Safety "Safety ecu configuration";
BA_ "FlexKomIsMotorola" SG_ 1013 EC_Safety 1;
BA_ "FlexKomSID" SG_ 1013 EC_Safety 892;
BA_ "FlexKomSigLaenge" SG_ 1013 EC_Safety 16;
BA_ "FlexKomSigName" SG_ 1013 EC_Safety "EC_Safety";
BA_ "FlexKomSigStartPos" SG_ 1013 EC_Safety 55;
BA_ "FlexKomSigStartValue" SG_ 1013 EC_Safety "0000h";
BA_ "GenSigCycleTime" SG_ 1013 EC_Safety 2000;
BA_ "GenSigSendType" SG_ 1013 EC_Safety 5;
BA_ "GenSigSNA" SG_ 1013 EC_Safety "0h";
BA_ "GenSigTimeout_ORC" SG_ 1013 EC_Safety 7000;
BA_ "FlexKomComment" SG_ 1013 EC_Steering "Steering ecu configuration";
BA_ "FlexKomIsMotorola" SG_ 1013 EC_Steering 1;
BA_ "FlexKomSID" SG_ 1013 EC_Steering 1982;
BA_ "FlexKomSigLaenge" SG_ 1013 EC_Steering 16;
BA_ "FlexKomSigName" SG_ 1013 EC_Steering "EC_Steering";
BA_ "FlexKomSigStartPos" SG_ 1013 EC_Steering 23;
BA_ "FlexKomSigStartValue" SG_ 1013 EC_Steering "0000h";
BA_ "GenSigCycleTime" SG_ 1013 EC_Steering 2000;
BA_ "GenSigSendType" SG_ 1013 EC_Steering 5;
BA_ "GenSigSNA" SG_ 1013 EC_Steering "0h";
BA_ "GenSigTimeout_EPS" SG_ 1013 EC_Steering 21000;
BA_ "GenSigTimeout_ORC" SG_ 1013 EC_Steering 7000;
BA_ "RID" SG_ 1013 EC_Steering "9770";
BA_ "FlexKomComment" SG_ 1015 EC_CBC7A "CBC ecu configuration 7";
BA_ "FlexKomIsMotorola" SG_ 1015 EC_CBC7A 1;
BA_ "FlexKomSID" SG_ 1015 EC_CBC7A 1106;
BA_ "FlexKomSigLaenge" SG_ 1015 EC_CBC7A 32;
BA_ "FlexKomSigName" SG_ 1015 EC_CBC7A "EC_CBC7";
BA_ "FlexKomSigStartPos" SG_ 1015 EC_CBC7A 7;
BA_ "FlexKomSigStartValue" SG_ 1015 EC_CBC7A "00000000h";
BA_ "GenSigCycleTime" SG_ 1015 EC_CBC7A 2000;
BA_ "GenSigSNA" SG_ 1015 EC_CBC7A "0h";
BA_ "FlexKomComment" SG_ 1015 EC_CBC7B "CBC ecu configuration 7";
BA_ "FlexKomIsMotorola" SG_ 1015 EC_CBC7B 1;
BA_ "FlexKomSID" SG_ 1015 EC_CBC7B 1106;
BA_ "FlexKomSigLaenge" SG_ 1015 EC_CBC7B 32;
BA_ "FlexKomSigName" SG_ 1015 EC_CBC7B "EC_CBC7";
BA_ "FlexKomSigStartPos" SG_ 1015 EC_CBC7B 7;
BA_ "FlexKomSigStartValue" SG_ 1015 EC_CBC7B "00000000h";
BA_ "GenSigCycleTime" SG_ 1015 EC_CBC7B 2000;
BA_ "GenSigSNA" SG_ 1015 EC_CBC7B "0h";
BA_ "FlexKomComment" SG_ 1015 EC_CBC8 "CBC ecu configuration 8";
BA_ "FlexKomIsMotorola" SG_ 1015 EC_CBC8 1;
BA_ "FlexKomSID" SG_ 1015 EC_CBC8 1104;
BA_ "FlexKomSigLaenge" SG_ 1015 EC_CBC8 32;
BA_ "FlexKomSigName" SG_ 1015 EC_CBC8 "EC_CBC8";
BA_ "FlexKomSigStartPos" SG_ 1015 EC_CBC8 39;
BA_ "FlexKomSigStartValue" SG_ 1015 EC_CBC8 "00000000h";
BA_ "GenSigCycleTime" SG_ 1015 EC_CBC8 2000;
BA_ "GenSigSNA" SG_ 1015 EC_CBC8 "0h";
BA_ "FlexKomComment" SG_ 1015 EC_ECUCfg8_Stat "ECU Configuration messages status 8";
BA_ "FlexKomIsMotorola" SG_ 1015 EC_ECUCfg8_Stat 1;
BA_ "FlexKomSID" SG_ 1015 EC_ECUCfg8_Stat 1101;
BA_ "FlexKomSigLaenge" SG_ 1015 EC_ECUCfg8_Stat 2;
BA_ "FlexKomSigName" SG_ 1015 EC_ECUCfg8_Stat "EC_ECUCfg8_Stat";
BA_ "FlexKomSigStartPos" SG_ 1015 EC_ECUCfg8_Stat 1;
BA_ "FlexKomSigStartValue" SG_ 1015 EC_ECUCfg8_Stat "03h";
BA_ "GenSigCycleTime" SG_ 1015 EC_ECUCfg8_Stat 2000;
BA_ "GenSigSNA" SG_ 1015 EC_ECUCfg8_Stat "3h";
BA_ "GenSigStartValue" SG_ 1015 EC_ECUCfg8_Stat 3;
BA_ "FlexKomComment" SG_ 816 AHB_ENBL "Auto highbeam enable";
BA_ "FlexKomIsMotorola" SG_ 816 AHB_ENBL 1;
BA_ "FlexKomSID" SG_ 816 AHB_ENBL 733;
BA_ "FlexKomSigLaenge" SG_ 816 AHB_ENBL 1;
BA_ "FlexKomSigName" SG_ 816 AHB_ENBL "AHB_ENBL";
BA_ "FlexKomSigStartPos" SG_ 816 AHB_ENBL 36;
BA_ "FlexKomSigStartValue" SG_ 816 AHB_ENBL "00h";
BA_ "GenSigCycleTime" SG_ 816 AHB_ENBL 1000;
BA_ "GenSigSendType" SG_ 816 AHB_ENBL 5;
BA_ "GenSigSNA" SG_ 816 AHB_ENBL "0h";
BA_ "GenSigTimeout_IC" SG_ 816 AHB_ENBL 10500;
BA_ "FlexKomComment" SG_ 816 ChargeReq "Request for scheduled charge; Charge now = [1]";
BA_ "FlexKomIsMotorola" SG_ 816 ChargeReq 1;
BA_ "FlexKomSID" SG_ 816 ChargeReq 2418;
BA_ "FlexKomSigLaenge" SG_ 816 ChargeReq 1;
BA_ "FlexKomSigName" SG_ 816 ChargeReq "ChargeReq";
BA_ "FlexKomSigStartPos" SG_ 816 ChargeReq 55;
BA_ "FlexKomSigStartValue" SG_ 816 ChargeReq "01h";
BA_ "GenSigCycleTime" SG_ 816 ChargeReq 1000;
BA_ "GenSigSendType" SG_ 816 ChargeReq 5;
BA_ "GenSigSNA" SG_ 816 ChargeReq "1h";
BA_ "GenSigStartValue" SG_ 816 ChargeReq 1;
BA_ "RID" SG_ 816 ChargeReq "2187 4465";
BA_ "FlexKomComment" SG_ 816 HVAC_CLNT_FLW_MIN "HVAC coolant flow minimum request";
BA_ "FlexKomIsMotorola" SG_ 816 HVAC_CLNT_FLW_MIN 1;
BA_ "FlexKomSID" SG_ 816 HVAC_CLNT_FLW_MIN 1527;
BA_ "FlexKomSigLaenge" SG_ 816 HVAC_CLNT_FLW_MIN 8;
BA_ "FlexKomSigName" SG_ 816 HVAC_CLNT_FLW_MIN "HVAC_CLNT_FLW_MIN";
BA_ "FlexKomSigStartPos" SG_ 816 HVAC_CLNT_FLW_MIN 47;
BA_ "FlexKomSigStartValue" SG_ 816 HVAC_CLNT_FLW_MIN "FFh";
BA_ "GenSigCycleTime" SG_ 816 HVAC_CLNT_FLW_MIN 1000;
BA_ "GenSigSendType" SG_ 816 HVAC_CLNT_FLW_MIN 5;
BA_ "GenSigSNA" SG_ 816 HVAC_CLNT_FLW_MIN "FFh";
BA_ "GenSigStartValue" SG_ 816 HVAC_CLNT_FLW_MIN 255;
BA_ "RID" SG_ 816 HVAC_CLNT_FLW_MIN "2885";
BA_ "FlexKomComment" SG_ 816 ICS_btn_16 "PPA pressed";
BA_ "FlexKomIsMotorola" SG_ 816 ICS_btn_16 1;
BA_ "FlexKomSID" SG_ 816 ICS_btn_16 1839;
BA_ "FlexKomSigLaenge" SG_ 816 ICS_btn_16 1;
BA_ "FlexKomSigName" SG_ 816 ICS_btn_16 "ICS_btn_16";
BA_ "FlexKomSigStartPos" SG_ 816 ICS_btn_16 51;
BA_ "FlexKomSigStartValue" SG_ 816 ICS_btn_16 "00h";
BA_ "GenSigCycleTime" SG_ 816 ICS_btn_16 1000;
BA_ "GenSigSendType" SG_ 816 ICS_btn_16 5;
BA_ "GenSigSNA" SG_ 816 ICS_btn_16 "0h";
BA_ "RID" SG_ 816 ICS_btn_16 "2085";
BA_ "FlexKomComment" SG_ 816 ICS_btn_17 "PTS Off pressed";
BA_ "FlexKomIsMotorola" SG_ 816 ICS_btn_17 1;
BA_ "FlexKomSID" SG_ 816 ICS_btn_17 1840;
BA_ "FlexKomSigLaenge" SG_ 816 ICS_btn_17 1;
BA_ "FlexKomSigName" SG_ 816 ICS_btn_17 "ICS_btn_17";
BA_ "FlexKomSigStartPos" SG_ 816 ICS_btn_17 52;
BA_ "FlexKomSigStartValue" SG_ 816 ICS_btn_17 "00h";
BA_ "GenSigCycleTime" SG_ 816 ICS_btn_17 1000;
BA_ "GenSigSendType" SG_ 816 ICS_btn_17 5;
BA_ "GenSigSNA" SG_ 816 ICS_btn_17 "0h";
BA_ "RID" SG_ 816 ICS_btn_17 "2096";
BA_ "FlexKomComment" SG_ 816 ICS_btn_18 "LDW Off pressed";
BA_ "FlexKomIsMotorola" SG_ 816 ICS_btn_18 1;
BA_ "FlexKomSID" SG_ 816 ICS_btn_18 1841;
BA_ "FlexKomSigLaenge" SG_ 816 ICS_btn_18 1;
BA_ "FlexKomSigName" SG_ 816 ICS_btn_18 "ICS_btn_18";
BA_ "FlexKomSigStartPos" SG_ 816 ICS_btn_18 53;
BA_ "FlexKomSigStartValue" SG_ 816 ICS_btn_18 "00h";
BA_ "GenSigCycleTime" SG_ 816 ICS_btn_18 1000;
BA_ "GenSigSendType" SG_ 816 ICS_btn_18 5;
BA_ "GenSigSNA" SG_ 816 ICS_btn_18 "0h";
BA_ "RID" SG_ 816 ICS_btn_18 "2090";
BA_ "FlexKomComment" SG_ 816 PLG_Stat "Power liftgate status";
BA_ "FlexKomIsMotorola" SG_ 816 PLG_Stat 1;
BA_ "FlexKomSID" SG_ 816 PLG_Stat 16;
BA_ "FlexKomSigLaenge" SG_ 816 PLG_Stat 4;
BA_ "FlexKomSigName" SG_ 816 PLG_Stat "PLG_Stat";
BA_ "FlexKomSigStartPos" SG_ 816 PLG_Stat 3;
BA_ "FlexKomSigStartValue" SG_ 816 PLG_Stat "00h";
BA_ "GenSigCycleTime" SG_ 816 PLG_Stat 1000;
BA_ "GenSigSendType" SG_ 816 PLG_Stat 5;
BA_ "GenSigSNA" SG_ 816 PLG_Stat "0h";
BA_ "GenSigTimeout_IC" SG_ 816 PLG_Stat 10500;
BA_ "RID" SG_ 816 PLG_Stat "1128";
BA_ "FlexKomComment" SG_ 816 TRAC_PSD "Traction on/off button pressed; [0] = Not Pressed,";
BA_ "FlexKomIsMotorola" SG_ 816 TRAC_PSD 1;
BA_ "FlexKomSID" SG_ 816 TRAC_PSD 424;
BA_ "FlexKomSigLaenge" SG_ 816 TRAC_PSD 1;
BA_ "FlexKomSigName" SG_ 816 TRAC_PSD "TRAC_PSD";
BA_ "FlexKomSigStartPos" SG_ 816 TRAC_PSD 19;
BA_ "FlexKomSigStartValue" SG_ 816 TRAC_PSD "00h";
BA_ "GenSigCycleTime" SG_ 816 TRAC_PSD 1000;
BA_ "GenSigSendType" SG_ 816 TRAC_PSD 5;
BA_ "GenSigSNA" SG_ 816 TRAC_PSD "0h";
BA_ "RID" SG_ 816 TRAC_PSD "1155";
BA_ "FlexKomComment" SG_ 816 phone_pop_up_active "Phone pop up is active; True = [1]";
BA_ "FlexKomIsMotorola" SG_ 816 phone_pop_up_active 1;
BA_ "FlexKomSID" SG_ 816 phone_pop_up_active 2527;
BA_ "FlexKomSigLaenge" SG_ 816 phone_pop_up_active 1;
BA_ "FlexKomSigName" SG_ 816 phone_pop_up_active "phone_pop_up_active";
BA_ "FlexKomSigStartPos" SG_ 816 phone_pop_up_active 30;
BA_ "FlexKomSigStartValue" SG_ 816 phone_pop_up_active "00h";
BA_ "GenSigCycleTime" SG_ 816 phone_pop_up_active 1000;
BA_ "GenSigSendType" SG_ 816 phone_pop_up_active 5;
BA_ "GenSigSNA" SG_ 816 phone_pop_up_active "0h";
BA_ "GenSigTimeout_IC" SG_ 816 phone_pop_up_active 10500;
BA_ "RID" SG_ 816 phone_pop_up_active "3052";
BA_ "FlexKomComment" SG_ 678 DispPopupSts "LDW message status in cluster";
BA_ "FlexKomIsMotorola" SG_ 678 DispPopupSts 1;
BA_ "FlexKomSID" SG_ 678 DispPopupSts 2019;
BA_ "FlexKomSigLaenge" SG_ 678 DispPopupSts 8;
BA_ "FlexKomSigName" SG_ 678 DispPopupSts "DispPopupSts";
BA_ "FlexKomSigStartPos" SG_ 678 DispPopupSts 31;
BA_ "FlexKomSigStartValue" SG_ 678 DispPopupSts "00h";
BA_ "GenSigCycleTime" SG_ 678 DispPopupSts 250;
BA_ "GenSigSNA" SG_ 678 DispPopupSts "FFh";
BA_ "GenSigTimeout_IC" SG_ 678 DispPopupSts 2625;
BA_ "FlexKomComment" SG_ 678 DisplaySts "LDW display status in cluster";
BA_ "FlexKomIsMotorola" SG_ 678 DisplaySts 1;
BA_ "FlexKomSID" SG_ 678 DisplaySts 2018;
BA_ "FlexKomSigLaenge" SG_ 678 DisplaySts 8;
BA_ "FlexKomSigName" SG_ 678 DisplaySts "DisplaySts";
BA_ "FlexKomSigStartPos" SG_ 678 DisplaySts 23;
BA_ "FlexKomSigStartValue" SG_ 678 DisplaySts "00h";
BA_ "GenSigCycleTime" SG_ 678 DisplaySts 250;
BA_ "GenSigSNA" SG_ 678 DisplaySts "FFh";
BA_ "GenSigTimeout_IC" SG_ 678 DisplaySts 2625;
BA_ "GenSigTimeout_ORC" SG_ 678 DisplaySts 875;
BA_ "FlexKomComment" SG_ 678 HALF_CHIME_REP_RATESts "LDW chime repetition rate; Continuous = [0]";
BA_ "FlexKomIsMotorola" SG_ 678 HALF_CHIME_REP_RATESts 1;
BA_ "FlexKomSID" SG_ 678 HALF_CHIME_REP_RATESts 2021;
BA_ "FlexKomSigLaenge" SG_ 678 HALF_CHIME_REP_RATESts 4;
BA_ "FlexKomSigName" SG_ 678 HALF_CHIME_REP_RATESts "HALF_CHIME_REP_RATESts";
BA_ "FlexKomSigStartPos" SG_ 678 HALF_CHIME_REP_RATESts 39;
BA_ "FlexKomSigStartValue" SG_ 678 HALF_CHIME_REP_RATESts "00h";
BA_ "GenSigCycleTime" SG_ 678 HALF_CHIME_REP_RATESts 250;
BA_ "GenSigSNA" SG_ 678 HALF_CHIME_REP_RATESts "0h";
BA_ "GenSigTimeout_CBC" SG_ 678 HALF_CHIME_REP_RATESts 2625;
BA_ "RID" SG_ 678 HALF_CHIME_REP_RATESts "2038";
BA_ "FlexKomComment" SG_ 678 HALF_CHIME_TYPESts "LDW chime type";
BA_ "FlexKomIsMotorola" SG_ 678 HALF_CHIME_TYPESts 1;
BA_ "FlexKomSID" SG_ 678 HALF_CHIME_TYPESts 2020;
BA_ "FlexKomSigLaenge" SG_ 678 HALF_CHIME_TYPESts 4;
BA_ "FlexKomSigName" SG_ 678 HALF_CHIME_TYPESts "HALF_CHIME_TYPESts";
BA_ "FlexKomSigStartPos" SG_ 678 HALF_CHIME_TYPESts 35;
BA_ "FlexKomSigStartValue" SG_ 678 HALF_CHIME_TYPESts "00h";
BA_ "GenSigCycleTime" SG_ 678 HALF_CHIME_TYPESts 250;
BA_ "GenSigSNA" SG_ 678 HALF_CHIME_TYPESts "Fh";
BA_ "GenSigTimeout_CBC" SG_ 678 HALF_CHIME_TYPESts 2625;
BA_ "RID" SG_ 678 HALF_CHIME_TYPESts "2017";
BA_ "FlexKomComment" SG_ 678 HALF_LF_CHIME_RQSts "LDW chime request for left side; true = [1]";
BA_ "FlexKomIsMotorola" SG_ 678 HALF_LF_CHIME_RQSts 1;
BA_ "FlexKomSID" SG_ 678 HALF_LF_CHIME_RQSts 2023;
BA_ "FlexKomSigLaenge" SG_ 678 HALF_LF_CHIME_RQSts 1;
BA_ "FlexKomSigName" SG_ 678 HALF_LF_CHIME_RQSts "HALF_LF_CHIME_RQSts";
BA_ "FlexKomSigStartPos" SG_ 678 HALF_LF_CHIME_RQSts 40;
BA_ "FlexKomSigStartValue" SG_ 678 HALF_LF_CHIME_RQSts "00h";
BA_ "GenSigCycleTime" SG_ 678 HALF_LF_CHIME_RQSts 250;
BA_ "GenSigSNA" SG_ 678 HALF_LF_CHIME_RQSts "0h";
BA_ "RID" SG_ 678 HALF_LF_CHIME_RQSts "2041";
BA_ "FlexKomComment" SG_ 678 HALF_RF_CHIME_RQSts "LDW chime request for right side; true = [1]";
BA_ "FlexKomIsMotorola" SG_ 678 HALF_RF_CHIME_RQSts 1;
BA_ "FlexKomSID" SG_ 678 HALF_RF_CHIME_RQSts 2022;
BA_ "FlexKomSigLaenge" SG_ 678 HALF_RF_CHIME_RQSts 1;
BA_ "FlexKomSigName" SG_ 678 HALF_RF_CHIME_RQSts "HALF_RF_CHIME_RQSts";
BA_ "FlexKomSigStartPos" SG_ 678 HALF_RF_CHIME_RQSts 41;
BA_ "FlexKomSigStartValue" SG_ 678 HALF_RF_CHIME_RQSts "00h";
BA_ "GenSigCycleTime" SG_ 678 HALF_RF_CHIME_RQSts 250;
BA_ "GenSigSNA" SG_ 678 HALF_RF_CHIME_RQSts "0h";
BA_ "RID" SG_ 678 HALF_RF_CHIME_RQSts "2020";
BA_ "FlexKomComment" SG_ 678 ISO_TelltaleSts "LDW telltale status in cluster";
BA_ "FlexKomIsMotorola" SG_ 678 ISO_TelltaleSts 1;
BA_ "FlexKomSID" SG_ 678 ISO_TelltaleSts 2015;
BA_ "FlexKomSigLaenge" SG_ 678 ISO_TelltaleSts 3;
BA_ "FlexKomSigName" SG_ 678 ISO_TelltaleSts "ISO_TelltaleSts";
BA_ "FlexKomSigStartPos" SG_ 678 ISO_TelltaleSts 2;
BA_ "FlexKomSigStartValue" SG_ 678 ISO_TelltaleSts "00h";
BA_ "GenSigCycleTime" SG_ 678 ISO_TelltaleSts 250;
BA_ "GenSigSNA" SG_ 678 ISO_TelltaleSts "7h";
BA_ "GenSigTimeout_IC" SG_ 678 ISO_TelltaleSts 2625;
BA_ "FlexKomComment" SG_ 678 SensitivitySts "LDW sensitivity level for display in cluster";
BA_ "FlexKomIsMotorola" SG_ 678 SensitivitySts 1;
BA_ "FlexKomSID" SG_ 678 SensitivitySts 2017;
BA_ "FlexKomSigLaenge" SG_ 678 SensitivitySts 3;
BA_ "FlexKomSigName" SG_ 678 SensitivitySts "SensitivitySts";
BA_ "FlexKomSigStartPos" SG_ 678 SensitivitySts 15;
BA_ "FlexKomSigStartValue" SG_ 678 SensitivitySts "00h";
BA_ "GenSigCycleTime" SG_ 678 SensitivitySts 250;
BA_ "GenSigSNA" SG_ 678 SensitivitySts "7h";
BA_ "GenSigTimeout_IC" SG_ 678 SensitivitySts 2625;
BA_ "FlexKomComment" SG_ 678 TrqIntensitySts "LDW torque intesity level for display in cluster";
BA_ "FlexKomIsMotorola" SG_ 678 TrqIntensitySts 1;
BA_ "FlexKomSID" SG_ 678 TrqIntensitySts 2016;
BA_ "FlexKomSigLaenge" SG_ 678 TrqIntensitySts 3;
BA_ "FlexKomSigName" SG_ 678 TrqIntensitySts "TrqIntensitySts";
BA_ "FlexKomSigStartPos" SG_ 678 TrqIntensitySts 12;
BA_ "FlexKomSigStartValue" SG_ 678 TrqIntensitySts "00h";
BA_ "GenSigCycleTime" SG_ 678 TrqIntensitySts 250;
BA_ "GenSigSNA" SG_ 678 TrqIntensitySts "7h";
BA_ "GenSigTimeout_IC" SG_ 678 TrqIntensitySts 2625;
BA_ "FlexKomComment" SG_ 658 CRC_292h "Half steering control packet";
BA_ "FlexKomIsMotorola" SG_ 658 CRC_292h 1;
BA_ "FlexKomSID" SG_ 658 CRC_292h 1908;
BA_ "FlexKomSigLaenge" SG_ 658 CRC_292h 48;
BA_ "FlexKomSigName" SG_ 658 CRC_292h "HaLF_StrCtrl";
BA_ "FlexKomSigStartPos" SG_ 658 CRC_292h 7;
BA_ "FlexKomSigStartValue" SG_ 658 CRC_292h "0000000000FFh";
BA_ "GenSigCycleTime" SG_ 658 CRC_292h 10;
BA_ "GenSigSNA" SG_ 658 CRC_292h "FFh";
BA_ "GenSigStartValue" SG_ 658 CRC_292h 255;
BA_ "FlexKomComment" SG_ 658 MC_292h "Half steering control packet";
BA_ "FlexKomIsMotorola" SG_ 658 MC_292h 1;
BA_ "FlexKomSID" SG_ 658 MC_292h 1908;
BA_ "FlexKomSigLaenge" SG_ 658 MC_292h 48;
BA_ "FlexKomSigName" SG_ 658 MC_292h "HaLF_StrCtrl";
BA_ "FlexKomSigStartPos" SG_ 658 MC_292h 7;
BA_ "FlexKomSigStartValue" SG_ 658 MC_292h "0000000000FFh";
BA_ "GenSigCycleTime" SG_ 658 MC_292h 10;
BA_ "GenSigSNA" SG_ 658 MC_292h "0h";
BA_ "FlexKomComment" SG_ 658 MTO_HALFDriveStyleSts "Half steering control packet";
BA_ "FlexKomIsMotorola" SG_ 658 MTO_HALFDriveStyleSts 1;
BA_ "FlexKomSID" SG_ 658 MTO_HALFDriveStyleSts 1908;
BA_ "FlexKomSigLaenge" SG_ 658 MTO_HALFDriveStyleSts 48;
BA_ "FlexKomSigName" SG_ 658 MTO_HALFDriveStyleSts "HaLF_StrCtrl";
BA_ "FlexKomSigStartPos" SG_ 658 MTO_HALFDriveStyleSts 7;
BA_ "FlexKomSigStartValue" SG_ 658 MTO_HALFDriveStyleSts "0000000000FFh";
BA_ "GenSigCycleTime" SG_ 658 MTO_HALFDriveStyleSts 10;
BA_ "GenSigSNA" SG_ 658 MTO_HALFDriveStyleSts "7h";
BA_ "FlexKomComment" SG_ 658 MTO_HALFSystemSts "Half steering control packet";
BA_ "FlexKomIsMotorola" SG_ 658 MTO_HALFSystemSts 1;
BA_ "FlexKomSID" SG_ 658 MTO_HALFSystemSts 1908;
BA_ "FlexKomSigLaenge" SG_ 658 MTO_HALFSystemSts 48;
BA_ "FlexKomSigName" SG_ 658 MTO_HALFSystemSts "HaLF_StrCtrl";
BA_ "FlexKomSigStartPos" SG_ 658 MTO_HALFSystemSts 7;
BA_ "FlexKomSigStartValue" SG_ 658 MTO_HALFSystemSts "0000000000FFh";
BA_ "GenSigCycleTime" SG_ 658 MTO_HALFSystemSts 10;
BA_ "GenSigSNA" SG_ 658 MTO_HALFSystemSts "0h";
BA_ "FlexKomComment" SG_ 658 MotorTorqueOverlayIntActivation "Half steering control packet";
BA_ "FlexKomIsMotorola" SG_ 658 MotorTorqueOverlayIntActivation 1;
BA_ "FlexKomSID" SG_ 658 MotorTorqueOverlayIntActivation 1908;
BA_ "FlexKomSigLaenge" SG_ 658 MotorTorqueOverlayIntActivation 48;
BA_ "FlexKomSigName" SG_ 658 MotorTorqueOverlayIntActivation "HaLF_StrCtrl";
BA_ "FlexKomSigStartPos" SG_ 658 MotorTorqueOverlayIntActivation 7;
BA_ "FlexKomSigStartValue" SG_ 658 MotorTorqueOverlayIntActivation "0000000000FFh";
BA_ "GenSigCycleTime" SG_ 658 MotorTorqueOverlayIntActivation 10;
BA_ "GenSigSNA" SG_ 658 MotorTorqueOverlayIntActivation "0h";
BA_ "FlexKomComment" SG_ 658 MotorTorqueOverlaySteeringReq "Half steering control packet";
BA_ "FlexKomIsMotorola" SG_ 658 MotorTorqueOverlaySteeringReq 1;
BA_ "FlexKomSID" SG_ 658 MotorTorqueOverlaySteeringReq 1908;
BA_ "FlexKomSigLaenge" SG_ 658 MotorTorqueOverlaySteeringReq 48;
BA_ "FlexKomSigName" SG_ 658 MotorTorqueOverlaySteeringReq "HaLF_StrCtrl";
BA_ "FlexKomSigStartPos" SG_ 658 MotorTorqueOverlaySteeringReq 7;
BA_ "FlexKomSigStartValue" SG_ 658 MotorTorqueOverlaySteeringReq "0000000000FFh";
BA_ "GenSigCycleTime" SG_ 658 MotorTorqueOverlaySteeringReq 10;
BA_ "GenSigSNA" SG_ 658 MotorTorqueOverlaySteeringReq "0h";
BA_ "FlexKomComment" SG_ 729 ConfigSts "Configuration status";
BA_ "FlexKomIsMotorola" SG_ 729 ConfigSts 1;
BA_ "FlexKomSID" SG_ 729 ConfigSts 1638;
BA_ "FlexKomSigLaenge" SG_ 729 ConfigSts 3;
BA_ "FlexKomSigName" SG_ 729 ConfigSts "ConfigSts";
BA_ "FlexKomSigStartPos" SG_ 729 ConfigSts 38;
BA_ "FlexKomSigStartValue" SG_ 729 ConfigSts "02h";
BA_ "GenSigCycleTime" SG_ 729 ConfigSts 100;
BA_ "GenSigSendType" SG_ 729 ConfigSts 5;
BA_ "GenSigSNA" SG_ 729 ConfigSts "7h";
BA_ "GenSigStartValue" SG_ 729 ConfigSts 2;
BA_ "RID" SG_ 729 ConfigSts "1622";
BA_ "FlexKomComment" SG_ 729 HALF_AHB_On "Auto high beam on request from the HALF ECU";
BA_ "FlexKomIsMotorola" SG_ 729 HALF_AHB_On 1;
BA_ "FlexKomSID" SG_ 729 HALF_AHB_On 1877;
BA_ "FlexKomSigLaenge" SG_ 729 HALF_AHB_On 1;
BA_ "FlexKomSigName" SG_ 729 HALF_AHB_On "HALF_AHB_On";
BA_ "FlexKomSigStartPos" SG_ 729 HALF_AHB_On 31;
BA_ "FlexKomSigStartValue" SG_ 729 HALF_AHB_On "00h";
BA_ "GenSigCycleTime" SG_ 729 HALF_AHB_On 100;
BA_ "GenSigSendType" SG_ 729 HALF_AHB_On 5;
BA_ "GenSigSNA" SG_ 729 HALF_AHB_On "0h";
BA_ "FlexKomComment" SG_ 729 LDW_LEDControlSts "LDW switch LED status";
BA_ "FlexKomIsMotorola" SG_ 729 LDW_LEDControlSts 1;
BA_ "FlexKomSID" SG_ 729 LDW_LEDControlSts 2024;
BA_ "FlexKomSigLaenge" SG_ 729 LDW_LEDControlSts 2;
BA_ "FlexKomSigName" SG_ 729 LDW_LEDControlSts "LDW_LEDControlSts";
BA_ "FlexKomSigStartPos" SG_ 729 LDW_LEDControlSts 25;
BA_ "FlexKomSigStartValue" SG_ 729 LDW_LEDControlSts "00h";
BA_ "GenSigCycleTime" SG_ 729 LDW_LEDControlSts 100;
BA_ "GenSigSendType" SG_ 729 LDW_LEDControlSts 5;
BA_ "GenSigSNA" SG_ 729 LDW_LEDControlSts "3h";
BA_ "GenSigTimeout_CBC" SG_ 729 LDW_LEDControlSts 1050;
BA_ "RID" SG_ 729 LDW_LEDControlSts "2019";
BA_ "FlexKomComment" SG_ 729 TorqueIntensitySts "LDW Torque Intesity Level";
BA_ "FlexKomIsMotorola" SG_ 729 TorqueIntensitySts 1;
BA_ "FlexKomSID" SG_ 729 TorqueIntensitySts 2025;
BA_ "FlexKomSigLaenge" SG_ 729 TorqueIntensitySts 3;
BA_ "FlexKomSigName" SG_ 729 TorqueIntensitySts "TorqueIntensitySts";
BA_ "FlexKomSigStartPos" SG_ 729 TorqueIntensitySts 28;
BA_ "FlexKomSigStartValue" SG_ 729 TorqueIntensitySts "00h";
BA_ "GenSigCycleTime" SG_ 729 TorqueIntensitySts 100;
BA_ "GenSigSendType" SG_ 729 TorqueIntensitySts 5;
BA_ "GenSigSNA" SG_ 729 TorqueIntensitySts "7h";
BA_ "GenSigTimeout_CBC" SG_ 729 TorqueIntensitySts 1050;
BA_ "RID" SG_ 729 TorqueIntensitySts "2037";
BA_ "FlexKomComment" SG_ 701 BatPwrUsage "HCP message 1 packet";
BA_ "FlexKomIsMotorola" SG_ 701 BatPwrUsage 1;
BA_ "FlexKomSID" SG_ 701 BatPwrUsage 2198;
BA_ "FlexKomSigLaenge" SG_ 701 BatPwrUsage 64;
BA_ "FlexKomSigName" SG_ 701 BatPwrUsage "HCP_1";
BA_ "FlexKomSigStartPos" SG_ 701 BatPwrUsage 7;
BA_ "FlexKomSigStartValue" SG_ 701 BatPwrUsage "7BFF0B0000FF01FFh";
BA_ "GenSigCycleTime" SG_ 701 BatPwrUsage 100;
BA_ "GenSigSNA" SG_ 701 BatPwrUsage "0h";
BA_ "GenSigTimeout_IC" SG_ 701 BatPwrUsage 1050;
BA_ "FlexKomComment" SG_ 701 BatPwrUsage_V "HCP message 1 packet";
BA_ "FlexKomIsMotorola" SG_ 701 BatPwrUsage_V 1;
BA_ "FlexKomSID" SG_ 701 BatPwrUsage_V 2198;
BA_ "FlexKomSigLaenge" SG_ 701 BatPwrUsage_V 64;
BA_ "FlexKomSigName" SG_ 701 BatPwrUsage_V "HCP_1";
BA_ "FlexKomSigStartPos" SG_ 701 BatPwrUsage_V 7;
BA_ "FlexKomSigStartValue" SG_ 701 BatPwrUsage_V "7BFF0B0000FF01FFh";
BA_ "GenSigCycleTime" SG_ 701 BatPwrUsage_V 100;
BA_ "GenSigSNA" SG_ 701 BatPwrUsage_V "0h";
BA_ "GenSigTimeout_IC" SG_ 701 BatPwrUsage_V 1050;
BA_ "FlexKomComment" SG_ 701 Est_Range "HCP message 1 packet";
BA_ "FlexKomIsMotorola" SG_ 701 Est_Range 1;
BA_ "FlexKomSID" SG_ 701 Est_Range 2198;
BA_ "FlexKomSigLaenge" SG_ 701 Est_Range 64;
BA_ "FlexKomSigName" SG_ 701 Est_Range "HCP_1";
BA_ "FlexKomSigStartPos" SG_ 701 Est_Range 7;
BA_ "FlexKomSigStartValue" SG_ 701 Est_Range "7BFF0B0000FF01FFh";
BA_ "GenSigCycleTime" SG_ 701 Est_Range 100;
BA_ "GenSigSNA" SG_ 701 Est_Range "FFh";
BA_ "GenSigStartValue" SG_ 701 Est_Range 255;
BA_ "GenSigTimeout_IC" SG_ 701 Est_Range 1050;
BA_ "FlexKomComment" SG_ 701 HEV_EVT_MD "HCP message 1 packet";
BA_ "FlexKomIsMotorola" SG_ 701 HEV_EVT_MD 1;
BA_ "FlexKomSID" SG_ 701 HEV_EVT_MD 2198;
BA_ "FlexKomSigLaenge" SG_ 701 HEV_EVT_MD 64;
BA_ "FlexKomSigName" SG_ 701 HEV_EVT_MD "HCP_1";
BA_ "FlexKomSigStartPos" SG_ 701 HEV_EVT_MD 7;
BA_ "FlexKomSigStartValue" SG_ 701 HEV_EVT_MD "7BFF0B0000FF01FFh";
BA_ "GenSigCycleTime" SG_ 701 HEV_EVT_MD 100;
BA_ "GenSigSNA" SG_ 701 HEV_EVT_MD "1h";
BA_ "GenSigStartValue" SG_ 701 HEV_EVT_MD 1;
BA_ "GenSigTimeout_CBC" SG_ 701 HEV_EVT_MD 10500;
BA_ "GenSigTimeout_IC" SG_ 701 HEV_EVT_MD 1050;
BA_ "RID" SG_ 701 HEV_EVT_MD "6517";
BA_ "FlexKomComment" SG_ 701 HEV_LMP_RQ "HCP message 1 packet";
BA_ "FlexKomIsMotorola" SG_ 701 HEV_LMP_RQ 1;
BA_ "FlexKomSID" SG_ 701 HEV_LMP_RQ 2198;
BA_ "FlexKomSigLaenge" SG_ 701 HEV_LMP_RQ 64;
BA_ "FlexKomSigName" SG_ 701 HEV_LMP_RQ "HCP_1";
BA_ "FlexKomSigStartPos" SG_ 701 HEV_LMP_RQ 7;
BA_ "FlexKomSigStartValue" SG_ 701 HEV_LMP_RQ "7BFF0B0000FF01FFh";
BA_ "GenSigCycleTime" SG_ 701 HEV_LMP_RQ 100;
BA_ "GenSigSNA" SG_ 701 HEV_LMP_RQ "3h";
BA_ "GenSigStartValue" SG_ 701 HEV_LMP_RQ 3;
BA_ "GenSigTimeout_IC" SG_ 701 HEV_LMP_RQ 1050;
BA_ "FlexKomComment" SG_ 701 R134a_PressSts "HCP message 1 packet";
BA_ "FlexKomIsMotorola" SG_ 701 R134a_PressSts 1;
BA_ "FlexKomSID" SG_ 701 R134a_PressSts 2198;
BA_ "FlexKomSigLaenge" SG_ 701 R134a_PressSts 64;
BA_ "FlexKomSigName" SG_ 701 R134a_PressSts "HCP_1";
BA_ "FlexKomSigStartPos" SG_ 701 R134a_PressSts 7;
BA_ "FlexKomSigStartValue" SG_ 701 R134a_PressSts "7BFF0B0000FF01FFh";
BA_ "GenSigCycleTime" SG_ 701 R134a_PressSts 100;
BA_ "GenSigSNA" SG_ 701 R134a_PressSts "1FFh";
BA_ "GenSigStartValue" SG_ 701 R134a_PressSts 511;
BA_ "GenSigTimeout_CBC" SG_ 701 R134a_PressSts 1050;
BA_ "RID" SG_ 701 R134a_PressSts "5059";
BA_ "FlexKomComment" SG_ 655 CabinPreCondReqStat "HCP 1000ms packet";
BA_ "FlexKomIsMotorola" SG_ 655 CabinPreCondReqStat 1;
BA_ "FlexKomSID" SG_ 655 CabinPreCondReqStat 2373;
BA_ "FlexKomSigLaenge" SG_ 655 CabinPreCondReqStat 64;
BA_ "FlexKomSigName" SG_ 655 CabinPreCondReqStat "HCP_1000";
BA_ "FlexKomSigStartPos" SG_ 655 CabinPreCondReqStat 7;
BA_ "FlexKomSigStartValue" SG_ 655 CabinPreCondReqStat "0000000000000000h";
BA_ "GenSigCycleTime" SG_ 655 CabinPreCondReqStat 1000;
BA_ "GenSigSendType" SG_ 655 CabinPreCondReqStat 5;
BA_ "GenSigSNA" SG_ 655 CabinPreCondReqStat "Fh";
BA_ "GenSigTimeout_CBC" SG_ 655 CabinPreCondReqStat 10500;
BA_ "RID" SG_ 655 CabinPreCondReqStat "2868";
BA_ "FlexKomComment" SG_ 655 ChargingLevel "HCP 1000ms packet";
BA_ "FlexKomIsMotorola" SG_ 655 ChargingLevel 1;
BA_ "FlexKomSID" SG_ 655 ChargingLevel 2373;
BA_ "FlexKomSigLaenge" SG_ 655 ChargingLevel 64;
BA_ "FlexKomSigName" SG_ 655 ChargingLevel "HCP_1000";
BA_ "FlexKomSigStartPos" SG_ 655 ChargingLevel 7;
BA_ "FlexKomSigStartValue" SG_ 655 ChargingLevel "0000000000000000h";
BA_ "GenSigCycleTime" SG_ 655 ChargingLevel 1000;
BA_ "GenSigSendType" SG_ 655 ChargingLevel 5;
BA_ "GenSigSNA" SG_ 655 ChargingLevel "Fh";
BA_ "GenSigTimeout_CBC" SG_ 655 ChargingLevel 10500;
BA_ "GenSigTimeout_IC" SG_ 655 ChargingLevel 10500;
BA_ "RID" SG_ 655 ChargingLevel "6518";
BA_ "FlexKomComment" SG_ 655 ChargingSysSts "HCP 1000ms packet";
BA_ "FlexKomIsMotorola" SG_ 655 ChargingSysSts 1;
BA_ "FlexKomSID" SG_ 655 ChargingSysSts 2373;
BA_ "FlexKomSigLaenge" SG_ 655 ChargingSysSts 64;
BA_ "FlexKomSigName" SG_ 655 ChargingSysSts "HCP_1000";
BA_ "FlexKomSigStartPos" SG_ 655 ChargingSysSts 7;
BA_ "FlexKomSigStartValue" SG_ 655 ChargingSysSts "0000000000000000h";
BA_ "GenSigCycleTime" SG_ 655 ChargingSysSts 1000;
BA_ "GenSigSendType" SG_ 655 ChargingSysSts 5;
BA_ "GenSigSNA" SG_ 655 ChargingSysSts "7h";
BA_ "GenSigTimeout_CBC" SG_ 655 ChargingSysSts 10500;
BA_ "GenSigTimeout_IC" SG_ 655 ChargingSysSts 10500;
BA_ "RID" SG_ 655 ChargingSysSts "6523";
BA_ "FlexKomComment" SG_ 655 ChrgSysFault "HCP 1000ms packet";
BA_ "FlexKomIsMotorola" SG_ 655 ChrgSysFault 1;
BA_ "FlexKomSID" SG_ 655 ChrgSysFault 2373;
BA_ "FlexKomSigLaenge" SG_ 655 ChrgSysFault 64;
BA_ "FlexKomSigName" SG_ 655 ChrgSysFault "HCP_1000";
BA_ "FlexKomSigStartPos" SG_ 655 ChrgSysFault 7;
BA_ "FlexKomSigStartValue" SG_ 655 ChrgSysFault "0000000000000000h";
BA_ "GenSigCycleTime" SG_ 655 ChrgSysFault 1000;
BA_ "GenSigSendType" SG_ 655 ChrgSysFault 5;
BA_ "GenSigSNA" SG_ 655 ChrgSysFault "0h";
BA_ "GenSigTimeout_IC" SG_ 655 ChrgSysFault 10500;
BA_ "FlexKomComment" SG_ 655 CompStat "HCP 1000ms packet";
BA_ "FlexKomIsMotorola" SG_ 655 CompStat 1;
BA_ "FlexKomSID" SG_ 655 CompStat 2373;
BA_ "FlexKomSigLaenge" SG_ 655 CompStat 64;
BA_ "FlexKomSigName" SG_ 655 CompStat "HCP_1000";
BA_ "FlexKomSigStartPos" SG_ 655 CompStat 7;
BA_ "FlexKomSigStartValue" SG_ 655 CompStat "0000000000000000h";
BA_ "GenSigCycleTime" SG_ 655 CompStat 1000;
BA_ "GenSigSendType" SG_ 655 CompStat 5;
BA_ "GenSigSNA" SG_ 655 CompStat "Fh";
BA_ "GenSigTimeout_CBC" SG_ 655 CompStat 10500;
BA_ "RID" SG_ 655 CompStat "3581 3587";
BA_ "FlexKomComment" SG_ 655 DriveReady "HCP 1000ms packet";
BA_ "FlexKomIsMotorola" SG_ 655 DriveReady 1;
BA_ "FlexKomSID" SG_ 655 DriveReady 2373;
BA_ "FlexKomSigLaenge" SG_ 655 DriveReady 64;
BA_ "FlexKomSigName" SG_ 655 DriveReady "HCP_1000";
BA_ "FlexKomSigStartPos" SG_ 655 DriveReady 7;
BA_ "FlexKomSigStartValue" SG_ 655 DriveReady "0000000000000000h";
BA_ "GenSigCycleTime" SG_ 655 DriveReady 1000;
BA_ "GenSigSendType" SG_ 655 DriveReady 5;
BA_ "GenSigSNA" SG_ 655 DriveReady "0h";
BA_ "GenSigTimeout_IC" SG_ 655 DriveReady 10500;
BA_ "FlexKomComment" SG_ 655 EstTimeofChrg_Lv1 "HCP 1000ms packet";
BA_ "FlexKomIsMotorola" SG_ 655 EstTimeofChrg_Lv1 1;
BA_ "FlexKomSID" SG_ 655 EstTimeofChrg_Lv1 2373;
BA_ "FlexKomSigLaenge" SG_ 655 EstTimeofChrg_Lv1 64;
BA_ "FlexKomSigName" SG_ 655 EstTimeofChrg_Lv1 "HCP_1000";
BA_ "FlexKomSigStartPos" SG_ 655 EstTimeofChrg_Lv1 7;
BA_ "FlexKomSigStartValue" SG_ 655 EstTimeofChrg_Lv1 "0000000000000000h";
BA_ "GenSigCycleTime" SG_ 655 EstTimeofChrg_Lv1 1000;
BA_ "GenSigSendType" SG_ 655 EstTimeofChrg_Lv1 5;
BA_ "GenSigSNA" SG_ 655 EstTimeofChrg_Lv1 "1FFFh";
BA_ "GenSigTimeout_CBC" SG_ 655 EstTimeofChrg_Lv1 10500;
BA_ "GenSigTimeout_IC" SG_ 655 EstTimeofChrg_Lv1 10500;
BA_ "RID" SG_ 655 EstTimeofChrg_Lv1 "6508";
BA_ "FlexKomComment" SG_ 655 EstTimeofChrg_Lv2 "HCP 1000ms packet";
BA_ "FlexKomIsMotorola" SG_ 655 EstTimeofChrg_Lv2 1;
BA_ "FlexKomSID" SG_ 655 EstTimeofChrg_Lv2 2373;
BA_ "FlexKomSigLaenge" SG_ 655 EstTimeofChrg_Lv2 64;
BA_ "FlexKomSigName" SG_ 655 EstTimeofChrg_Lv2 "HCP_1000";
BA_ "FlexKomSigStartPos" SG_ 655 EstTimeofChrg_Lv2 7;
BA_ "FlexKomSigStartValue" SG_ 655 EstTimeofChrg_Lv2 "0000000000000000h";
BA_ "GenSigCycleTime" SG_ 655 EstTimeofChrg_Lv2 1000;
BA_ "GenSigSendType" SG_ 655 EstTimeofChrg_Lv2 5;
BA_ "GenSigSNA" SG_ 655 EstTimeofChrg_Lv2 "7FFh";
BA_ "GenSigTimeout_CBC" SG_ 655 EstTimeofChrg_Lv2 10500;
BA_ "GenSigTimeout_IC" SG_ 655 EstTimeofChrg_Lv2 10500;
BA_ "RID" SG_ 655 EstTimeofChrg_Lv2 "6507";
BA_ "FlexKomComment" SG_ 655 HVBatCntctrStat "HCP 1000ms packet";
BA_ "FlexKomIsMotorola" SG_ 655 HVBatCntctrStat 1;
BA_ "FlexKomSID" SG_ 655 HVBatCntctrStat 2373;
BA_ "FlexKomSigLaenge" SG_ 655 HVBatCntctrStat 64;
BA_ "FlexKomSigName" SG_ 655 HVBatCntctrStat "HCP_1000";
BA_ "FlexKomSigStartPos" SG_ 655 HVBatCntctrStat 7;
BA_ "FlexKomSigStartValue" SG_ 655 HVBatCntctrStat "0000000000000000h";
BA_ "GenSigCycleTime" SG_ 655 HVBatCntctrStat 1000;
BA_ "GenSigSendType" SG_ 655 HVBatCntctrStat 5;
BA_ "GenSigSNA" SG_ 655 HVBatCntctrStat "7h";
BA_ "GenSigTimeout_IC" SG_ 655 HVBatCntctrStat 10500;
BA_ "FlexKomComment" SG_ 655 HtrCoreInletTemp "HCP 1000ms packet";
BA_ "FlexKomIsMotorola" SG_ 655 HtrCoreInletTemp 1;
BA_ "FlexKomSID" SG_ 655 HtrCoreInletTemp 2373;
BA_ "FlexKomSigLaenge" SG_ 655 HtrCoreInletTemp 64;
BA_ "FlexKomSigName" SG_ 655 HtrCoreInletTemp "HCP_1000";
BA_ "FlexKomSigStartPos" SG_ 655 HtrCoreInletTemp 7;
BA_ "FlexKomSigStartValue" SG_ 655 HtrCoreInletTemp "0000000000000000h";
BA_ "GenSigCycleTime" SG_ 655 HtrCoreInletTemp 1000;
BA_ "GenSigSendType" SG_ 655 HtrCoreInletTemp 5;
BA_ "GenSigSNA" SG_ 655 HtrCoreInletTemp "FFh";
BA_ "FlexKomComment" SG_ 655 MIL_OnRq_BPCM "HCP 1000ms packet";
BA_ "FlexKomIsMotorola" SG_ 655 MIL_OnRq_BPCM 1;
BA_ "FlexKomSID" SG_ 655 MIL_OnRq_BPCM 2373;
BA_ "FlexKomSigLaenge" SG_ 655 MIL_OnRq_BPCM 64;
BA_ "FlexKomSigName" SG_ 655 MIL_OnRq_BPCM "HCP_1000";
BA_ "FlexKomSigStartPos" SG_ 655 MIL_OnRq_BPCM 7;
BA_ "FlexKomSigStartValue" SG_ 655 MIL_OnRq_BPCM "0000000000000000h";
BA_ "GenSigCycleTime" SG_ 655 MIL_OnRq_BPCM 1000;
BA_ "GenSigSendType" SG_ 655 MIL_OnRq_BPCM 5;
BA_ "GenSigSNA" SG_ 655 MIL_OnRq_BPCM "0h";
BA_ "GenSigTimeout_IC" SG_ 655 MIL_OnRq_BPCM 10500;
BA_ "FlexKomComment" SG_ 655 PrplsnSysAtv "HCP 1000ms packet";
BA_ "FlexKomIsMotorola" SG_ 655 PrplsnSysAtv 1;
BA_ "FlexKomSID" SG_ 655 PrplsnSysAtv 2373;
BA_ "FlexKomSigLaenge" SG_ 655 PrplsnSysAtv 64;
BA_ "FlexKomSigName" SG_ 655 PrplsnSysAtv "HCP_1000";
BA_ "FlexKomSigStartPos" SG_ 655 PrplsnSysAtv 7;
BA_ "FlexKomSigStartValue" SG_ 655 PrplsnSysAtv "0000000000000000h";
BA_ "GenSigCycleTime" SG_ 655 PrplsnSysAtv 1000;
BA_ "GenSigSendType" SG_ 655 PrplsnSysAtv 5;
BA_ "GenSigSNA" SG_ 655 PrplsnSysAtv "0h";
BA_ "GenSigTimeout_IC" SG_ 655 PrplsnSysAtv 10500;
BA_ "RID" SG_ 655 PrplsnSysAtv "3065";
BA_ "FlexKomComment" SG_ 291 AHH_Apply_Release_Request ".";
BA_ "FlexKomIsMotorola" SG_ 291 AHH_Apply_Release_Request 1;
BA_ "FlexKomSID" SG_ 291 AHH_Apply_Release_Request 2222;
BA_ "FlexKomSigLaenge" SG_ 291 AHH_Apply_Release_Request 64;
BA_ "FlexKomSigName" SG_ 291 AHH_Apply_Release_Request "HCP_Torq_Status";
BA_ "FlexKomSigStartPos" SG_ 291 AHH_Apply_Release_Request 7;
BA_ "FlexKomSigStartValue" SG_ 291 AHH_Apply_Release_Request "00000000000000FFh";
BA_ "GenSigCycleTime" SG_ 291 AHH_Apply_Release_Request 10;
BA_ "GenSigSNA" SG_ 291 AHH_Apply_Release_Request "7h";
BA_ "FlexKomComment" SG_ 291 AHH_ModifyAccel_Req ".";
BA_ "FlexKomIsMotorola" SG_ 291 AHH_ModifyAccel_Req 1;
BA_ "FlexKomSID" SG_ 291 AHH_ModifyAccel_Req 2222;
BA_ "FlexKomSigLaenge" SG_ 291 AHH_ModifyAccel_Req 64;
BA_ "FlexKomSigName" SG_ 291 AHH_ModifyAccel_Req "HCP_Torq_Status";
BA_ "FlexKomSigStartPos" SG_ 291 AHH_ModifyAccel_Req 7;
BA_ "FlexKomSigStartValue" SG_ 291 AHH_ModifyAccel_Req "00000000000000FFh";
BA_ "GenSigCycleTime" SG_ 291 AHH_ModifyAccel_Req 10;
BA_ "GenSigSNA" SG_ 291 AHH_ModifyAccel_Req "0h";
BA_ "FlexKomComment" SG_ 291 CRC_123h ".";
BA_ "FlexKomIsMotorola" SG_ 291 CRC_123h 1;
BA_ "FlexKomSID" SG_ 291 CRC_123h 2222;
BA_ "FlexKomSigLaenge" SG_ 291 CRC_123h 64;
BA_ "FlexKomSigName" SG_ 291 CRC_123h "HCP_Torq_Status";
BA_ "FlexKomSigStartPos" SG_ 291 CRC_123h 7;
BA_ "FlexKomSigStartValue" SG_ 291 CRC_123h "00000000000000FFh";
BA_ "GenSigCycleTime" SG_ 291 CRC_123h 10;
BA_ "GenSigSNA" SG_ 291 CRC_123h "FFh";
BA_ "GenSigStartValue" SG_ 291 CRC_123h 255;
BA_ "FlexKomComment" SG_ 291 MC_123h ".";
BA_ "FlexKomIsMotorola" SG_ 291 MC_123h 1;
BA_ "FlexKomSID" SG_ 291 MC_123h 2222;
BA_ "FlexKomSigLaenge" SG_ 291 MC_123h 64;
BA_ "FlexKomSigName" SG_ 291 MC_123h "HCP_Torq_Status";
BA_ "FlexKomSigStartPos" SG_ 291 MC_123h 7;
BA_ "FlexKomSigStartValue" SG_ 291 MC_123h "00000000000000FFh";
BA_ "GenSigCycleTime" SG_ 291 MC_123h 10;
BA_ "GenSigSNA" SG_ 291 MC_123h "0h";
BA_ "FlexKomComment" SG_ 291 M_MAX_AXLE ".";
BA_ "FlexKomIsMotorola" SG_ 291 M_MAX_AXLE 1;
BA_ "FlexKomSID" SG_ 291 M_MAX_AXLE 2222;
BA_ "FlexKomSigLaenge" SG_ 291 M_MAX_AXLE 64;
BA_ "FlexKomSigName" SG_ 291 M_MAX_AXLE "HCP_Torq_Status";
BA_ "FlexKomSigStartPos" SG_ 291 M_MAX_AXLE 7;
BA_ "FlexKomSigStartValue" SG_ 291 M_MAX_AXLE "00000000000000FFh";
BA_ "GenSigCycleTime" SG_ 291 M_MAX_AXLE 10;
BA_ "GenSigSNA" SG_ 291 M_MAX_AXLE "1FFFh";
BA_ "FlexKomComment" SG_ 291 M_MIN_AXLE ".";
BA_ "FlexKomIsMotorola" SG_ 291 M_MIN_AXLE 1;
BA_ "FlexKomSID" SG_ 291 M_MIN_AXLE 2222;
BA_ "FlexKomSigLaenge" SG_ 291 M_MIN_AXLE 64;
BA_ "FlexKomSigName" SG_ 291 M_MIN_AXLE "HCP_Torq_Status";
BA_ "FlexKomSigStartPos" SG_ 291 M_MIN_AXLE 7;
BA_ "FlexKomSigStartValue" SG_ 291 M_MIN_AXLE "00000000000000FFh";
BA_ "GenSigCycleTime" SG_ 291 M_MIN_AXLE 10;
BA_ "GenSigSNA" SG_ 291 M_MIN_AXLE "1FFFh";
BA_ "FlexKomComment" SG_ 291 M_STA_AXLE ".";
BA_ "FlexKomIsMotorola" SG_ 291 M_STA_AXLE 1;
BA_ "FlexKomSID" SG_ 291 M_STA_AXLE 2222;
BA_ "FlexKomSigLaenge" SG_ 291 M_STA_AXLE 64;
BA_ "FlexKomSigName" SG_ 291 M_STA_AXLE "HCP_Torq_Status";
BA_ "FlexKomSigStartPos" SG_ 291 M_STA_AXLE 7;
BA_ "FlexKomSigStartValue" SG_ 291 M_STA_AXLE "00000000000000FFh";
BA_ "GenSigCycleTime" SG_ 291 M_STA_AXLE 10;
BA_ "GenSigSNA" SG_ 291 M_STA_AXLE "1FFFh";
BA_ "FlexKomComment" SG_ 784 AvgFuelLvl "Average filtered fuel level in liters";
BA_ "FlexKomIsMotorola" SG_ 784 AvgFuelLvl 1;
BA_ "FlexKomSID" SG_ 784 AvgFuelLvl 848;
BA_ "FlexKomSigLaenge" SG_ 784 AvgFuelLvl 16;
BA_ "FlexKomSigName" SG_ 784 AvgFuelLvl "AvgFuelLvl";
BA_ "FlexKomSigStartPos" SG_ 784 AvgFuelLvl 7;
BA_ "FlexKomSigStartValue" SG_ 784 AvgFuelLvl "01FFh";
BA_ "GenSigCycleTime" SG_ 784 AvgFuelLvl 1000;
BA_ "GenSigSendType" SG_ 784 AvgFuelLvl 5;
BA_ "GenSigSNA" SG_ 784 AvgFuelLvl "1FFh";
BA_ "GenSigStartValue" SG_ 784 AvgFuelLvl 511;
BA_ "GenSigTimeout_CBC" SG_ 784 AvgFuelLvl 10500;
BA_ "GenSigTimeout_ETM" SG_ 784 AvgFuelLvl 10500;
BA_ "RID" SG_ 784 AvgFuelLvl "1196";
BA_ "FlexKomComment" SG_ 784 FuelLvlLow "Fuel level low";
BA_ "FlexKomIsMotorola" SG_ 784 FuelLvlLow 1;
BA_ "FlexKomSID" SG_ 784 FuelLvlLow 1049;
BA_ "FlexKomSigLaenge" SG_ 784 FuelLvlLow 1;
BA_ "FlexKomSigName" SG_ 784 FuelLvlLow "FuelLvlLow";
BA_ "FlexKomSigStartPos" SG_ 784 FuelLvlLow 6;
BA_ "FlexKomSigStartValue" SG_ 784 FuelLvlLow "00h";
BA_ "GenSigCycleTime" SG_ 784 FuelLvlLow 1000;
BA_ "GenSigSendType" SG_ 784 FuelLvlLow 5;
BA_ "GenSigSNA" SG_ 784 FuelLvlLow "0h";
BA_ "GenSigTimeout_CBC" SG_ 784 FuelLvlLow 10500;
BA_ "FlexKomComment" SG_ 784 ODO "Odometer";
BA_ "FlexKomIsMotorola" SG_ 784 ODO 1;
BA_ "FlexKomSID" SG_ 784 ODO 804;
BA_ "FlexKomSigLaenge" SG_ 784 ODO 24;
BA_ "FlexKomSigName" SG_ 784 ODO "ODO";
BA_ "FlexKomSigStartPos" SG_ 784 ODO 39;
BA_ "FlexKomSigStartValue" SG_ 784 ODO "FFFFFFh";
BA_ "GenSigCycleTime" SG_ 784 ODO 1000;
BA_ "GenSigSendType" SG_ 784 ODO 5;
BA_ "GenSigSNA" SG_ 784 ODO "FFFFFFh";
BA_ "GenSigStartValue" SG_ 784 ODO 16777215;
BA_ "GenSigTimeout_CBC" SG_ 784 ODO 10500;
BA_ "GenSigTimeout_EPS" SG_ 784 ODO 10500;
BA_ "GenSigTimeout_RHSC2" SG_ 784 ODO 10500;
BA_ "GenSigTimeout_ORC" SG_ 784 ODO 3500;
BA_ "GenSigTimeout_RF_HUB" SG_ 784 ODO 10500;
BA_ "GenSigTimeout_SCCM" SG_ 784 ODO 10500;
BA_ "RID" SG_ 784 ODO "1177 2112";
BA_ "FlexKomComment" SG_ 784 OilChgRst "Oil change reminder reset request";
BA_ "FlexKomIsMotorola" SG_ 784 OilChgRst 1;
BA_ "FlexKomSID" SG_ 784 OilChgRst 1819;
BA_ "FlexKomSigLaenge" SG_ 784 OilChgRst 1;
BA_ "FlexKomSigName" SG_ 784 OilChgRst "OilChgRst";
BA_ "FlexKomSigStartPos" SG_ 784 OilChgRst 29;
BA_ "FlexKomSigStartValue" SG_ 784 OilChgRst "00h";
BA_ "GenSigCycleTime" SG_ 784 OilChgRst 1000;
BA_ "GenSigSendType" SG_ 784 OilChgRst 5;
BA_ "GenSigSNA" SG_ 784 OilChgRst "0h";
BA_ "FlexKomComment" SG_ 784 PTS_MODE_SELECTION "Park assist maneuver selection for PTS";
BA_ "FlexKomIsMotorola" SG_ 784 PTS_MODE_SELECTION 1;
BA_ "FlexKomSID" SG_ 784 PTS_MODE_SELECTION 1910;
BA_ "FlexKomSigLaenge" SG_ 784 PTS_MODE_SELECTION 3;
BA_ "FlexKomSigName" SG_ 784 PTS_MODE_SELECTION "PTS_MODE_SELECTION";
BA_ "FlexKomSigStartPos" SG_ 784 PTS_MODE_SELECTION 62;
BA_ "FlexKomSigStartValue" SG_ 784 PTS_MODE_SELECTION "00h";
BA_ "GenSigCycleTime" SG_ 784 PTS_MODE_SELECTION 1000;
BA_ "GenSigSendType" SG_ 784 PTS_MODE_SELECTION 5;
BA_ "GenSigSNA" SG_ 784 PTS_MODE_SELECTION "7h";
BA_ "GenSigTimeout_PTS" SG_ 784 PTS_MODE_SELECTION 10500;
BA_ "FlexKomComment" SG_ 784 SBR_MuteRq "Seatbelt reminder audio mute request; Mute = [1]";
BA_ "FlexKomIsMotorola" SG_ 784 SBR_MuteRq 1;
BA_ "FlexKomSID" SG_ 784 SBR_MuteRq 2303;
BA_ "FlexKomSigLaenge" SG_ 784 SBR_MuteRq 1;
BA_ "FlexKomSigName" SG_ 784 SBR_MuteRq "SBR_MuteRq";
BA_ "FlexKomSigStartPos" SG_ 784 SBR_MuteRq 63;
BA_ "FlexKomSigStartValue" SG_ 784 SBR_MuteRq "00h";
BA_ "GenSigCycleTime" SG_ 784 SBR_MuteRq 1000;
BA_ "GenSigSendType" SG_ 784 SBR_MuteRq 5;
BA_ "GenSigSNA" SG_ 784 SBR_MuteRq "0h";
BA_ "RID" SG_ 784 SBR_MuteRq "2156";
BA_ "FlexKomComment" SG_ 784 SRS_LMP_STAT "Airbag indicator lamp status";
BA_ "FlexKomIsMotorola" SG_ 784 SRS_LMP_STAT 1;
BA_ "FlexKomSID" SG_ 784 SRS_LMP_STAT 851;
BA_ "FlexKomSigLaenge" SG_ 784 SRS_LMP_STAT 2;
BA_ "FlexKomSigName" SG_ 784 SRS_LMP_STAT "SRS_LMP_STAT";
BA_ "FlexKomSigStartPos" SG_ 784 SRS_LMP_STAT 5;
BA_ "FlexKomSigStartValue" SG_ 784 SRS_LMP_STAT "00h";
BA_ "GenSigCycleTime" SG_ 784 SRS_LMP_STAT 1000;
BA_ "GenSigSendType" SG_ 784 SRS_LMP_STAT 5;
BA_ "GenSigSNA" SG_ 784 SRS_LMP_STAT "3h";
BA_ "GenSigTimeout_ETM" SG_ 784 SRS_LMP_STAT 10500;
BA_ "GenSigTimeout_ORC" SG_ 784 SRS_LMP_STAT 3500;
BA_ "FlexKomComment" SG_ 882 CapacityUnit "Fuel capacity units";
BA_ "FlexKomIsMotorola" SG_ 882 CapacityUnit 1;
BA_ "FlexKomSID" SG_ 882 CapacityUnit 2001;
BA_ "FlexKomSigLaenge" SG_ 882 CapacityUnit 2;
BA_ "FlexKomSigName" SG_ 882 CapacityUnit "CapacityUnit";
BA_ "FlexKomSigStartPos" SG_ 882 CapacityUnit 39;
BA_ "FlexKomSigStartValue" SG_ 882 CapacityUnit "00h";
BA_ "GenSigCycleTime" SG_ 882 CapacityUnit 1000;
BA_ "GenSigSendType" SG_ 882 CapacityUnit 5;
BA_ "GenSigSNA" SG_ 882 CapacityUnit "0h";
BA_ "GenSigTimeout_CBC" SG_ 882 CapacityUnit 10500;
BA_ "RID" SG_ 882 CapacityUnit "1999";
BA_ "FlexKomComment" SG_ 882 ConsumptionUnit "Fuel consumption units";
BA_ "FlexKomIsMotorola" SG_ 882 ConsumptionUnit 1;
BA_ "FlexKomSID" SG_ 882 ConsumptionUnit 2005;
BA_ "FlexKomSigLaenge" SG_ 882 ConsumptionUnit 3;
BA_ "FlexKomSigName" SG_ 882 ConsumptionUnit "ConsumptionUnit";
BA_ "FlexKomSigStartPos" SG_ 882 ConsumptionUnit 55;
BA_ "FlexKomSigStartValue" SG_ 882 ConsumptionUnit "00h";
BA_ "GenSigCycleTime" SG_ 882 ConsumptionUnit 1000;
BA_ "GenSigSendType" SG_ 882 ConsumptionUnit 5;
BA_ "GenSigSNA" SG_ 882 ConsumptionUnit "7h";
BA_ "GenSigTimeout_CBC" SG_ 882 ConsumptionUnit 10500;
BA_ "RID" SG_ 882 ConsumptionUnit "2002";
BA_ "FlexKomComment" SG_ 882 DistanceUnit "Distance (odometer) units; Miles = [1]";
BA_ "FlexKomIsMotorola" SG_ 882 DistanceUnit 1;
BA_ "FlexKomSID" SG_ 882 DistanceUnit 2002;
BA_ "FlexKomSigLaenge" SG_ 882 DistanceUnit 1;
BA_ "FlexKomSigName" SG_ 882 DistanceUnit "DistanceUnit";
BA_ "FlexKomSigStartPos" SG_ 882 DistanceUnit 50;
BA_ "FlexKomSigStartValue" SG_ 882 DistanceUnit "00h";
BA_ "GenSigCycleTime" SG_ 882 DistanceUnit 1000;
BA_ "GenSigSendType" SG_ 882 DistanceUnit 5;
BA_ "GenSigSNA" SG_ 882 DistanceUnit "0h";
BA_ "RID" SG_ 882 DistanceUnit "1992";
BA_ "FlexKomComment" SG_ 882 Early_Fuel_TeenKey "Teen Key packet";
BA_ "FlexKomIsMotorola" SG_ 882 Early_Fuel_TeenKey 1;
BA_ "FlexKomSID" SG_ 882 Early_Fuel_TeenKey 2677;
BA_ "FlexKomSigLaenge" SG_ 882 Early_Fuel_TeenKey 2;
BA_ "FlexKomSigName" SG_ 882 Early_Fuel_TeenKey "TeenKey_Pkt";
BA_ "FlexKomSigStartPos" SG_ 882 Early_Fuel_TeenKey 27;
BA_ "FlexKomSigStartValue" SG_ 882 Early_Fuel_TeenKey "00h";
BA_ "GenSigCycleTime" SG_ 882 Early_Fuel_TeenKey 1000;
BA_ "GenSigSendType" SG_ 882 Early_Fuel_TeenKey 5;
BA_ "GenSigSNA" SG_ 882 Early_Fuel_TeenKey "0h";
BA_ "RID" SG_ 882 Early_Fuel_TeenKey "6290";
BA_ "FlexKomComment" SG_ 882 Fuel_Popup_TeenKey "Teen Key packet";
BA_ "FlexKomIsMotorola" SG_ 882 Fuel_Popup_TeenKey 1;
BA_ "FlexKomSID" SG_ 882 Fuel_Popup_TeenKey 2677;
BA_ "FlexKomSigLaenge" SG_ 882 Fuel_Popup_TeenKey 2;
BA_ "FlexKomSigName" SG_ 882 Fuel_Popup_TeenKey "TeenKey_Pkt";
BA_ "FlexKomSigStartPos" SG_ 882 Fuel_Popup_TeenKey 27;
BA_ "FlexKomSigStartValue" SG_ 882 Fuel_Popup_TeenKey "00h";
BA_ "GenSigCycleTime" SG_ 882 Fuel_Popup_TeenKey 1000;
BA_ "GenSigSendType" SG_ 882 Fuel_Popup_TeenKey 5;
BA_ "GenSigSNA" SG_ 882 Fuel_Popup_TeenKey "0h";
BA_ "RID" SG_ 882 Fuel_Popup_TeenKey "6294";
BA_ "FlexKomComment" SG_ 882 LANG_C "Configuration status";
BA_ "FlexKomIsMotorola" SG_ 882 LANG_C 1;
BA_ "FlexKomSID" SG_ 882 LANG_C 1804;
BA_ "FlexKomSigLaenge" SG_ 882 LANG_C 6;
BA_ "FlexKomSigName" SG_ 882 LANG_C "CFG_STAT_C";
BA_ "FlexKomSigStartPos" SG_ 882 LANG_C 15;
BA_ "FlexKomSigStartValue" SG_ 882 LANG_C "3Eh";
BA_ "GenSigCycleTime" SG_ 882 LANG_C 1000;
BA_ "GenSigSendType" SG_ 882 LANG_C 5;
BA_ "GenSigSNA" SG_ 882 LANG_C "1Fh";
BA_ "GenSigStartValue" SG_ 882 LANG_C 31;
BA_ "GenSigTimeout_CBC" SG_ 882 LANG_C 10500;
BA_ "RID" SG_ 882 LANG_C "1797";
BA_ "FlexKomComment" SG_ 882 PowerUnit "Power units";
BA_ "FlexKomIsMotorola" SG_ 882 PowerUnit 1;
BA_ "FlexKomSID" SG_ 882 PowerUnit 1999;
BA_ "FlexKomSigLaenge" SG_ 882 PowerUnit 2;
BA_ "FlexKomSigName" SG_ 882 PowerUnit "PowerUnit";
BA_ "FlexKomSigStartPos" SG_ 882 PowerUnit 35;
BA_ "FlexKomSigStartValue" SG_ 882 PowerUnit "00h";
BA_ "GenSigCycleTime" SG_ 882 PowerUnit 1000;
BA_ "GenSigSendType" SG_ 882 PowerUnit 5;
BA_ "GenSigSNA" SG_ 882 PowerUnit "0h";
BA_ "GenSigTimeout_CBC" SG_ 882 PowerUnit 10500;
BA_ "RID" SG_ 882 PowerUnit "2007";
BA_ "FlexKomComment" SG_ 882 PressureUnit "Pressure units";
BA_ "FlexKomIsMotorola" SG_ 882 PressureUnit 1;
BA_ "FlexKomSID" SG_ 882 PressureUnit 2000;
BA_ "FlexKomSigLaenge" SG_ 882 PressureUnit 2;
BA_ "FlexKomSigName" SG_ 882 PressureUnit "PressureUnit";
BA_ "FlexKomSigStartPos" SG_ 882 PressureUnit 37;
BA_ "FlexKomSigStartValue" SG_ 882 PressureUnit "00h";
BA_ "GenSigCycleTime" SG_ 882 PressureUnit 1000;
BA_ "GenSigSendType" SG_ 882 PressureUnit 5;
BA_ "GenSigSNA" SG_ 882 PressureUnit "0h";
BA_ "GenSigTimeout_CBC" SG_ 882 PressureUnit 10500;
BA_ "RID" SG_ 882 PressureUnit "1998";
BA_ "FlexKomComment" SG_ 882 RDY_DRV_STAT_CSO "Ready to drive popup status enable/disable; Disabl";
BA_ "FlexKomIsMotorola" SG_ 882 RDY_DRV_STAT_CSO 1;
BA_ "FlexKomSID" SG_ 882 RDY_DRV_STAT_CSO 2592;
BA_ "FlexKomSigLaenge" SG_ 882 RDY_DRV_STAT_CSO 1;
BA_ "FlexKomSigName" SG_ 882 RDY_DRV_STAT_CSO "RDY_DRV_STAT_CSO";
BA_ "FlexKomSigStartPos" SG_ 882 RDY_DRV_STAT_CSO 17;
BA_ "FlexKomSigStartValue" SG_ 882 RDY_DRV_STAT_CSO "00h";
BA_ "GenSigCycleTime" SG_ 882 RDY_DRV_STAT_CSO 1000;
BA_ "GenSigSendType" SG_ 882 RDY_DRV_STAT_CSO 5;
BA_ "GenSigSNA" SG_ 882 RDY_DRV_STAT_CSO "0h";
BA_ "RID" SG_ 882 RDY_DRV_STAT_CSO "5028";
BA_ "FlexKomComment" SG_ 882 SpeedUnit "Speed (speedometer) units; Miles = [1]";
BA_ "FlexKomIsMotorola" SG_ 882 SpeedUnit 1;
BA_ "FlexKomSID" SG_ 882 SpeedUnit 2004;
BA_ "FlexKomSigLaenge" SG_ 882 SpeedUnit 1;
BA_ "FlexKomSigName" SG_ 882 SpeedUnit "SpeedUnit";
BA_ "FlexKomSigStartPos" SG_ 882 SpeedUnit 51;
BA_ "FlexKomSigStartValue" SG_ 882 SpeedUnit "00h";
BA_ "GenSigCycleTime" SG_ 882 SpeedUnit 1000;
BA_ "GenSigSendType" SG_ 882 SpeedUnit 5;
BA_ "GenSigSNA" SG_ 882 SpeedUnit "0h";
BA_ "RID" SG_ 882 SpeedUnit "2000";
BA_ "FlexKomComment" SG_ 882 TemperatureUnit "Temperature units; Farenheit = [1]";
BA_ "FlexKomIsMotorola" SG_ 882 TemperatureUnit 1;
BA_ "FlexKomSID" SG_ 882 TemperatureUnit 2003;
BA_ "FlexKomSigLaenge" SG_ 882 TemperatureUnit 1;
BA_ "FlexKomSigName" SG_ 882 TemperatureUnit "TemperatureUnit";
BA_ "FlexKomSigStartPos" SG_ 882 TemperatureUnit 52;
BA_ "FlexKomSigStartValue" SG_ 882 TemperatureUnit "00h";
BA_ "GenSigCycleTime" SG_ 882 TemperatureUnit 1000;
BA_ "GenSigSendType" SG_ 882 TemperatureUnit 5;
BA_ "GenSigSNA" SG_ 882 TemperatureUnit "0h";
BA_ "RID" SG_ 882 TemperatureUnit "2004";
BA_ "FlexKomComment" SG_ 882 TorqueUnit "Torque units; Foot Pounds (ft-lb) = [1]";
BA_ "FlexKomIsMotorola" SG_ 882 TorqueUnit 1;
BA_ "FlexKomSID" SG_ 882 TorqueUnit 1998;
BA_ "FlexKomSigLaenge" SG_ 882 TorqueUnit 1;
BA_ "FlexKomSigName" SG_ 882 TorqueUnit "TorqueUnit";
BA_ "FlexKomSigStartPos" SG_ 882 TorqueUnit 7;
BA_ "FlexKomSigStartValue" SG_ 882 TorqueUnit "00h";
BA_ "GenSigCycleTime" SG_ 882 TorqueUnit 1000;
BA_ "GenSigSendType" SG_ 882 TorqueUnit 5;
BA_ "GenSigSNA" SG_ 882 TorqueUnit "0h";
BA_ "RID" SG_ 882 TorqueUnit "1994";
BA_ "FlexKomComment" SG_ 995 NET_CFG_STAT_INT "Network ECU config data for interior";
BA_ "FlexKomIsMotorola" SG_ 995 NET_CFG_STAT_INT 1;
BA_ "FlexKomSID" SG_ 995 NET_CFG_STAT_INT 38;
BA_ "FlexKomSigLaenge" SG_ 995 NET_CFG_STAT_INT 64;
BA_ "FlexKomSigName" SG_ 995 NET_CFG_STAT_INT "NET_CFG_DATA_INT";
BA_ "FlexKomSigStartPos" SG_ 995 NET_CFG_STAT_INT 7;
BA_ "FlexKomSigStartValue" SG_ 995 NET_CFG_STAT_INT "0300000000000000h";
BA_ "GenSigCycleTime" SG_ 995 NET_CFG_STAT_INT 2000;
BA_ "GenSigSendType" SG_ 995 NET_CFG_STAT_INT 5;
BA_ "GenSigSNA" SG_ 995 NET_CFG_STAT_INT "3h";
BA_ "GenSigStartValue" SG_ 995 NET_CFG_STAT_INT 3;
BA_ "GenSigTimeout_IC" SG_ 995 NET_CFG_STAT_INT 21000;
BA_ "GenSigTimeout_RF_HUB" SG_ 995 NET_CFG_STAT_INT 21000;
BA_ "FlexKomComment" SG_ 995 NetCfg_AMP_I "Network ECU config data for interior";
BA_ "FlexKomIsMotorola" SG_ 995 NetCfg_AMP_I 1;
BA_ "FlexKomSID" SG_ 995 NetCfg_AMP_I 38;
BA_ "FlexKomSigLaenge" SG_ 995 NetCfg_AMP_I 64;
BA_ "FlexKomSigName" SG_ 995 NetCfg_AMP_I "NET_CFG_DATA_INT";
BA_ "FlexKomSigStartPos" SG_ 995 NetCfg_AMP_I 7;
BA_ "FlexKomSigStartValue" SG_ 995 NetCfg_AMP_I "0300000000000000h";
BA_ "GenSigCycleTime" SG_ 995 NetCfg_AMP_I 2000;
BA_ "GenSigSendType" SG_ 995 NetCfg_AMP_I 5;
BA_ "GenSigSNA" SG_ 995 NetCfg_AMP_I "0h";
BA_ "GenSigTimeout_RF_HUB" SG_ 995 NetCfg_AMP_I 21000;
BA_ "FlexKomComment" SG_ 995 NetCfg_ANC_I "Network ECU config data for interior";
BA_ "FlexKomIsMotorola" SG_ 995 NetCfg_ANC_I 1;
BA_ "FlexKomSID" SG_ 995 NetCfg_ANC_I 38;
BA_ "FlexKomSigLaenge" SG_ 995 NetCfg_ANC_I 64;
BA_ "FlexKomSigName" SG_ 995 NetCfg_ANC_I "NET_CFG_DATA_INT";
BA_ "FlexKomSigStartPos" SG_ 995 NetCfg_ANC_I 7;
BA_ "FlexKomSigStartValue" SG_ 995 NetCfg_ANC_I "0300000000000000h";
BA_ "GenSigCycleTime" SG_ 995 NetCfg_ANC_I 2000;
BA_ "GenSigSendType" SG_ 995 NetCfg_ANC_I 5;
BA_ "GenSigSNA" SG_ 995 NetCfg_ANC_I "0h";
BA_ "GenSigTimeout_RF_HUB" SG_ 995 NetCfg_ANC_I 21000;
BA_ "FlexKomComment" SG_ 995 NetCfg_BSM "Network ECU config data for interior";
BA_ "FlexKomIsMotorola" SG_ 995 NetCfg_BSM 1;
BA_ "FlexKomSID" SG_ 995 NetCfg_BSM 38;
BA_ "FlexKomSigLaenge" SG_ 995 NetCfg_BSM 64;
BA_ "FlexKomSigName" SG_ 995 NetCfg_BSM "NET_CFG_DATA_INT";
BA_ "FlexKomSigStartPos" SG_ 995 NetCfg_BSM 7;
BA_ "FlexKomSigStartValue" SG_ 995 NetCfg_BSM "0300000000000000h";
BA_ "GenSigCycleTime" SG_ 995 NetCfg_BSM 2000;
BA_ "GenSigSendType" SG_ 995 NetCfg_BSM 5;
BA_ "GenSigSNA" SG_ 995 NetCfg_BSM "0h";
BA_ "GenSigTimeout_IC" SG_ 995 NetCfg_BSM 21000;
BA_ "GenSigTimeout_RF_HUB" SG_ 995 NetCfg_BSM 21000;
BA_ "FlexKomComment" SG_ 995 NetCfg_CBC_IN "Network ECU config data for interior";
BA_ "FlexKomIsMotorola" SG_ 995 NetCfg_CBC_IN 1;
BA_ "FlexKomSID" SG_ 995 NetCfg_CBC_IN 38;
BA_ "FlexKomSigLaenge" SG_ 995 NetCfg_CBC_IN 64;
BA_ "FlexKomSigName" SG_ 995 NetCfg_CBC_IN "NET_CFG_DATA_INT";
BA_ "FlexKomSigStartPos" SG_ 995 NetCfg_CBC_IN 7;
BA_ "FlexKomSigStartValue" SG_ 995 NetCfg_CBC_IN "0300000000000000h";
BA_ "GenSigCycleTime" SG_ 995 NetCfg_CBC_IN 2000;
BA_ "GenSigSendType" SG_ 995 NetCfg_CBC_IN 5;
BA_ "GenSigSNA" SG_ 995 NetCfg_CBC_IN "0h";
BA_ "GenSigTimeout_IC" SG_ 995 NetCfg_CBC_IN 21000;
BA_ "GenSigTimeout_RF_HUB" SG_ 995 NetCfg_CBC_IN 21000;
BA_ "FlexKomComment" SG_ 995 NetCfg_CLOCK "Network ECU config data for interior";
BA_ "FlexKomIsMotorola" SG_ 995 NetCfg_CLOCK 1;
BA_ "FlexKomSID" SG_ 995 NetCfg_CLOCK 38;
BA_ "FlexKomSigLaenge" SG_ 995 NetCfg_CLOCK 64;
BA_ "FlexKomSigName" SG_ 995 NetCfg_CLOCK "NET_CFG_DATA_INT";
BA_ "FlexKomSigStartPos" SG_ 995 NetCfg_CLOCK 7;
BA_ "FlexKomSigStartValue" SG_ 995 NetCfg_CLOCK "0300000000000000h";
BA_ "GenSigCycleTime" SG_ 995 NetCfg_CLOCK 2000;
BA_ "GenSigSendType" SG_ 995 NetCfg_CLOCK 5;
BA_ "GenSigSNA" SG_ 995 NetCfg_CLOCK "0h";
BA_ "GenSigTimeout_RF_HUB" SG_ 995 NetCfg_CLOCK 21000;
BA_ "FlexKomComment" SG_ 995 NetCfg_CRSM "Network ECU config data for interior";
BA_ "FlexKomIsMotorola" SG_ 995 NetCfg_CRSM 1;
BA_ "FlexKomSID" SG_ 995 NetCfg_CRSM 38;
BA_ "FlexKomSigLaenge" SG_ 995 NetCfg_CRSM 64;
BA_ "FlexKomSigName" SG_ 995 NetCfg_CRSM "NET_CFG_DATA_INT";
BA_ "FlexKomSigStartPos" SG_ 995 NetCfg_CRSM 7;
BA_ "FlexKomSigStartValue" SG_ 995 NetCfg_CRSM "0300000000000000h";
BA_ "GenSigCycleTime" SG_ 995 NetCfg_CRSM 2000;
BA_ "GenSigSendType" SG_ 995 NetCfg_CRSM 5;
BA_ "GenSigSNA" SG_ 995 NetCfg_CRSM "0h";
BA_ "GenSigTimeout_RF_HUB" SG_ 995 NetCfg_CRSM 21000;
BA_ "FlexKomComment" SG_ 995 NetCfg_CSWM "Network ECU config data for interior";
BA_ "FlexKomIsMotorola" SG_ 995 NetCfg_CSWM 1;
BA_ "FlexKomSID" SG_ 995 NetCfg_CSWM 38;
BA_ "FlexKomSigLaenge" SG_ 995 NetCfg_CSWM 64;
BA_ "FlexKomSigName" SG_ 995 NetCfg_CSWM "NET_CFG_DATA_INT";
BA_ "FlexKomSigStartPos" SG_ 995 NetCfg_CSWM 7;
BA_ "FlexKomSigStartValue" SG_ 995 NetCfg_CSWM "0300000000000000h";
BA_ "GenSigCycleTime" SG_ 995 NetCfg_CSWM 2000;
BA_ "GenSigSendType" SG_ 995 NetCfg_CSWM 5;
BA_ "GenSigSNA" SG_ 995 NetCfg_CSWM "0h";
BA_ "GenSigTimeout_IC" SG_ 995 NetCfg_CSWM 21000;
BA_ "GenSigTimeout_RF_HUB" SG_ 995 NetCfg_CSWM 21000;
BA_ "FlexKomComment" SG_ 995 NetCfg_CVPM "Network ECU config data for interior";
BA_ "FlexKomIsMotorola" SG_ 995 NetCfg_CVPM 1;
BA_ "FlexKomSID" SG_ 995 NetCfg_CVPM 38;
BA_ "FlexKomSigLaenge" SG_ 995 NetCfg_CVPM 64;
BA_ "FlexKomSigName" SG_ 995 NetCfg_CVPM "NET_CFG_DATA_INT";
BA_ "FlexKomSigStartPos" SG_ 995 NetCfg_CVPM 7;
BA_ "FlexKomSigStartValue" SG_ 995 NetCfg_CVPM "0300000000000000h";
BA_ "GenSigCycleTime" SG_ 995 NetCfg_CVPM 2000;
BA_ "GenSigSendType" SG_ 995 NetCfg_CVPM 5;
BA_ "GenSigSNA" SG_ 995 NetCfg_CVPM "0h";
BA_ "GenSigTimeout_RF_HUB" SG_ 995 NetCfg_CVPM 21000;
BA_ "FlexKomComment" SG_ 995 NetCfg_DCM_DR "Network ECU config data for interior";
BA_ "FlexKomIsMotorola" SG_ 995 NetCfg_DCM_DR 1;
BA_ "FlexKomSID" SG_ 995 NetCfg_DCM_DR 38;
BA_ "FlexKomSigLaenge" SG_ 995 NetCfg_DCM_DR 64;
BA_ "FlexKomSigName" SG_ 995 NetCfg_DCM_DR "NET_CFG_DATA_INT";
BA_ "FlexKomSigStartPos" SG_ 995 NetCfg_DCM_DR 7;
BA_ "FlexKomSigStartValue" SG_ 995 NetCfg_DCM_DR "0300000000000000h";
BA_ "GenSigCycleTime" SG_ 995 NetCfg_DCM_DR 2000;
BA_ "GenSigSendType" SG_ 995 NetCfg_DCM_DR 5;
BA_ "GenSigSNA" SG_ 995 NetCfg_DCM_DR "0h";
BA_ "GenSigTimeout_IC" SG_ 995 NetCfg_DCM_DR 21000;
BA_ "GenSigTimeout_RF_HUB" SG_ 995 NetCfg_DCM_DR 21000;
BA_ "FlexKomComment" SG_ 995 NetCfg_DCM_PASS "Network ECU config data for interior";
BA_ "FlexKomIsMotorola" SG_ 995 NetCfg_DCM_PASS 1;
BA_ "FlexKomSID" SG_ 995 NetCfg_DCM_PASS 38;
BA_ "FlexKomSigLaenge" SG_ 995 NetCfg_DCM_PASS 64;
BA_ "FlexKomSigName" SG_ 995 NetCfg_DCM_PASS "NET_CFG_DATA_INT";
BA_ "FlexKomSigStartPos" SG_ 995 NetCfg_DCM_PASS 7;
BA_ "FlexKomSigStartValue" SG_ 995 NetCfg_DCM_PASS "0300000000000000h";
BA_ "GenSigCycleTime" SG_ 995 NetCfg_DCM_PASS 2000;
BA_ "GenSigSendType" SG_ 995 NetCfg_DCM_PASS 5;
BA_ "GenSigSNA" SG_ 995 NetCfg_DCM_PASS "0h";
BA_ "GenSigTimeout_IC" SG_ 995 NetCfg_DCM_PASS 21000;
BA_ "GenSigTimeout_RF_HUB" SG_ 995 NetCfg_DCM_PASS 21000;
BA_ "FlexKomComment" SG_ 995 NetCfg_DCM_RL "Network ECU config data for interior";
BA_ "FlexKomIsMotorola" SG_ 995 NetCfg_DCM_RL 1;
BA_ "FlexKomSID" SG_ 995 NetCfg_DCM_RL 38;
BA_ "FlexKomSigLaenge" SG_ 995 NetCfg_DCM_RL 64;
BA_ "FlexKomSigName" SG_ 995 NetCfg_DCM_RL "NET_CFG_DATA_INT";
BA_ "FlexKomSigStartPos" SG_ 995 NetCfg_DCM_RL 7;
BA_ "FlexKomSigStartValue" SG_ 995 NetCfg_DCM_RL "0300000000000000h";
BA_ "GenSigCycleTime" SG_ 995 NetCfg_DCM_RL 2000;
BA_ "GenSigSendType" SG_ 995 NetCfg_DCM_RL 5;
BA_ "GenSigSNA" SG_ 995 NetCfg_DCM_RL "0h";
BA_ "GenSigTimeout_IC" SG_ 995 NetCfg_DCM_RL 21000;
BA_ "GenSigTimeout_RF_HUB" SG_ 995 NetCfg_DCM_RL 21000;
BA_ "FlexKomComment" SG_ 995 NetCfg_DCM_RR "Network ECU config data for interior";
BA_ "FlexKomIsMotorola" SG_ 995 NetCfg_DCM_RR 1;
BA_ "FlexKomSID" SG_ 995 NetCfg_DCM_RR 38;
BA_ "FlexKomSigLaenge" SG_ 995 NetCfg_DCM_RR 64;
BA_ "FlexKomSigName" SG_ 995 NetCfg_DCM_RR "NET_CFG_DATA_INT";
BA_ "FlexKomSigStartPos" SG_ 995 NetCfg_DCM_RR 7;
BA_ "FlexKomSigStartValue" SG_ 995 NetCfg_DCM_RR "0300000000000000h";
BA_ "GenSigCycleTime" SG_ 995 NetCfg_DCM_RR 2000;
BA_ "GenSigSendType" SG_ 995 NetCfg_DCM_RR 5;
BA_ "GenSigSNA" SG_ 995 NetCfg_DCM_RR "0h";
BA_ "GenSigTimeout_IC" SG_ 995 NetCfg_DCM_RR 21000;
BA_ "GenSigTimeout_RF_HUB" SG_ 995 NetCfg_DCM_RR 21000;
BA_ "FlexKomComment" SG_ 995 NetCfg_DCSD "Network ECU config data for interior";
BA_ "FlexKomIsMotorola" SG_ 995 NetCfg_DCSD 1;
BA_ "FlexKomSID" SG_ 995 NetCfg_DCSD 38;
BA_ "FlexKomSigLaenge" SG_ 995 NetCfg_DCSD 64;
BA_ "FlexKomSigName" SG_ 995 NetCfg_DCSD "NET_CFG_DATA_INT";
BA_ "FlexKomSigStartPos" SG_ 995 NetCfg_DCSD 7;
BA_ "FlexKomSigStartValue" SG_ 995 NetCfg_DCSD "0300000000000000h";
BA_ "GenSigCycleTime" SG_ 995 NetCfg_DCSD 2000;
BA_ "GenSigSendType" SG_ 995 NetCfg_DCSD 5;
BA_ "GenSigSNA" SG_ 995 NetCfg_DCSD "0h";
BA_ "GenSigTimeout_RF_HUB" SG_ 995 NetCfg_DCSD 21000;
BA_ "FlexKomComment" SG_ 995 NetCfg_DTV "Network ECU config data for interior";
BA_ "FlexKomIsMotorola" SG_ 995 NetCfg_DTV 1;
BA_ "FlexKomSID" SG_ 995 NetCfg_DTV 38;
BA_ "FlexKomSigLaenge" SG_ 995 NetCfg_DTV 64;
BA_ "FlexKomSigName" SG_ 995 NetCfg_DTV "NET_CFG_DATA_INT";
BA_ "FlexKomSigStartPos" SG_ 995 NetCfg_DTV 7;
BA_ "FlexKomSigStartValue" SG_ 995 NetCfg_DTV "0300000000000000h";
BA_ "GenSigCycleTime" SG_ 995 NetCfg_DTV 2000;
BA_ "GenSigSendType" SG_ 995 NetCfg_DTV 5;
BA_ "GenSigSNA" SG_ 995 NetCfg_DTV "0h";
BA_ "GenSigTimeout_RF_HUB" SG_ 995 NetCfg_DTV 21000;
BA_ "FlexKomComment" SG_ 995 NetCfg_DVD_CDM "Network ECU config data for interior";
BA_ "FlexKomIsMotorola" SG_ 995 NetCfg_DVD_CDM 1;
BA_ "FlexKomSID" SG_ 995 NetCfg_DVD_CDM 38;
BA_ "FlexKomSigLaenge" SG_ 995 NetCfg_DVD_CDM 64;
BA_ "FlexKomSigName" SG_ 995 NetCfg_DVD_CDM "NET_CFG_DATA_INT";
BA_ "FlexKomSigStartPos" SG_ 995 NetCfg_DVD_CDM 7;
BA_ "FlexKomSigStartValue" SG_ 995 NetCfg_DVD_CDM "0300000000000000h";
BA_ "GenSigCycleTime" SG_ 995 NetCfg_DVD_CDM 2000;
BA_ "GenSigSendType" SG_ 995 NetCfg_DVD_CDM 5;
BA_ "GenSigSNA" SG_ 995 NetCfg_DVD_CDM "0h";
BA_ "GenSigTimeout_RF_HUB" SG_ 995 NetCfg_DVD_CDM 21000;
BA_ "FlexKomComment" SG_ 995 NetCfg_FSM "Network ECU config data for interior";
BA_ "FlexKomIsMotorola" SG_ 995 NetCfg_FSM 1;
BA_ "FlexKomSID" SG_ 995 NetCfg_FSM 38;
BA_ "FlexKomSigLaenge" SG_ 995 NetCfg_FSM 64;
BA_ "FlexKomSigName" SG_ 995 NetCfg_FSM "NET_CFG_DATA_INT";
BA_ "FlexKomSigStartPos" SG_ 995 NetCfg_FSM 7;
BA_ "FlexKomSigStartValue" SG_ 995 NetCfg_FSM "0300000000000000h";
BA_ "GenSigCycleTime" SG_ 995 NetCfg_FSM 2000;
BA_ "GenSigSendType" SG_ 995 NetCfg_FSM 5;
BA_ "GenSigSNA" SG_ 995 NetCfg_FSM "0h";
BA_ "GenSigTimeout_IC" SG_ 995 NetCfg_FSM 21000;
BA_ "GenSigTimeout_RF_HUB" SG_ 995 NetCfg_FSM 21000;
BA_ "FlexKomComment" SG_ 995 NetCfg_HFM_CTM "Network ECU config data for interior";
BA_ "FlexKomIsMotorola" SG_ 995 NetCfg_HFM_CTM 1;
BA_ "FlexKomSID" SG_ 995 NetCfg_HFM_CTM 38;
BA_ "FlexKomSigLaenge" SG_ 995 NetCfg_HFM_CTM 64;
BA_ "FlexKomSigName" SG_ 995 NetCfg_HFM_CTM "NET_CFG_DATA_INT";
BA_ "FlexKomSigStartPos" SG_ 995 NetCfg_HFM_CTM 7;
BA_ "FlexKomSigStartValue" SG_ 995 NetCfg_HFM_CTM "0300000000000000h";
BA_ "GenSigCycleTime" SG_ 995 NetCfg_HFM_CTM 2000;
BA_ "GenSigSendType" SG_ 995 NetCfg_HFM_CTM 5;
BA_ "GenSigSNA" SG_ 995 NetCfg_HFM_CTM "0h";
BA_ "GenSigTimeout_RF_HUB" SG_ 995 NetCfg_HFM_CTM 21000;
BA_ "FlexKomComment" SG_ 995 NetCfg_HVAC "Network ECU config data for interior";
BA_ "FlexKomIsMotorola" SG_ 995 NetCfg_HVAC 1;
BA_ "FlexKomSID" SG_ 995 NetCfg_HVAC 38;
BA_ "FlexKomSigLaenge" SG_ 995 NetCfg_HVAC 64;
BA_ "FlexKomSigName" SG_ 995 NetCfg_HVAC "NET_CFG_DATA_INT";
BA_ "FlexKomSigStartPos" SG_ 995 NetCfg_HVAC 7;
BA_ "FlexKomSigStartValue" SG_ 995 NetCfg_HVAC "0300000000000000h";
BA_ "GenSigCycleTime" SG_ 995 NetCfg_HVAC 2000;
BA_ "GenSigSendType" SG_ 995 NetCfg_HVAC 5;
BA_ "GenSigSNA" SG_ 995 NetCfg_HVAC "0h";
BA_ "GenSigTimeout_IC" SG_ 995 NetCfg_HVAC 21000;
BA_ "GenSigTimeout_RF_HUB" SG_ 995 NetCfg_HVAC 21000;
BA_ "FlexKomComment" SG_ 995 NetCfg_HVAC_R "Network ECU config data for interior";
BA_ "FlexKomIsMotorola" SG_ 995 NetCfg_HVAC_R 1;
BA_ "FlexKomSID" SG_ 995 NetCfg_HVAC_R 38;
BA_ "FlexKomSigLaenge" SG_ 995 NetCfg_HVAC_R 64;
BA_ "FlexKomSigName" SG_ 995 NetCfg_HVAC_R "NET_CFG_DATA_INT";
BA_ "FlexKomSigStartPos" SG_ 995 NetCfg_HVAC_R 7;
BA_ "FlexKomSigStartValue" SG_ 995 NetCfg_HVAC_R "0300000000000000h";
BA_ "GenSigCycleTime" SG_ 995 NetCfg_HVAC_R 2000;
BA_ "GenSigSendType" SG_ 995 NetCfg_HVAC_R 5;
BA_ "GenSigSNA" SG_ 995 NetCfg_HVAC_R "0h";
BA_ "GenSigTimeout_RF_HUB" SG_ 995 NetCfg_HVAC_R 21000;
BA_ "FlexKomComment" SG_ 995 NetCfg_ICS_I "Network ECU config data for interior";
BA_ "FlexKomIsMotorola" SG_ 995 NetCfg_ICS_I 1;
BA_ "FlexKomSID" SG_ 995 NetCfg_ICS_I 38;
BA_ "FlexKomSigLaenge" SG_ 995 NetCfg_ICS_I 64;
BA_ "FlexKomSigName" SG_ 995 NetCfg_ICS_I "NET_CFG_DATA_INT";
BA_ "FlexKomSigStartPos" SG_ 995 NetCfg_ICS_I 7;
BA_ "FlexKomSigStartValue" SG_ 995 NetCfg_ICS_I "0300000000000000h";
BA_ "GenSigCycleTime" SG_ 995 NetCfg_ICS_I 2000;
BA_ "GenSigSendType" SG_ 995 NetCfg_ICS_I 5;
BA_ "GenSigSNA" SG_ 995 NetCfg_ICS_I "0h";
BA_ "GenSigTimeout_RF_HUB" SG_ 995 NetCfg_ICS_I 21000;
BA_ "FlexKomComment" SG_ 995 NetCfg_ICS_R "Network ECU config data for interior";
BA_ "FlexKomIsMotorola" SG_ 995 NetCfg_ICS_R 1;
BA_ "FlexKomSID" SG_ 995 NetCfg_ICS_R 38;
BA_ "FlexKomSigLaenge" SG_ 995 NetCfg_ICS_R 64;
BA_ "FlexKomSigName" SG_ 995 NetCfg_ICS_R "NET_CFG_DATA_INT";
BA_ "FlexKomSigStartPos" SG_ 995 NetCfg_ICS_R 7;
BA_ "FlexKomSigStartValue" SG_ 995 NetCfg_ICS_R "0300000000000000h";
BA_ "GenSigCycleTime" SG_ 995 NetCfg_ICS_R 2000;
BA_ "GenSigSendType" SG_ 995 NetCfg_ICS_R 5;
BA_ "GenSigSNA" SG_ 995 NetCfg_ICS_R "0h";
BA_ "GenSigTimeout_RF_HUB" SG_ 995 NetCfg_ICS_R 21000;
BA_ "FlexKomComment" SG_ 995 NetCfg_ITM "Network ECU config data for interior";
BA_ "FlexKomIsMotorola" SG_ 995 NetCfg_ITM 1;
BA_ "FlexKomSID" SG_ 995 NetCfg_ITM 38;
BA_ "FlexKomSigLaenge" SG_ 995 NetCfg_ITM 64;
BA_ "FlexKomSigName" SG_ 995 NetCfg_ITM "NET_CFG_DATA_INT";
BA_ "FlexKomSigStartPos" SG_ 995 NetCfg_ITM 7;
BA_ "FlexKomSigStartValue" SG_ 995 NetCfg_ITM "0300000000000000h";
BA_ "GenSigCycleTime" SG_ 995 NetCfg_ITM 2000;
BA_ "GenSigSendType" SG_ 995 NetCfg_ITM 5;
BA_ "GenSigSNA" SG_ 995 NetCfg_ITM "0h";
BA_ "GenSigTimeout_IC" SG_ 995 NetCfg_ITM 21000;
BA_ "GenSigTimeout_RF_HUB" SG_ 995 NetCfg_ITM 21000;
BA_ "FlexKomComment" SG_ 995 NetCfg_MSM "Network ECU config data for interior";
BA_ "FlexKomIsMotorola" SG_ 995 NetCfg_MSM 1;
BA_ "FlexKomSID" SG_ 995 NetCfg_MSM 38;
BA_ "FlexKomSigLaenge" SG_ 995 NetCfg_MSM 64;
BA_ "FlexKomSigName" SG_ 995 NetCfg_MSM "NET_CFG_DATA_INT";
BA_ "FlexKomSigStartPos" SG_ 995 NetCfg_MSM 7;
BA_ "FlexKomSigStartValue" SG_ 995 NetCfg_MSM "0300000000000000h";
BA_ "GenSigCycleTime" SG_ 995 NetCfg_MSM 2000;
BA_ "GenSigSendType" SG_ 995 NetCfg_MSM 5;
BA_ "GenSigSNA" SG_ 995 NetCfg_MSM "0h";
BA_ "GenSigTimeout_IC" SG_ 995 NetCfg_MSM 21000;
BA_ "GenSigTimeout_RF_HUB" SG_ 995 NetCfg_MSM 21000;
BA_ "FlexKomComment" SG_ 995 NetCfg_MSM_PASS "Network ECU config data for interior";
BA_ "FlexKomIsMotorola" SG_ 995 NetCfg_MSM_PASS 1;
BA_ "FlexKomSID" SG_ 995 NetCfg_MSM_PASS 38;
BA_ "FlexKomSigLaenge" SG_ 995 NetCfg_MSM_PASS 64;
BA_ "FlexKomSigName" SG_ 995 NetCfg_MSM_PASS "NET_CFG_DATA_INT";
BA_ "FlexKomSigStartPos" SG_ 995 NetCfg_MSM_PASS 7;
BA_ "FlexKomSigStartValue" SG_ 995 NetCfg_MSM_PASS "0300000000000000h";
BA_ "GenSigCycleTime" SG_ 995 NetCfg_MSM_PASS 2000;
BA_ "GenSigSendType" SG_ 995 NetCfg_MSM_PASS 5;
BA_ "GenSigSNA" SG_ 995 NetCfg_MSM_PASS "0h";
BA_ "GenSigTimeout_RF_HUB" SG_ 995 NetCfg_MSM_PASS 21000;
BA_ "FlexKomComment" SG_ 995 NetCfg_PLG "Network ECU config data for interior";
BA_ "FlexKomIsMotorola" SG_ 995 NetCfg_PLG 1;
BA_ "FlexKomSID" SG_ 995 NetCfg_PLG 38;
BA_ "FlexKomSigLaenge" SG_ 995 NetCfg_PLG 64;
BA_ "FlexKomSigName" SG_ 995 NetCfg_PLG "NET_CFG_DATA_INT";
BA_ "FlexKomSigStartPos" SG_ 995 NetCfg_PLG 7;
BA_ "FlexKomSigStartValue" SG_ 995 NetCfg_PLG "0300000000000000h";
BA_ "GenSigCycleTime" SG_ 995 NetCfg_PLG 2000;
BA_ "GenSigSendType" SG_ 995 NetCfg_PLG 5;
BA_ "GenSigSNA" SG_ 995 NetCfg_PLG "0h";
BA_ "GenSigTimeout_IC" SG_ 995 NetCfg_PLG 21000;
BA_ "GenSigTimeout_RF_HUB" SG_ 995 NetCfg_PLG 21000;
BA_ "FlexKomComment" SG_ 995 NetCfg_PSD_LT "Network ECU config data for interior";
BA_ "FlexKomIsMotorola" SG_ 995 NetCfg_PSD_LT 1;
BA_ "FlexKomSID" SG_ 995 NetCfg_PSD_LT 38;
BA_ "FlexKomSigLaenge" SG_ 995 NetCfg_PSD_LT 64;
BA_ "FlexKomSigName" SG_ 995 NetCfg_PSD_LT "NET_CFG_DATA_INT";
BA_ "FlexKomSigStartPos" SG_ 995 NetCfg_PSD_LT 7;
BA_ "FlexKomSigStartValue" SG_ 995 NetCfg_PSD_LT "0300000000000000h";
BA_ "GenSigCycleTime" SG_ 995 NetCfg_PSD_LT 2000;
BA_ "GenSigSendType" SG_ 995 NetCfg_PSD_LT 5;
BA_ "GenSigSNA" SG_ 995 NetCfg_PSD_LT "0h";
BA_ "GenSigTimeout_IC" SG_ 995 NetCfg_PSD_LT 21000;
BA_ "GenSigTimeout_RF_HUB" SG_ 995 NetCfg_PSD_LT 21000;
BA_ "FlexKomComment" SG_ 995 NetCfg_PSD_RT "Network ECU config data for interior";
BA_ "FlexKomIsMotorola" SG_ 995 NetCfg_PSD_RT 1;
BA_ "FlexKomSID" SG_ 995 NetCfg_PSD_RT 38;
BA_ "FlexKomSigLaenge" SG_ 995 NetCfg_PSD_RT 64;
BA_ "FlexKomSigName" SG_ 995 NetCfg_PSD_RT "NET_CFG_DATA_INT";
BA_ "FlexKomSigStartPos" SG_ 995 NetCfg_PSD_RT 7;
BA_ "FlexKomSigStartValue" SG_ 995 NetCfg_PSD_RT "0300000000000000h";
BA_ "GenSigCycleTime" SG_ 995 NetCfg_PSD_RT 2000;
BA_ "GenSigSendType" SG_ 995 NetCfg_PSD_RT 5;
BA_ "GenSigSNA" SG_ 995 NetCfg_PSD_RT "0h";
BA_ "GenSigTimeout_IC" SG_ 995 NetCfg_PSD_RT 21000;
BA_ "GenSigTimeout_RF_HUB" SG_ 995 NetCfg_PSD_RT 21000;
BA_ "FlexKomComment" SG_ 995 NetCfg_PTCM "Network ECU config data for interior";
BA_ "FlexKomIsMotorola" SG_ 995 NetCfg_PTCM 1;
BA_ "FlexKomSID" SG_ 995 NetCfg_PTCM 38;
BA_ "FlexKomSigLaenge" SG_ 995 NetCfg_PTCM 64;
BA_ "FlexKomSigName" SG_ 995 NetCfg_PTCM "NET_CFG_DATA_INT";
BA_ "FlexKomSigStartPos" SG_ 995 NetCfg_PTCM 7;
BA_ "FlexKomSigStartValue" SG_ 995 NetCfg_PTCM "0300000000000000h";
BA_ "GenSigCycleTime" SG_ 995 NetCfg_PTCM 2000;
BA_ "GenSigSendType" SG_ 995 NetCfg_PTCM 5;
BA_ "GenSigSNA" SG_ 995 NetCfg_PTCM "0h";
BA_ "GenSigTimeout_IC" SG_ 995 NetCfg_PTCM 21000;
BA_ "GenSigTimeout_RF_HUB" SG_ 995 NetCfg_PTCM 21000;
BA_ "FlexKomComment" SG_ 995 NetCfg_RBC "Network ECU config data for interior";
BA_ "FlexKomIsMotorola" SG_ 995 NetCfg_RBC 1;
BA_ "FlexKomSID" SG_ 995 NetCfg_RBC 38;
BA_ "FlexKomSigLaenge" SG_ 995 NetCfg_RBC 64;
BA_ "FlexKomSigName" SG_ 995 NetCfg_RBC "NET_CFG_DATA_INT";
BA_ "FlexKomSigStartPos" SG_ 995 NetCfg_RBC 7;
BA_ "FlexKomSigStartValue" SG_ 995 NetCfg_RBC "0300000000000000h";
BA_ "GenSigCycleTime" SG_ 995 NetCfg_RBC 2000;
BA_ "GenSigSendType" SG_ 995 NetCfg_RBC 5;
BA_ "GenSigSNA" SG_ 995 NetCfg_RBC "0h";
BA_ "GenSigTimeout_IC" SG_ 995 NetCfg_RBC 21000;
BA_ "GenSigTimeout_RF_HUB" SG_ 995 NetCfg_RBC 21000;
BA_ "FlexKomComment" SG_ 995 NetCfg_RBSS "Network ECU config data for interior";
BA_ "FlexKomIsMotorola" SG_ 995 NetCfg_RBSS 1;
BA_ "FlexKomSID" SG_ 995 NetCfg_RBSS 38;
BA_ "FlexKomSigLaenge" SG_ 995 NetCfg_RBSS 64;
BA_ "FlexKomSigName" SG_ 995 NetCfg_RBSS "NET_CFG_DATA_INT";
BA_ "FlexKomSigStartPos" SG_ 995 NetCfg_RBSS 7;
BA_ "FlexKomSigStartValue" SG_ 995 NetCfg_RBSS "0300000000000000h";
BA_ "GenSigCycleTime" SG_ 995 NetCfg_RBSS 2000;
BA_ "GenSigSendType" SG_ 995 NetCfg_RBSS 5;
BA_ "GenSigSNA" SG_ 995 NetCfg_RBSS "0h";
BA_ "GenSigTimeout_RF_HUB" SG_ 995 NetCfg_RBSS 21000;
BA_ "FlexKomComment" SG_ 995 NetCfg_TBM "Network ECU config data for interior";
BA_ "FlexKomIsMotorola" SG_ 995 NetCfg_TBM 1;
BA_ "FlexKomSID" SG_ 995 NetCfg_TBM 38;
BA_ "FlexKomSigLaenge" SG_ 995 NetCfg_TBM 64;
BA_ "FlexKomSigName" SG_ 995 NetCfg_TBM "NET_CFG_DATA_INT";
BA_ "FlexKomSigStartPos" SG_ 995 NetCfg_TBM 7;
BA_ "FlexKomSigStartValue" SG_ 995 NetCfg_TBM "0300000000000000h";
BA_ "GenSigCycleTime" SG_ 995 NetCfg_TBM 2000;
BA_ "GenSigSendType" SG_ 995 NetCfg_TBM 5;
BA_ "GenSigSNA" SG_ 995 NetCfg_TBM "0h";
BA_ "GenSigTimeout_RF_HUB" SG_ 995 NetCfg_TBM 21000;
BA_ "FlexKomComment" SG_ 995 NetCfg_TGW "Network ECU config data for interior";
BA_ "FlexKomIsMotorola" SG_ 995 NetCfg_TGW 1;
BA_ "FlexKomSID" SG_ 995 NetCfg_TGW 38;
BA_ "FlexKomSigLaenge" SG_ 995 NetCfg_TGW 64;
BA_ "FlexKomSigName" SG_ 995 NetCfg_TGW "NET_CFG_DATA_INT";
BA_ "FlexKomSigStartPos" SG_ 995 NetCfg_TGW 7;
BA_ "FlexKomSigStartValue" SG_ 995 NetCfg_TGW "0300000000000000h";
BA_ "GenSigCycleTime" SG_ 995 NetCfg_TGW 2000;
BA_ "GenSigSendType" SG_ 995 NetCfg_TGW 5;
BA_ "GenSigSNA" SG_ 995 NetCfg_TGW "0h";
BA_ "GenSigTimeout_IC" SG_ 995 NetCfg_TGW 21000;
BA_ "GenSigTimeout_RF_HUB" SG_ 995 NetCfg_TGW 21000;
BA_ "FlexKomComment" SG_ 995 NetCfg_TMM "Network ECU config data for interior";
BA_ "FlexKomIsMotorola" SG_ 995 NetCfg_TMM 1;
BA_ "FlexKomSID" SG_ 995 NetCfg_TMM 38;
BA_ "FlexKomSigLaenge" SG_ 995 NetCfg_TMM 64;
BA_ "FlexKomSigName" SG_ 995 NetCfg_TMM "NET_CFG_DATA_INT";
BA_ "FlexKomSigStartPos" SG_ 995 NetCfg_TMM 7;
BA_ "FlexKomSigStartValue" SG_ 995 NetCfg_TMM "0300000000000000h";
BA_ "GenSigCycleTime" SG_ 995 NetCfg_TMM 2000;
BA_ "GenSigSendType" SG_ 995 NetCfg_TMM 5;
BA_ "GenSigSNA" SG_ 995 NetCfg_TMM "0h";
BA_ "GenSigTimeout_RF_HUB" SG_ 995 NetCfg_TMM 21000;
BA_ "FlexKomComment" SG_ 995 NetCfg_TTM "Network ECU config data for interior";
BA_ "FlexKomIsMotorola" SG_ 995 NetCfg_TTM 1;
BA_ "FlexKomSID" SG_ 995 NetCfg_TTM 38;
BA_ "FlexKomSigLaenge" SG_ 995 NetCfg_TTM 64;
BA_ "FlexKomSigName" SG_ 995 NetCfg_TTM "NET_CFG_DATA_INT";
BA_ "FlexKomSigStartPos" SG_ 995 NetCfg_TTM 7;
BA_ "FlexKomSigStartValue" SG_ 995 NetCfg_TTM "0300000000000000h";
BA_ "GenSigCycleTime" SG_ 995 NetCfg_TTM 2000;
BA_ "GenSigSendType" SG_ 995 NetCfg_TTM 5;
BA_ "GenSigSNA" SG_ 995 NetCfg_TTM "0h";
BA_ "GenSigTimeout_RF_HUB" SG_ 995 NetCfg_TTM 21000;
BA_ "FlexKomComment" SG_ 995 NetCfg_VES2_I "Network ECU config data for interior";
BA_ "FlexKomIsMotorola" SG_ 995 NetCfg_VES2_I 1;
BA_ "FlexKomSID" SG_ 995 NetCfg_VES2_I 38;
BA_ "FlexKomSigLaenge" SG_ 995 NetCfg_VES2_I 64;
BA_ "FlexKomSigName" SG_ 995 NetCfg_VES2_I "NET_CFG_DATA_INT";
BA_ "FlexKomSigStartPos" SG_ 995 NetCfg_VES2_I 7;
BA_ "FlexKomSigStartValue" SG_ 995 NetCfg_VES2_I "0300000000000000h";
BA_ "GenSigCycleTime" SG_ 995 NetCfg_VES2_I 2000;
BA_ "GenSigSendType" SG_ 995 NetCfg_VES2_I 5;
BA_ "GenSigSNA" SG_ 995 NetCfg_VES2_I "0h";
BA_ "GenSigTimeout_RF_HUB" SG_ 995 NetCfg_VES2_I 21000;
BA_ "FlexKomComment" SG_ 995 NetCfg_VES3_I "Network ECU config data for interior";
BA_ "FlexKomIsMotorola" SG_ 995 NetCfg_VES3_I 1;
BA_ "FlexKomSID" SG_ 995 NetCfg_VES3_I 38;
BA_ "FlexKomSigLaenge" SG_ 995 NetCfg_VES3_I 64;
BA_ "FlexKomSigName" SG_ 995 NetCfg_VES3_I "NET_CFG_DATA_INT";
BA_ "FlexKomSigStartPos" SG_ 995 NetCfg_VES3_I 7;
BA_ "FlexKomSigStartValue" SG_ 995 NetCfg_VES3_I "0300000000000000h";
BA_ "GenSigCycleTime" SG_ 995 NetCfg_VES3_I 2000;
BA_ "GenSigSendType" SG_ 995 NetCfg_VES3_I 5;
BA_ "GenSigSNA" SG_ 995 NetCfg_VES3_I "0h";
BA_ "GenSigTimeout_RF_HUB" SG_ 995 NetCfg_VES3_I 21000;
BA_ "FlexKomComment" SG_ 995 NetCfg_VRM "Network ECU config data for interior";
BA_ "FlexKomIsMotorola" SG_ 995 NetCfg_VRM 1;
BA_ "FlexKomSID" SG_ 995 NetCfg_VRM 38;
BA_ "FlexKomSigLaenge" SG_ 995 NetCfg_VRM 64;
BA_ "FlexKomSigName" SG_ 995 NetCfg_VRM "NET_CFG_DATA_INT";
BA_ "FlexKomSigStartPos" SG_ 995 NetCfg_VRM 7;
BA_ "FlexKomSigStartValue" SG_ 995 NetCfg_VRM "0300000000000000h";
BA_ "GenSigCycleTime" SG_ 995 NetCfg_VRM 2000;
BA_ "GenSigSendType" SG_ 995 NetCfg_VRM 5;
BA_ "GenSigSNA" SG_ 995 NetCfg_VRM "0h";
BA_ "GenSigTimeout_RF_HUB" SG_ 995 NetCfg_VRM 21000;
BA_ "FlexKomComment" SG_ 995 NetCfg_VSIM "Network ECU config data for interior";
BA_ "FlexKomIsMotorola" SG_ 995 NetCfg_VSIM 1;
BA_ "FlexKomSID" SG_ 995 NetCfg_VSIM 38;
BA_ "FlexKomSigLaenge" SG_ 995 NetCfg_VSIM 64;
BA_ "FlexKomSigName" SG_ 995 NetCfg_VSIM "NET_CFG_DATA_INT";
BA_ "FlexKomSigStartPos" SG_ 995 NetCfg_VSIM 7;
BA_ "FlexKomSigStartValue" SG_ 995 NetCfg_VSIM "0300000000000000h";
BA_ "GenSigCycleTime" SG_ 995 NetCfg_VSIM 2000;
BA_ "GenSigSendType" SG_ 995 NetCfg_VSIM 5;
BA_ "GenSigSNA" SG_ 995 NetCfg_VSIM "0h";
BA_ "GenSigTimeout_IC" SG_ 995 NetCfg_VSIM 21000;
BA_ "GenSigTimeout_RF_HUB" SG_ 995 NetCfg_VSIM 21000;
BA_ "FlexKomComment" SG_ 995 NetCfg_VTM "Network ECU config data for interior";
BA_ "FlexKomIsMotorola" SG_ 995 NetCfg_VTM 1;
BA_ "FlexKomSID" SG_ 995 NetCfg_VTM 38;
BA_ "FlexKomSigLaenge" SG_ 995 NetCfg_VTM 64;
BA_ "FlexKomSigName" SG_ 995 NetCfg_VTM "NET_CFG_DATA_INT";
BA_ "FlexKomSigStartPos" SG_ 995 NetCfg_VTM 7;
BA_ "FlexKomSigStartValue" SG_ 995 NetCfg_VTM "0300000000000000h";
BA_ "GenSigCycleTime" SG_ 995 NetCfg_VTM 2000;
BA_ "GenSigSendType" SG_ 995 NetCfg_VTM 5;
BA_ "GenSigSNA" SG_ 995 NetCfg_VTM "0h";
BA_ "GenSigTimeout_RF_HUB" SG_ 995 NetCfg_VTM 21000;
VAL_ 300 EPSInternalVehSpeed 65535 "SNA" ;
VAL_ 300 EPS_AsstStat 0 "AST_ACT" 1 "AST_OFF" 2 "AST_RT" 7 "SNA" ;
VAL_ 300 EPS_Curr 255 "SNA" ;
VAL_ 300 EPS_ErrStat 0 "OK" 1 "ERR" 2 "ERR2" 3 "SERV_HI" 7 "SNA" ;
VAL_ 300 EPS_MODE_STAT 0 "MODE_1" 1 "MODE_2" 2 "MODE_3" 3 "LAST" 7 "SNA" ;
VAL_ 300 EPS_ModuleVoltage 255 "SNA" ;
VAL_ 300 EPS_Warn_Disp_Rq 0 "OK" 1 "ERR" 2 "ERR2" 3 "SERV_HI" 7 "SNA" ;
VAL_ 522 EPS_MotorTorqueAvailable 255 "SNA" ;
VAL_ 522 EPS_SDSTorqueApplied 2047 "SNA" ;
VAL_ 522 EPS_SteerAngle 32767 "SNA" ;
VAL_ 522 EPS_SteerVelocity 32767 "SNA" ;
VAL_ 320 BrkPdl_Stat 0 "UPSTOP" 1 "PSD" 2 "NDEF2" 3 "SNA" ;
VAL_ 320 Brk_Stat 0 "IDLE" 1 "BRAKING" 2 "NDEF2" 3 "SNA" ;
VAL_ 320 DTR_CC_Enabled 0 "SNA" ;
VAL_ 320 DTR_CC_Engaged 0 "SNA" ;
VAL_ 320 ESP_Sys_Stat 0 "ABSERR" 1 "NORM" 2 "HALF" 3 "ABGAS" ;
VAL_ 320 REF_VEH_SPEED 1023 "SNA" ;
VAL_ 320 RollTestMd_Actv 0 "OFF" 1 "ON" 2 "NDEF2" 3 "SNA" ;
VAL_ 320 SPCR_AS_Off_Rq 0 "IDLE" 1 "AS_TMP_OFF" 2 "AS_CNTS_OFF" 3 "SPCR_NA" ;
VAL_ 268 DAS_RqActv 0 "IDLE" 1 "LFC" 2 "CMS" 3 "ABA" 4 "LSCM" 5 "VJC_Open_Loop" 6 "RHSC_Override" 7 "SNA" ;
VAL_ 268 EngTrq_Rq_ESC 8191 "SNA" ;
VAL_ 331 BrkPrss_TMC 2047 "SNA" ;
VAL_ 331 HSA_BrkPrss 63 "SNA" ;
VAL_ 331 PTS_Brk_Rq_RspSts 0 "OFF" 1 "ACTIVE" 2 "FAULTED" 3 "SNA" ;
VAL_ 332 VehAccel_X 255 "SNA" ;
VAL_ 332 VehAccel_X_Offset 255 "SNA" ;
VAL_ 332 VehAccel_Y 255 "SNA" ;
VAL_ 332 VehAccel_Y_Offset 255 "SNA" ;
VAL_ 332 VehYawRate_Offset 255 "SNA" ;
VAL_ 332 VehYawRate_Raw 65535 "SNA" ;
VAL_ 292 WhlPlsCnt_FL 255 "SNA" ;
VAL_ 292 WhlPlsCnt_FR 255 "SNA" ;
VAL_ 292 WhlPlsCnt_RL 255 "SNA" ;
VAL_ 292 WhlPlsCnt_RR 255 "SNA" ;
VAL_ 344 WhlDir_FL_Stat 0 "VOID" 1 "FORWARD" 2 "BACKWARD" 3 "SNA" ;
VAL_ 344 WhlDir_FR_Stat 0 "VOID" 1 "FORWARD" 2 "BACKWARD" 3 "SNA" ;
VAL_ 344 WhlDir_RL_Stat 0 "VOID" 1 "FORWARD" 2 "BACKWARD" 3 "SNA" ;
VAL_ 344 WhlDir_RR_Stat 0 "VOID" 1 "FORWARD" 2 "BACKWARD" 3 "SNA" ;
VAL_ 344 WhlRPM_FL 16383 "SNA" ;
VAL_ 344 WhlRPM_FR 16383 "SNA" ;
VAL_ 344 WhlRPM_RL 16383 "SNA" ;
VAL_ 344 WhlRPM_RR 16383 "SNA" ;
VAL_ 284 BrkTrq 4095 "SNA" ;
VAL_ 284 BrkTrq_D 4095 "SNA" ;
VAL_ 284 VEH_SPEED 65535 "SNA" ;
VAL_ 270 AHH_Status 0 "Not_Ready" 1 "Ready" 2 "Active" 3 "EPB_Ready" 4 "HYD_Ready" 7 "SNA" ;
VAL_ 270 WhlTrq_Rq_As 32767 "SNA" ;
VAL_ 270 WhlTrq_Rq_ESC 32767 "SNA" ;
VAL_ 736 ABS_IndLmp_On_Rq 0 "OFF" 1 "CONT" 2 "BLINK" 3 "SNA" ;
VAL_ 736 BrkIndLmp_On_Rq_ESC 0 "OFF" 1 "CONT" 2 "BLINK" 3 "SNA" ;
VAL_ 736 ESC_CtrlLmp_Info 0 "OFF" 1 "CONT" 2 "BLINK" 3 "SNA" ;
VAL_ 736 ESP_Off_IndLmp_On_Rq 0 "SNA" ;
VAL_ 736 LT_DIST 65535 "SNA" ;
VAL_ 736 RT_DIST 65535 "SNA" ;
VAL_ 840 FailSafeError 65535 "SNA" ;
VAL_ 710 EC_ECUCfg17_Stat 0 "NA" 1 "PROGAMMED" 2 "REQUEST_DATA" 3 "SNA" ;
VAL_ 1013 EC_ECUCfg6_Stat 0 "NA" 1 "PROGAMMED" 2 "REQUEST_DATA" 3 "SNA" ;
VAL_ 1015 EC_ECUCfg8_Stat 0 "NA" 1 "PROGAMMED" 2 "REQUEST_DATA" 3 "SNA" ;
VAL_ 816 HVAC_CLNT_FLW_MIN 0 "OPEN" 254 "CLOSE" 255 "SNA" ;
VAL_ 816 PLG_Stat 0 "OK" 1 "UNLK" 2 "PK" 3 "DSBL" 4 "CLS_FG" 5 "OBS_DET" 6 "MAN_CLS" 7 "COLD" 8 "HOT" 10 "HF_CNTMNTD" 11 "RMP_OBS" 12 "RMP_SRVC" 13 "RMP_STOPPED" 14 "RMP_DPLY" 15 "RMP_STOW" ;
VAL_ 678 DispPopupSts 0 "NONE" 1 "MESS1" 2 "MESS2" 3 "MESS3" 4 "MESS4" 5 "MESS5" 6 "MESS6" 7 "MESS7" 8 "MESS8" 9 "MESS9" 10 "MESS10" 11 "MESS11" 12 "MESS12" 13 "MESS13" 14 "MESS14" 15 "MESS15" 16 "MESS16" 17 "MESS17" 18 "MESS18" 19 "MESS19" 20 "MESS20" 21 "MESS21" 22 "MESS22" 255 "SNA" ;
VAL_ 678 DisplaySts 0 "OFF" 1 "MESS1" 2 "MESS2" 3 "MESS3" 4 "MESS4" 5 "MESS5" 6 "MESS6" 7 "MESS7" 8 "MESS8" 9 "MESS9" 10 "MESS10" 11 "MESS11" 12 "MESS12" 97 "MESS13" 98 "MESS14" 99 "MESS15" 100 "ESS16" 101 "ESS17" 102 "MESS18" 103 "ESS19" 104 "MESS20" 105 "ESS21" 106 "MESS22" 107 "MESS23" 108 "MESS24" 160 "MESS25" 161 "MESS26" 240 "MESS27" 255 "SNA" ;
VAL_ 678 HALF_CHIME_TYPESts 0 "NONE" 2 "HALF_MAS" 6 "HALF" 15 "SNA" ;
VAL_ 678 ISO_TelltaleSts 0 "OFF" 1 "WHITE" 2 "GREEN" 3 "YELLOW" 4 "YELLOW_F" 7 "SNA" ;
VAL_ 678 SensitivitySts 0 "OFF" 1 "S1" 2 "S2" 3 "S3" 4 "S4" 5 "S5" 7 "SNA" ;
VAL_ 678 TrqIntensitySts 0 "OFF" 1 "T1" 2 "T2" 3 "T3" 7 "SNA" ;
VAL_ 658 MTO_HALFDriveStyleSts 0 "NORMAL" 1 "CITY" 2 "SPORT" 3 "WINTER" 4 "SPORT_PLUS" 5 "TRACPLUS" 7 "SNA" ;
VAL_ 729 ConfigSts 0 "LEAST" 1 "LESS" 2 "MID" 3 "MORE" 4 "MOST" 7 "SNA" ;
VAL_ 729 LDW_LEDControlSts 0 "OFF" 1 "CONT" 2 "BLINK" 3 "SNA" ;
VAL_ 729 TorqueIntensitySts 0 "T1" 1 "T2" 2 "T3" 7 "SNA" ;
VAL_ 701 BatPwrUsage_V 0 "Valid" 1 "Not_Valid" ;
VAL_ 701 Est_Range 255 "SNA" ;
VAL_ 701 HEV_LMP_RQ 0 "OFF" 1 "ON" 2 "BLINK" 3 "SNA" ;
VAL_ 701 R134a_PressSts 511 "SNA" ;
VAL_ 655 CabinPreCondReqStat 0 "DEFAULT" 1 "PRE" 2 "SPR" 3 "PRE_OFF" 4 "PRF" 5 "NOT_OK" 6 "BCC" 7 "BCS" 15 "SNA" ;
VAL_ 655 ChargingLevel 0 "Default_NoLevel" 1 "Level_1_AC" 2 "Level_2_AC" 3 "Level_3_AC" 4 "Level_1_DC" 5 "Level_2_DC" 6 "PlugInNotDet" 7 "PPI_1_No_Drive" 8 "PPI_2_OK_Drive" 15 "SNA" ;
VAL_ 655 ChargingSysSts 0 "NotCharging" 1 "Charging" 2 "ChargeInterrupted" 3 "ChargeComplete" 7 "SNA" ;
VAL_ 655 CompStat 0 "NormalOperation" 1 "DegradedOperation" 2 "Inoperative" 3 "Reserved1" 4 "Reserved2" 5 "Reserved3" 6 "Reserved4" 15 "SNA" ;
VAL_ 655 EstTimeofChrg_Lv1 8191 "SNA" ;
VAL_ 655 EstTimeofChrg_Lv2 2047 "SNA" ;
VAL_ 655 HVBatCntctrStat 0 "Open" 1 "Precharging" 2 "Closed" 3 "Precharge_Failed" 4 "Precharge_Inhibited" 7 "SNA" ;
VAL_ 655 HtrCoreInletTemp 255 "SNA" ;
VAL_ 655 MIL_OnRq_BPCM 0 "FALSE" 1 "TRUE" ;
VAL_ 291 AHH_Apply_Release_Request 0 "No_Request" 1 "Apply" 2 "Blend_Release" 3 "Spare" 4 "Fast torque release" 5 "Apply_EPB" 6 "Apply_HYD" 7 "SNA" ;
VAL_ 291 M_MAX_AXLE 8191 "SNA" ;
VAL_ 291 M_MIN_AXLE 8191 "SNA" ;
VAL_ 291 M_STA_AXLE 8191 "SNA" ;
VAL_ 784 AvgFuelLvl 511 "SNA" ;
VAL_ 784 ODO 16777215 "SNA" ;
VAL_ 784 PTS_MODE_SELECTION 0 "None" 1 "PARA" 2 "PERP" 3 "PULL_OUT" 4 "OVER" 7 "SNA" ;
VAL_ 784 SRS_LMP_STAT 0 "SRS_LMP_OFF" 1 "SRS_LMP_ON" 2 "SRS_LMP_ON_IC" 3 "SNA" ;
VAL_ 882 CapacityUnit 0 "L" 1 "G_UK" 2 "G_US" ;
VAL_ 882 ConsumptionUnit 0 "KMPL" 1 "LP100KM" 2 "MPG_UK" 3 "MPG_US" 7 "SNA" ;
VAL_ 882 LANG_C 0 "GERMAN" 1 "US_ENGLISH" 2 "FRENCH" 3 "ITALIAN" 4 "SPANISH" 5 "JAPANESE" 6 "PORTUGESE" 7 "DUTCH" 8 "UK_ENGLISH" 9 "MANDARIN_S" 10 "RUSSIAN" 11 "KOREAN" 12 "ARABIC" 13 "BRAZILIAN" 14 "MANDARIN_T" 15 "HINDI" 16 "TURKISH" 17 "POLISH" 31 "LANG_NO_CHG" ;
VAL_ 882 PowerUnit 0 "KW" 1 "HP_UK" 2 "HP_US" ;
VAL_ 882 PressureUnit 0 "KPA" 1 "BAR" 2 "PSI" ;
VAL_ 995 NET_CFG_STAT_INT 0 "NA" 1 "PROGAMMED" 2 "REQUEST_DATA" 3 "SNA" ;
VAL_ 995 NetCfg_ANC_I 0 "Not_Present" 1 "Present" ;
VAL_ 995 NetCfg_TTM 0 "Not_Present" 1 "Present" ;
